VERSION ""

NS_ :

BS_:

BU_: SGW PBWM IDCM EVCU2 ECM DMPI BPCM AGSM

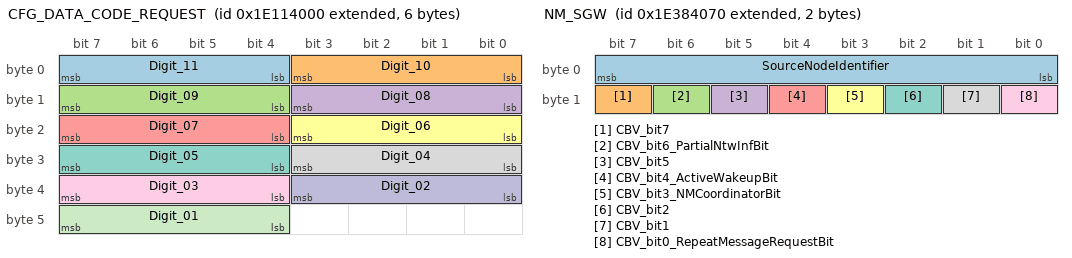
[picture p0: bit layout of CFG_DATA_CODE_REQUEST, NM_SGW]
BO_ 2651930624 CFG_DATA_CODE_REQUEST: 6 EVCU2
 SG_ Digit_11 : 7|4@0+ (1,0) [0|15] "" DMPI,PBWM
 SG_ Digit_10 : 3|4@0+ (1,0) [0|15] "" DMPI,PBWM
 SG_ Digit_09 : 15|4@0+ (1,0) [0|15] "" DMPI,PBWM
 SG_ Digit_08 : 11|4@0+ (1,0) [0|15] "" DMPI,PBWM
 SG_ Digit_07 : 23|4@0+ (1,0) [0|15] "" DMPI,PBWM
 SG_ Digit_06 : 19|4@0+ (1,0) [0|15] "" DMPI,PBWM
 SG_ Digit_05 : 31|4@0+ (1,0) [0|15] "" DMPI,PBWM
 SG_ Digit_04 : 27|4@0+ (1,0) [0|15] "" DMPI,PBWM
 SG_ Digit_03 : 39|4@0+ (1,0) [0|15] "" DMPI,PBWM
 SG_ Digit_02 : 35|4@0+ (1,0) [0|15] "" DMPI,PBWM
 SG_ Digit_01 : 47|4@0+ (1,0) [0|15] "" DMPI,PBWM

BO_ 2564554481 DIAGNOSTIC_REQUEST_FUNCTIONAL: 8 SGW
 SG_ N_PDU : 7|64@0+ (1,0) [0|0] "" DMPI,PBWM,IDCM,BPCM

BO_ 2564502513 DIAGNOSTIC_REQUEST_FUNC_OBD: 8 SGW
 SG_ N_PDU : 7|64@0+ (1,0) [0|0] "" DMPI,PBWM,EVCU2,IDCM,BPCM,ECM

BO_ 2564485444 DIAGNOSTIC_RESPONSE_BPCM: 8 BPCM
 SG_ N_PDU : 7|64@0+ (1,0) [0|0] "" SGW

BO_ 2564441329 DIAGNOSTIC_REQUEST_BPCM: 8 SGW
 SG_ N_PDU : 7|64@0+ (1,0) [0|0] "" BPCM

BO_ 2564485456 DIAGNOSTIC_RESPONSE_IDCM: 8 IDCM
 SG_ N_PDU : 7|64@0+ (1,0) [0|0] "" SGW

BO_ 2564444401 DIAGNOSTIC_REQUEST_IDCM: 8 SGW
 SG_ N_PDU : 7|64@0+ (1,0) [0|0] "" IDCM

BO_ 1053 VIN: 32 EVCU2
 SG_ VIN_MSG : 75|2@0+ (1,0) [0|3] "" IDCM
 SG_ VIN_DATA : 87|56@0+ (1,0) [0|72057594037927900] "" IDCM

BO_ 156 TELEMATIC_FD_1: 32 EVCU2
 SG_ GPS_UTC_Second : 151|16@0+ (0.01,0) [0|59.99] "s"  DMPI,IDCM,BPCM
 SG_ GPS_UTC_Minute : 47|8@0+ (1,0) [0|59] "min"  DMPI,IDCM,BPCM
 SG_ GPS_UTC_Hour : 55|8@0+ (1,0) [0|23] "h"  DMPI,IDCM,BPCM
 SG_ GPS_Date_Year : 167|16@0+ (1,0) [0|65534] "Years"  DMPI,IDCM,BPCM
 SG_ GPS_Date_Month : 71|8@0+ (1,0) [1|12] "Months"  DMPI,IDCM,BPCM
 SG_ GPS_Date_Day : 63|8@0+ (1,0) [1|31] "Days"  DMPI,IDCM,BPCM

BO_ 1058 OBD_CONTENT_FRAME: 32 ECM
 SG_ EngLoad_OBD_ePT : 31|8@0+ (0.3922,0) [0|100] "%" EVCU2
 SG_ LoadOBD : 87|8@0+ (0.3922,0) [0|100] "%"  DMPI
 SG_ CarbWarmUp : 93|1@0+ (1,0) [0|1] "-"  DMPI
 SG_ OAT_PT_EstV : 60|1@0+ (1,0) [0|0] "-"  EVCU2
 SG_ OAT_PT_Est : 55|8@0+ (1,-64) [-64|191] "°C"  EVCU2
 SG_ EngOffTmPTV : 5|1@0+ (1,0) [0|0] "-"  EVCU2
 SG_ EngOffTmPT : 3|12@0+ (0.5,0) [0.5|2047.5] "min"  EVCU2
 SG_ MessageCounter_OBDCONTENTFRAME : 179|4@0+ (1,0) [0|15] "-"  EVCU2,BPCM
 SG_ CRC_OBDCONTENTFRAME : 191|8@0+ (1,0) [0|255] "-"  EVCU2,BPCM

BO_ 1829 IPC_FD_1: 32 EVCU2
 SG_ TotalOdometer : 75|20@0+ (1,0) [0|1048575] "km"  IDCM

BO_ 1626 IMPACT_INFO: 32 EVCU2
 SG_ IMPACTConfirm : 81|1@0+ (1,0) [0|1] "-"  DMPI,IDCM,BPCM
 SG_ IMPACTCommand : 80|1@0+ (1,0) [0|1] "-"  DMPI,IDCM,BPCM
 SG_ MessageCounter_IMPACTINFO : 179|4@0+ (1,0) [0|15] "-"  DMPI,IDCM,BPCM
 SG_ CRC_IMPACTINFO : 191|8@0+ (1,0) [0|255] "-"  DMPI,IDCM,BPCM

BO_ 751 ENGINE_FD_6: 32 ECM
 SG_ EngineWaterTemp : 95|8@0+ (1,-40) [-40|215] "°C"  Vector__XXX

BO_ 518 ENGINE_FD_5: 32 ECM
 SG_ RPMOverRev_W : 115|1@0+ (1,0) [0|1] "-"  EVCU2
 SG_ MessageCounter_ENGINE5 : 179|4@0+ (1,0) [0|15] "-"  EVCU2
 SG_ ECM_READINESS_RESET_W : 140|1@0+ (1,0) [0|0] ""  DMPI,BPCM
 SG_ ECM_CODE_CLR_W : 141|1@0+ (1,0) [0|0] ""  DMPI,BPCM
 SG_ CRC_ENGINE5 : 191|8@0+ (1,0) [0|255] "-"  EVCU2

BO_ 2564485648 DIAGNOSTIC_RESPONSE_FD_ECM: 64 ECM
 SG_ N_PDU : 7|64@0+ (1,0) [0|0] "" SGW

BO_ 2564554482 DIAGNOSTIC_REQUEST_FD_FUNCTIONAL: 64 SGW
 SG_ N_PDU : 7|64@0+ (1,0) [0|0] "" DMPI,PBWM,EVCU2,IDCM,BPCM,ECM

BO_ 2564428018 DIAGNOSTIC_REQUEST_FD_ECM: 64 SGW
 SG_ N_PDU : 7|64@0+ (1,0) [0|0] "" ECM

BO_ 1066 BCM_FD_9: 32 EVCU2
 SG_ ExternalTemperature : 0|9@0+ (0.5,-85) [-85|170] "°C"  IDCM,BPCM

BO_ 1827 BCM_FD_7: 32 EVCU2
 SG_ IgnitionOnCounter : 95|16@0+ (1,0) [0|65535] "-"  IDCM,BPCM

BO_ 1153 BCM_FD_10: 32 EVCU2
 SG_ ExternalTemperatureC : 80|9@0+ (0.5,-85) [-85|170] "°C"  IDCM,BPCM
 SG_ CmdIgnSts : 138|3@0+ (1,0) [0|7] "" IDCM,BPCM

BO_ 753 LV_CHARGER1: 32 IDCM
 SG_ MessageCounter_LV_CHARGER1 : 179|4@0+ (1,0) [0|15] "-"  Vector__XXX
 SG_ CRC_LV_CHARGER1 : 191|8@0+ (1,0) [0|255] "-"  Vector__XXX
 SG_ IDCM_Wakeup_HCP : 23|1@0+ (1,0) [0|1] "-"  EVCU2

BO_ 1032 HYBRID_THERMAL_COMMAND: 32 EVCU2
 SG_ RadiatorFanSts : 78|7@0+ (1,0) [0|100] "%"  DMPI,ECM

BO_ 267 HYBRID_SYSTEM_EPT1: 32 EVCU2
 SG_ HCP_ShutdownCommand : 6|3@0+ (1,0) [0|0] "-"  BPCM
 SG_ WU_Timer_Value : 23|16@0+ (1,0) [0|65535] "min"  IDCM,BPCM
 SG_ PerWakeUp_Diag : 33|10@0+ (1,0) [0|1023] "-"  IDCM,BPCM

BO_ 1033 HYBRID_POWERTRAIN5: 32 EVCU2
 SG_ IdleCLoopTrq : 33|10@0+ (0.32,-163.52) [-163.52|163.52] "Nm"  ECM
 SG_ HEV_HybPwrtrnRdcdPerfCmnd : 22|1@0+ (1,0) [0|0] "-"  ECM
 SG_ HCPMaxEngRPM : 63|8@0+ (32,0) [0|8128] "rpm"  ECM
 SG_ MessageCounter_HYBRID_POWERTRAI : 179|4@0+ (1,0) [0|15] "-"  ECM
 SG_ CRC_HYBRID_POWERTRAIN5 : 191|8@0+ (1,0) [0|255] "-"  ECM
 SG_ Hybrid_EVT_ModeSts : 7|1@0+ (1,0) [0|1] "-"  Vector__XXX
 SG_ HCP_HoodAjar : 35|2@0+ (1,0) [0|2] "" ECM

BO_ 266 HVBATTERY1: 32 BPCM
 SG_ REPRGD_PFC_CLR_BPCM : 180|1@0+ (1,0) [0|0] "-"  ECM
 SG_ CODE_CLR_BPCM : 181|1@0+ (1,0) [0|0] "-"  ECM

BO_ 1839 HVBATTERY_RM_MODS1: 48 BPCM
 SG_ HVBatModuleTemp_16 : 127|8@0+ (1,-40) [-40|215] "°C"  SGW
 SG_ HVBatModuleTemp_15 : 119|8@0+ (1,-40) [-40|215] "°C"  SGW
 SG_ HVBatModuleTemp_14 : 111|8@0+ (1,-40) [-40|215] "°C"  SGW
 SG_ HVBatModuleTemp_13 : 103|8@0+ (1,-40) [-40|215] "°C"  SGW
 SG_ HVBatModuleTemp_12 : 95|8@0+ (1,-40) [-40|215] "°C"  SGW
 SG_ HVBatModuleTemp_11 : 87|8@0+ (1,-40) [-40|215] "°C"  SGW
 SG_ HVBatModuleTemp_10 : 79|8@0+ (1,-40) [-40|215] "°C"  SGW
 SG_ HVBatModuleTemp_09 : 71|8@0+ (1,-40) [-40|215] "°C"  SGW
 SG_ HVBatModuleTemp_08 : 63|8@0+ (1,-40) [-40|215] "°C"  SGW
 SG_ HVBatModuleTemp_07 : 55|8@0+ (1,-40) [-40|215] "°C"  SGW
 SG_ HVBatModuleTemp_06 : 47|8@0+ (1,-40) [-40|215] "°C"  SGW
 SG_ HVBatModuleTemp_05 : 39|8@0+ (1,-40) [-40|215] "°C"  SGW
 SG_ HVBatModuleTemp_04 : 31|8@0+ (1,-40) [-40|215] "°C"  SGW
 SG_ HVBatModuleTemp_03 : 23|8@0+ (1,-40) [-40|215] "°C"  SGW
 SG_ HVBatModuleTemp_02 : 15|8@0+ (1,-40) [-40|215] "°C"  SGW
 SG_ HVBatModuleTemp_01 : 7|8@0+ (1,-40) [-40|215] "°C"  SGW
 SG_ HVBatModuleTemp_38 : 303|8@0+ (1,-40) [-40|215] "°C"  Vector__XXX
 SG_ HVBatModuleTemp_37 : 295|8@0+ (1,-40) [-40|215] "°C"  Vector__XXX
 SG_ HVBatModuleTemp_36 : 287|8@0+ (1,-40) [-40|215] "°C"  Vector__XXX
 SG_ HVBatModuleTemp_35 : 279|8@0+ (1,-40) [-40|215] "°C"  Vector__XXX
 SG_ HVBatModuleTemp_34 : 271|8@0+ (1,-40) [-40|215] "°C"  Vector__XXX
 SG_ HVBatModuleTemp_33 : 263|8@0+ (1,-40) [-40|215] "°C"  Vector__XXX
 SG_ HVBatModuleTemp_32 : 255|8@0+ (1,-40) [-40|215] "°C"  Vector__XXX
 SG_ HVBatModuleTemp_31 : 247|8@0+ (1,-40) [-40|215] "°C"  Vector__XXX
 SG_ HVBatModuleTemp_30 : 239|8@0+ (1,-40) [-40|215] "°C"  Vector__XXX
 SG_ HVBatModuleTemp_29 : 231|8@0+ (1,-40) [-40|215] "°C"  Vector__XXX
 SG_ HVBatModuleTemp_28 : 223|8@0+ (1,-40) [-40|215] "°C"  Vector__XXX
 SG_ HVBatModuleTemp_27 : 215|8@0+ (1,-40) [-40|215] "°C"  Vector__XXX
 SG_ HVBatModuleTemp_26 : 207|8@0+ (1,-40) [-40|215] "°C"  Vector__XXX
 SG_ HVBatModuleTemp_25 : 199|8@0+ (1,-40) [-40|215] "°C"  Vector__XXX
 SG_ HVBatModuleTemp_24 : 191|8@0+ (1,-40) [-40|215] "°C"  Vector__XXX
 SG_ HVBatModuleTemp_23 : 183|8@0+ (1,-40) [-40|215] "°C"  Vector__XXX
 SG_ HVBatModuleTemp_22 : 175|8@0+ (1,-40) [-40|215] "°C"  Vector__XXX
 SG_ HVBatModuleTemp_21 : 167|8@0+ (1,-40) [-40|215] "°C"  Vector__XXX
 SG_ HVBatModuleTemp_20 : 159|8@0+ (1,-40) [-40|215] "°C"  Vector__XXX
 SG_ HVBatModuleTemp_19 : 151|8@0+ (1,-40) [-40|215] "°C"  Vector__XXX
 SG_ HVBatModuleTemp_18 : 143|8@0+ (1,-40) [-40|215] "°C"  Vector__XXX
 SG_ HVBatModuleTemp_17 : 135|8@0+ (1,-40) [-40|215] "°C"  Vector__XXX

BO_ 1840 HVBATTERY_RM_CHARGING1: 32 BPCM
 SG_ IsolationResistance : 7|16@0+ (1,0) [0|65534] "kOhm"  SGW
 SG_ Warning_SOCJump : 24|1@0+ (1,0) [0|1] "-"  SGW
 SG_ Warning_PackUnmatched : 27|1@0+ (1,0) [0|1] "-"  SGW
 SG_ Warning_PackUndervoltage : 19|1@0+ (1,0) [0|1] "-"  SGW
 SG_ Warning_PackTempHigh : 26|1@0+ (1,0) [0|1] "-"  EVCU2,SGW
 SG_ Warning_PackTempDiff : 25|1@0+ (1,0) [0|1] "-"  SGW
 SG_ Warning_PackOvervoltage : 20|1@0+ (1,0) [0|1] "-"  SGW
 SG_ Warning_Overcharging : 21|1@0+ (1,0) [0|1] "-"  SGW
 SG_ Warning_LowSOC : 22|1@0+ (1,0) [0|1] "-"  SGW
 SG_ Warning_Insulation : 28|1@0+ (1,0) [0|1] "-"  SGW
 SG_ Warning_HVIL : 29|1@0+ (1,0) [0|1] "-"  SGW
 SG_ Warning_HighSOC : 23|1@0+ (1,0) [0|1] "-"  SGW
 SG_ Warning_CellUndervoltage : 17|1@0+ (1,0) [0|1] "-"  SGW
 SG_ Warning_CellOvervoltage : 18|1@0+ (1,0) [0|1] "-"  SGW
 SG_ Warning_CellBalance : 16|1@0+ (1,0) [0|1] "-"  SGW
 SG_ HighestWarningLevel : 39|2@0+ (1,0) [0|3] "-"  SGW

BO_ 1838 HVBATTERY_RM_CELLS4: 64 BPCM
 SG_ HVBatCellVoltage_Cell096 : 228|13@0+ (0.001,0) [0|5] "V"  SGW
 SG_ HVBatCellVoltage_Cell095 : 212|13@0+ (0.001,0) [0|5] "V"  SGW
 SG_ HVBatCellVoltage_Cell094 : 196|13@0+ (0.001,0) [0|5] "V"  SGW
 SG_ HVBatCellVoltage_Cell093 : 180|13@0+ (0.001,0) [0|5] "V"  SGW
 SG_ HVBatCellVoltage_Cell092 : 164|13@0+ (0.001,0) [0|5] "V"  SGW
 SG_ HVBatCellVoltage_Cell091 : 148|13@0+ (0.001,0) [0|5] "V"  SGW
 SG_ HVBatCellVoltage_Cell090 : 132|13@0+ (0.001,0) [0|5] "V"  SGW
 SG_ HVBatCellVoltage_Cell089 : 116|13@0+ (0.001,0) [0|5] "V"  SGW
 SG_ HVBatCellVoltage_Cell088 : 100|13@0+ (0.001,0) [0|5] "V"  SGW
 SG_ HVBatCellVoltage_Cell087 : 84|13@0+ (0.001,0) [0|5] "V"  SGW
 SG_ HVBatCellVoltage_Cell086 : 68|13@0+ (0.001,0) [0|5] "V"  SGW
 SG_ HVBatCellVoltage_Cell085 : 52|13@0+ (0.001,0) [0|5] "V"  SGW
 SG_ HVBatCellVoltage_Cell084 : 36|13@0+ (0.001,0) [0|5] "V"  SGW
 SG_ HVBatCellVoltage_Cell083 : 20|13@0+ (0.001,0) [0|5] "V"  SGW
 SG_ HVBatCellVoltage_Cell082 : 4|13@0+ (0.001,0) [0|5] "V"  SGW
 SG_ HVBatCellVoltage_Cell108 : 420|13@0+ (0.001,0) [0|5] "V"  SGW
 SG_ HVBatCellVoltage_Cell107 : 404|13@0+ (0.001,0) [0|5] "V"  SGW
 SG_ HVBatCellVoltage_Cell106 : 388|13@0+ (0.001,0) [0|5] "V"  SGW
 SG_ HVBatCellVoltage_Cell105 : 372|13@0+ (0.001,0) [0|5] "V"  SGW
 SG_ HVBatCellVoltage_Cell104 : 356|13@0+ (0.001,0) [0|5] "V"  SGW
 SG_ HVBatCellVoltage_Cell103 : 340|13@0+ (0.001,0) [0|5] "V"  SGW
 SG_ HVBatCellVoltage_Cell102 : 324|13@0+ (0.001,0) [0|5] "V"  SGW
 SG_ HVBatCellVoltage_Cell101 : 308|13@0+ (0.001,0) [0|5] "V"  SGW
 SG_ HVBatCellVoltage_Cell100 : 292|13@0+ (0.001,0) [0|5] "V"  SGW
 SG_ HVBatCellVoltage_Cell099 : 276|13@0+ (0.001,0) [0|5] "V"  SGW
 SG_ HVBatCellVoltage_Cell098 : 260|13@0+ (0.001,0) [0|5] "V"  SGW
 SG_ HVBatCellVoltage_Cell097 : 244|13@0+ (0.001,0) [0|5] "V"  SGW

BO_ 1837 HVBATTERY_RM_CELLS3: 64 BPCM
 SG_ HVBatCellVoltage_Cell081 : 420|13@0+ (0.001,0) [0|5] "V"  SGW
 SG_ HVBatCellVoltage_Cell080 : 404|13@0+ (0.001,0) [0|5] "V"  SGW
 SG_ HVBatCellVoltage_Cell079 : 388|13@0+ (0.001,0) [0|5] "V"  SGW
 SG_ HVBatCellVoltage_Cell078 : 372|13@0+ (0.001,0) [0|5] "V"  SGW
 SG_ HVBatCellVoltage_Cell077 : 356|13@0+ (0.001,0) [0|5] "V"  SGW
 SG_ HVBatCellVoltage_Cell076 : 340|13@0+ (0.001,0) [0|5] "V"  SGW
 SG_ HVBatCellVoltage_Cell075 : 324|13@0+ (0.001,0) [0|5] "V"  SGW
 SG_ HVBatCellVoltage_Cell074 : 308|13@0+ (0.001,0) [0|5] "V"  SGW
 SG_ HVBatCellVoltage_Cell073 : 292|13@0+ (0.001,0) [0|5] "V"  SGW
 SG_ HVBatCellVoltage_Cell072 : 276|13@0+ (0.001,0) [0|5] "V"  SGW
 SG_ HVBatCellVoltage_Cell071 : 260|13@0+ (0.001,0) [0|5] "V"  SGW
 SG_ HVBatCellVoltage_Cell070 : 244|13@0+ (0.001,0) [0|5] "V"  SGW
 SG_ HVBatCellVoltage_Cell069 : 228|13@0+ (0.001,0) [0|5] "V"  SGW
 SG_ HVBatCellVoltage_Cell068 : 212|13@0+ (0.001,0) [0|5] "V"  SGW
 SG_ HVBatCellVoltage_Cell067 : 196|13@0+ (0.001,0) [0|5] "V"  SGW
 SG_ HVBatCellVoltage_Cell066 : 180|13@0+ (0.001,0) [0|5] "V"  SGW
 SG_ HVBatCellVoltage_Cell065 : 164|13@0+ (0.001,0) [0|5] "V"  SGW
 SG_ HVBatCellVoltage_Cell064 : 148|13@0+ (0.001,0) [0|5] "V"  SGW
 SG_ HVBatCellVoltage_Cell063 : 132|13@0+ (0.001,0) [0|5] "V"  SGW
 SG_ HVBatCellVoltage_Cell062 : 116|13@0+ (0.001,0) [0|5] "V"  SGW
 SG_ HVBatCellVoltage_Cell061 : 100|13@0+ (0.001,0) [0|5] "V"  SGW
 SG_ HVBatCellVoltage_Cell060 : 84|13@0+ (0.001,0) [0|5] "V"  SGW
 SG_ HVBatCellVoltage_Cell059 : 68|13@0+ (0.001,0) [0|5] "V"  SGW
 SG_ HVBatCellVoltage_Cell058 : 52|13@0+ (0.001,0) [0|5] "V"  SGW
 SG_ HVBatCellVoltage_Cell057 : 36|13@0+ (0.001,0) [0|5] "V"  SGW
 SG_ HVBatCellVoltage_Cell056 : 20|13@0+ (0.001,0) [0|5] "V"  SGW
 SG_ HVBatCellVoltage_Cell055 : 4|13@0+ (0.001,0) [0|5] "V"  SGW

BO_ 1836 HVBATTERY_RM_CELLS2: 64 BPCM
 SG_ HVBatCellVoltage_Cell054 : 420|13@0+ (0.001,0) [0|5] "V"  SGW
 SG_ HVBatCellVoltage_Cell053 : 404|13@0+ (0.001,0) [0|5] "V"  SGW
 SG_ HVBatCellVoltage_Cell052 : 388|13@0+ (0.001,0) [0|5] "V"  SGW
 SG_ HVBatCellVoltage_Cell051 : 372|13@0+ (0.001,0) [0|5] "V"  SGW
 SG_ HVBatCellVoltage_Cell050 : 356|13@0+ (0.001,0) [0|5] "V"  SGW
 SG_ HVBatCellVoltage_Cell049 : 340|13@0+ (0.001,0) [0|5] "V"  SGW
 SG_ HVBatCellVoltage_Cell048 : 324|13@0+ (0.001,0) [0|5] "V"  SGW
 SG_ HVBatCellVoltage_Cell047 : 308|13@0+ (0.001,0) [0|5] "V"  SGW
 SG_ HVBatCellVoltage_Cell046 : 292|13@0+ (0.001,0) [0|5] "V"  SGW
 SG_ HVBatCellVoltage_Cell045 : 276|13@0+ (0.001,0) [0|5] "V"  SGW
 SG_ HVBatCellVoltage_Cell044 : 260|13@0+ (0.001,0) [0|5] "V"  SGW
 SG_ HVBatCellVoltage_Cell043 : 244|13@0+ (0.001,0) [0|5] "V"  SGW
 SG_ HVBatCellVoltage_Cell042 : 228|13@0+ (0.001,0) [0|5] "V"  SGW
 SG_ HVBatCellVoltage_Cell041 : 212|13@0+ (0.001,0) [0|5] "V"  SGW
 SG_ HVBatCellVoltage_Cell040 : 196|13@0+ (0.001,0) [0|5] "V"  SGW
 SG_ HVBatCellVoltage_Cell039 : 180|13@0+ (0.001,0) [0|5] "V"  SGW
 SG_ HVBatCellVoltage_Cell038 : 164|13@0+ (0.001,0) [0|5] "V"  SGW
 SG_ HVBatCellVoltage_Cell037 : 148|13@0+ (0.001,0) [0|5] "V"  SGW
 SG_ HVBatCellVoltage_Cell036 : 132|13@0+ (0.001,0) [0|5] "V"  SGW
 SG_ HVBatCellVoltage_Cell035 : 116|13@0+ (0.001,0) [0|5] "V"  SGW
 SG_ HVBatCellVoltage_Cell034 : 100|13@0+ (0.001,0) [0|5] "V"  SGW
 SG_ HVBatCellVoltage_Cell033 : 84|13@0+ (0.001,0) [0|5] "V"  SGW
 SG_ HVBatCellVoltage_Cell032 : 68|13@0+ (0.001,0) [0|5] "V"  SGW
 SG_ HVBatCellVoltage_Cell031 : 52|13@0+ (0.001,0) [0|5] "V"  SGW
 SG_ HVBatCellVoltage_Cell030 : 36|13@0+ (0.001,0) [0|5] "V"  SGW
 SG_ HVBatCellVoltage_Cell029 : 20|13@0+ (0.001,0) [0|5] "V"  SGW
 SG_ HVBatCellVoltage_Cell028 : 4|13@0+ (0.001,0) [0|5] "V"  SGW

BO_ 1835 HVBATTERY_RM_CELLS1: 64 BPCM
 SG_ HVBatCellVoltage_Cell027 : 420|13@0+ (0.001,0) [0|5] "V"  SGW
 SG_ HVBatCellVoltage_Cell026 : 404|13@0+ (0.001,0) [0|5] "V"  SGW
 SG_ HVBatCellVoltage_Cell025 : 388|13@0+ (0.001,0) [0|5] "V"  SGW
 SG_ HVBatCellVoltage_Cell024 : 372|13@0+ (0.001,0) [0|5] "V"  SGW
 SG_ HVBatCellVoltage_Cell023 : 356|13@0+ (0.001,0) [0|5] "V"  SGW
 SG_ HVBatCellVoltage_Cell022 : 340|13@0+ (0.001,0) [0|5] "V"  SGW
 SG_ HVBatCellVoltage_Cell021 : 324|13@0+ (0.001,0) [0|5] "V"  SGW
 SG_ HVBatCellVoltage_Cell020 : 308|13@0+ (0.001,0) [0|5] "V"  SGW
 SG_ HVBatCellVoltage_Cell019 : 292|13@0+ (0.001,0) [0|5] "V"  SGW
 SG_ HVBatCellVoltage_Cell018 : 276|13@0+ (0.001,0) [0|5] "V"  SGW
 SG_ HVBatCellVoltage_Cell017 : 260|13@0+ (0.001,0) [0|5] "V"  SGW
 SG_ HVBatCellVoltage_Cell016 : 244|13@0+ (0.001,0) [0|5] "V"  SGW
 SG_ HVBatCellVoltage_Cell015 : 228|13@0+ (0.001,0) [0|5] "V"  SGW
 SG_ HVBatCellVoltage_Cell014 : 212|13@0+ (0.001,0) [0|5] "V"  SGW
 SG_ HVBatCellVoltage_Cell013 : 196|13@0+ (0.001,0) [0|5] "V"  SGW
 SG_ HVBatCellVoltage_Cell012 : 180|13@0+ (0.001,0) [0|5] "V"  SGW
 SG_ HVBatCellVoltage_Cell011 : 164|13@0+ (0.001,0) [0|5] "V"  SGW
 SG_ HVBatCellVoltage_Cell010 : 148|13@0+ (0.001,0) [0|5] "V"  SGW
 SG_ HVBatCellVoltage_Cell009 : 132|13@0+ (0.001,0) [0|5] "V"  SGW
 SG_ HVBatCellVoltage_Cell008 : 116|13@0+ (0.001,0) [0|5] "V"  SGW
 SG_ HVBatCellVoltage_Cell007 : 100|13@0+ (0.001,0) [0|5] "V"  SGW
 SG_ HVBatCellVoltage_Cell006 : 84|13@0+ (0.001,0) [0|5] "V"  SGW
 SG_ HVBatCellVoltage_Cell005 : 68|13@0+ (0.001,0) [0|5] "V"  SGW
 SG_ HVBatCellVoltage_Cell004 : 52|13@0+ (0.001,0) [0|5] "V"  SGW
 SG_ HVBatCellVoltage_Cell003 : 36|13@0+ (0.001,0) [0|5] "V"  SGW
 SG_ HVBatCellVoltage_Cell002 : 20|13@0+ (0.001,0) [0|5] "V"  SGW
 SG_ HVBatCellVoltage_Cell001 : 4|13@0+ (0.001,0) [0|5] "V"  SGW

BO_ 1328 ENGINE_HYBD_FD_4: 32 ECM
 SG_ EngTorqCapbltyMinTorq : 51|12@0+ (0.32,-300.16) [-300.16|1008] "Nm"  EVCU2
 SG_ EngTorqCapbltyMaxTorq : 19|12@0+ (0.32,-300.16) [-300.16|1008] "Nm"  EVCU2
 SG_ EngTorqCapbltyMaxOffTorq : 3|12@0+ (0.32,-300.16) [-300.16|1008] "Nm"  EVCU2
 SG_ EngTorqCapbltyRefEngSpd : 71|8@0+ (32,0) [0|8160] "rpm"  EVCU2
 SG_ EngTorqCapbltyMinRunTorq : 35|12@0+ (0.32,-300.16) [-300.16|1008] "Nm"  EVCU2
 SG_ EngTorqCapbltyFrmCntr : 7|4@0+ (1,0) [0|15] "-"  EVCU2
 SG_ EngTorqACCCapability : 79|8@0+ (0.32,0) [0|81.28] "Nm"  EVCU2
 SG_ CatHtgStateActive : 20|1@0+ (1,0) [0|0] "-"  EVCU2
 SG_ MessageCounter_ENGINE_HYBD_FD_4 : 179|4@0+ (1,0) [0|15] "-"  EVCU2
 SG_ CRC_ENGINE_HYBD_FD_4 : 191|8@0+ (1,0) [0|255] "-"  EVCU2
 SG_ CatTempMaint : 23|1@0+ (1,0) [0|1] "-"  EVCU2

BO_ 1035 ENGINE_HYBD_FD_3: 32 ECM
 SG_ MaxEngSpdCap : 52|13@0+ (1,0) [0|8160] "rpm"  EVCU2
 SG_ ServiceHybSys : 55|1@0+ (1,0) [0|0] "-"  EVCU2
 SG_ PECP_PumpFlowReq : 150|7@0+ (1,0) [0|100] "%"  EVCU2
 SG_ MinEngSpdCap : 68|13@0+ (1,0) [0|8160] "rpm"  EVCU2
 SG_ EngSpdStat : 38|2@0+ (1,0) [0|0] "-"  EVCU2
 SG_ EngSpd : 7|16@0+ (0.125,0) [0|8160] "rpm"  EVCU2
 SG_ EngOutofFuel : 151|1@0+ (1,0) [0|0] "-"  EVCU2
 SG_ EngCltTmpV : 69|1@0+ (1,0) [0|1] "" DMPI,EVCU2,BPCM
 SG_ EngCltTmp : 167|8@0+ (1,-40) [-40|214] "°C"  DMPI,EVCU2,BPCM
 SG_ MessageCounter_ENGINE_HYBD_FD_3 : 179|4@0+ (1,0) [0|15] "-"  EVCU2
 SG_ CRC_ENGINE_HYBD_FD_3 : 191|8@0+ (1,0) [0|255] "-"  EVCU2
 SG_ ECM_AirflowRequest : 87|7@0+ (1,0) [0|127] "%"  EVCU2

BO_ 1036 ENGINE_FD_3: 32 ECM
 SG_ EngineOilTemperature : 103|8@0+ (1,-40) [-40|214] "°C"  Vector__XXX

BO_ 750 BCM_FD_3: 32 EVCU2
 SG_ Battery_Volt_1 : 56|9@0+ (0.025,5) [5|17.75] "Volt"  IDCM,BPCM

BO_ 2654486640 NM_SGW: 2 SGW
 SG_ SourceNodeIdentifier : 7|8@0+ (1,0) [0|255] "-"  DMPI,PBWM,EVCU2,IDCM,BPCM,ECM
 SG_ CBV_bit7 : 15|1@0+ (1,0) [0|1] "" DMPI,PBWM,EVCU2,IDCM,BPCM,ECM
 SG_ CBV_bit6_PartialNtwInfBit : 14|1@0+ (1,0) [0|1] "" DMPI,PBWM,EVCU2,IDCM,BPCM,ECM
 SG_ CBV_bit5 : 13|1@0+ (1,0) [0|1] "" DMPI,PBWM,EVCU2,IDCM,BPCM,ECM
 SG_ CBV_bit4_ActiveWakeupBit : 12|1@0+ (1,0) [0|1] "" DMPI,PBWM,EVCU2,IDCM,BPCM,ECM
 SG_ CBV_bit3_NMCoordinatorBit : 11|1@0+ (1,0) [0|1] "" DMPI,PBWM,EVCU2,IDCM,BPCM,ECM
 SG_ CBV_bit2 : 10|1@0+ (1,0) [0|1] "" DMPI,PBWM,EVCU2,IDCM,BPCM,ECM
 SG_ CBV_bit1 : 9|1@0+ (1,0) [0|1] "" DMPI,PBWM,EVCU2,IDCM,BPCM,ECM
 SG_ CBV_bit0_RepeatMessageRequestBit : 8|1@0+ (1,0) [0|1] "" DMPI,PBWM,EVCU2,IDCM,BPCM,ECM

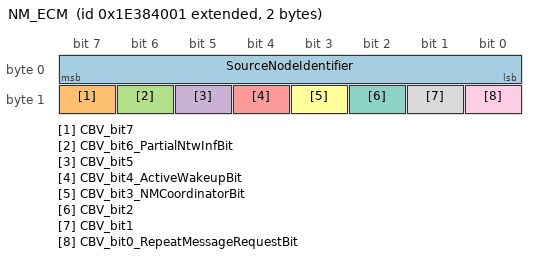
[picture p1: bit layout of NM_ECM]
BO_ 2654486529 NM_ECM: 2 ECM
 SG_ SourceNodeIdentifier : 7|8@0+ (1,0) [0|255] "-"  DMPI,PBWM,EVCU2,IDCM,SGW,BPCM
 SG_ CBV_bit7 : 15|1@0+ (1,0) [0|1] "" DMPI,PBWM,EVCU2,IDCM,SGW,BPCM
 SG_ CBV_bit6_PartialNtwInfBit : 14|1@0+ (1,0) [0|1] "" DMPI,PBWM,EVCU2,IDCM,SGW,BPCM
 SG_ CBV_bit5 : 13|1@0+ (1,0) [0|1] "" DMPI,PBWM,EVCU2,IDCM,SGW,BPCM
 SG_ CBV_bit4_ActiveWakeupBit : 12|1@0+ (1,0) [0|1] "" DMPI,PBWM,EVCU2,IDCM,SGW,BPCM
 SG_ CBV_bit3_NMCoordinatorBit : 11|1@0+ (1,0) [0|1] "" DMPI,PBWM,EVCU2,IDCM,SGW,BPCM
 SG_ CBV_bit2 : 10|1@0+ (1,0) [0|1] "" DMPI,PBWM,EVCU2,IDCM,SGW,BPCM
 SG_ CBV_bit1 : 9|1@0+ (1,0) [0|1] "" DMPI,PBWM,EVCU2,IDCM,SGW,BPCM
 SG_ CBV_bit0_RepeatMessageRequestBit : 8|1@0+ (1,0) [0|1] "" DMPI,PBWM,EVCU2,IDCM,SGW,BPCM

BO_ 269 HYBRID_POWERTRAIN2: 64 EVCU2
 SG_ MessageCounter_HYBRID_POWERTRAI : 435|4@0+ (1,0) [0|15] "-"  ECM
 SG_ IdleSpeedActiveSts : 302|1@0+ (1,0) [0|0] "-"  ECM
 SG_ CRC_HYBRID_POWERTRAIN2 : 447|8@0+ (1,0) [0|255] "-"  ECM
 SG_ PropulsionMode : 39|3@0+ (1,0) [0|6] "-"  ECM
 SG_ HybridEngineMaxTorqAllowed : 115|12@0+ (0.32,-300.16) [-300.16|1008] "Nm"  ECM
 SG_ REPRGD_PFC_CLR_HCP : 303|1@0+ (1,0) [0|1] "-"  ECM
 SG_ CODE_CLR_HCP : 288|1@0+ (1,0) [0|1] "-"  ECM

CM_ "Project_KM_ProjectStandard_FD-CAN11 [CS00155_FD]";
CM_ SG_ 2564554481 N_PDU "This signal is used for diagnostic purposes";
CM_ SG_ 2564502513 N_PDU "This signal is used for diagnostic purposes";
CM_ SG_ 2564485444 N_PDU "This signal is used for diagnostic purposes";
CM_ SG_ 2564441329 N_PDU "This signal is used for diagnostic purposes";
CM_ SG_ 2564485456 N_PDU "This signal is used for diagnostic purposes";
CM_ SG_ 2564444401 N_PDU "This signal is used for diagnostic purposes";
CM_ SG_ 1053 VIN_DATA "VIN Digits (8 bit ascii encoded)";
CM_ SG_ 1053 VIN_MSG "VIN Message Information";
CM_ SG_ 156 GPS_UTC_Second "GPS UTC second";
CM_ SG_ 156 GPS_UTC_Minute "GPS UTC minute";
CM_ SG_ 156 GPS_UTC_Hour "GPS UTC hour";
CM_ SG_ 156 GPS_Date_Year "GPS date year";
CM_ SG_ 156 GPS_Date_Month "GPS date month";
CM_ SG_ 156 GPS_Date_Day "GPS date day";
CM_ SG_ 1058 OAT_PT_EstV "Outside air temperature powertrain estimated validity; Invalid = [1]";
CM_ SG_ 1058 OAT_PT_Est "Outside air temperature powertrain estimated";
CM_ SG_ 1058 MessageCounter_OBDCONTENTFRAME "This signal is a counter used for safety checks strategies. This counter is incremented of 1 (one) unit at each frame transmission.";
CM_ SG_ 1058 LoadOBD "Engine calculated load value in percentage of load.";
CM_ SG_ 1058 EngLoad_OBD_ePT "Load value for OBD (ISO 15031-5.4 PID 4)";
CM_ SG_ 1058 EngOffTmPTV "Engine off time powertrain validity (1=invalid)";
CM_ SG_ 1058 EngOffTmPT "Engine off time powertrain";
CM_ SG_ 1058 CRC_OBDCONTENTFRAME "CRC according to SAE J1850 standard at each frame transmission.";
CM_ SG_ 1058 CarbWarmUp "CARB warmup criteria true.  The engine controller will set this bit when the engine coolant temp achieves the CARB warm-up criteria.";
CM_ SG_ 1829 TotalOdometer "Used to give information about the total odometer value in km.";
CM_ SG_ 1626 IMPACTConfirm "This signal is used to confirm that a crash happened";
CM_ SG_ 1626 IMPACTCommand "This signal is used to indicate that a crash happened";
CM_ SG_ 1626 CRC_IMPACTINFO "CRC according to SAE J1850 standard at each frame transmission.";
CM_ SG_ 1626 MessageCounter_IMPACTINFO "This signal is a counter used for safety checks strategies. This counter is incremented of 1 (one) unit at each frame transmission.";
CM_ SG_ 751 EngineWaterTemp "-";
CM_ SG_ 518 RPMOverRev_W "-";
CM_ SG_ 518 MessageCounter_ENGINE5 "This signal is a counter used for safety checks strategies. This counter is incremented of 1 (one) unit at each frame transmission.";
CM_ SG_ 518 ECM_READINESS_RESET_W "Handshake for not to send";
CM_ SG_ 518 ECM_CODE_CLR_W "Handshake for not to send";
CM_ SG_ 518 CRC_ENGINE5 "CRC according to SAE J1850 standard at each frame transmission.";
CM_ SG_ 2564485648 N_PDU "This signal is used for diagnostic purposes";
CM_ SG_ 2564554482 N_PDU "This signal is used for diagnostic purposes";
CM_ SG_ 2564428018 N_PDU "This signal is used for diagnostic purposes";
CM_ SG_ 1153 ExternalTemperatureC "Used to indicate the external temperature value in °C";
CM_ SG_ 1153 CmdIgnSts "Used to give information about the key selector position";
CM_ SG_ 753 MessageCounter_LV_CHARGER1 "This signal is a counter used for safety checks strategies. This counter is incremented of 1 (one) unit at each frame transmission.";
CM_ SG_ 753 IDCM_Wakeup_HCP "IDCM wakeup event for charging";
CM_ SG_ 753 CRC_LV_CHARGER1 "CRC according to SAE J1850 standard at each frame transmission.";
CM_ SG_ 1032 RadiatorFanSts "Radiator Fan state";
CM_ SG_ 267 WU_Timer_Value "HCP wake-up timer value";
CM_ SG_ 267 PerWakeUp_Diag "Periodic wakeup diagnostics";
CM_ SG_ 267 HCP_ShutdownCommand "HCP System Shutdown Command";
CM_ SG_ 1033 MessageCounter_HYBRID_POWERTRAI "This signal is a counter used for safety checks strategies. This counter is incremented of 1 (one) unit at each frame transmission.";
CM_ SG_ 1033 IdleCLoopTrq "Electric motor PID torque to maintain idle speed.";
CM_ SG_ 1033 Hybrid_EVT_ModeSts "The system is in EVT mode; Hybrid mode = [0], EV Mode = [1]";
CM_ SG_ 1033 HEV_HybPwrtrnRdcdPerfCmnd "Driver torque request modifier due to system remedial acion";
CM_ SG_ 1033 HCPMaxEngRPM "Engine rev limit due to HCP/MGU limits";
CM_ SG_ 1033 HCP_HoodAjar "Diagnosed hood status for HVIL";
CM_ SG_ 1033 CRC_HYBRID_POWERTRAIN5 "CRC according to SAE J1850 standard at each frame transmission.";
CM_ SG_ 266 REPRGD_PFC_CLR_BPCM "Set readiness to 'incomplete' ; [0] = Do nothing, [1] = Set incomplete";
CM_ SG_ 266 CODE_CLR_BPCM "Clear emission related faults; [0] = not clear; [1] = Clear";
CM_ SG_ 1839 HVBatModuleTemp_38 "High voltage battery module temperature";
CM_ SG_ 1839 HVBatModuleTemp_37 "High voltage battery module temperature";
CM_ SG_ 1839 HVBatModuleTemp_36 "High voltage battery module temperature";
CM_ SG_ 1839 HVBatModuleTemp_35 "High voltage battery module temperature";
CM_ SG_ 1839 HVBatModuleTemp_34 "High voltage battery module temperature";
CM_ SG_ 1839 HVBatModuleTemp_33 "High voltage battery module temperature";
CM_ SG_ 1839 HVBatModuleTemp_32 "High voltage battery module temperature";
CM_ SG_ 1839 HVBatModuleTemp_31 "High voltage battery module temperature";
CM_ SG_ 1839 HVBatModuleTemp_30 "High voltage battery module temperature";
CM_ SG_ 1839 HVBatModuleTemp_29 "High voltage battery module temperature";
CM_ SG_ 1839 HVBatModuleTemp_28 "High voltage battery module temperature";
CM_ SG_ 1839 HVBatModuleTemp_27 "High voltage battery module temperature";
CM_ SG_ 1839 HVBatModuleTemp_26 "High voltage battery module temperature";
CM_ SG_ 1839 HVBatModuleTemp_25 "High voltage battery module temperature";
CM_ SG_ 1839 HVBatModuleTemp_24 "High voltage battery module temperature";
CM_ SG_ 1839 HVBatModuleTemp_23 "High voltage battery module temperature";
CM_ SG_ 1839 HVBatModuleTemp_22 "High voltage battery module temperature";
CM_ SG_ 1839 HVBatModuleTemp_21 "High voltage battery module temperature";
CM_ SG_ 1839 HVBatModuleTemp_20 "High voltage battery module temperature";
CM_ SG_ 1839 HVBatModuleTemp_19 "High voltage battery module temperature";
CM_ SG_ 1839 HVBatModuleTemp_18 "High voltage battery module temperature";
CM_ SG_ 1839 HVBatModuleTemp_17 "High voltage battery module temperature";
CM_ SG_ 1839 HVBatModuleTemp_16 "High voltage battery module temperature";
CM_ SG_ 1839 HVBatModuleTemp_15 "High voltage battery module temperature";
CM_ SG_ 1839 HVBatModuleTemp_14 "High voltage battery module temperature";
CM_ SG_ 1839 HVBatModuleTemp_13 "High voltage battery module temperature";
CM_ SG_ 1839 HVBatModuleTemp_12 "High voltage battery module temperature";
CM_ SG_ 1839 HVBatModuleTemp_11 "High voltage battery module temperature";
CM_ SG_ 1839 HVBatModuleTemp_10 "High voltage battery module temperature";
CM_ SG_ 1839 HVBatModuleTemp_09 "High voltage battery module temperature";
CM_ SG_ 1839 HVBatModuleTemp_08 "High voltage battery module temperature";
CM_ SG_ 1839 HVBatModuleTemp_07 "High voltage battery module temperature";
CM_ SG_ 1839 HVBatModuleTemp_06 "High voltage battery module temperature";
CM_ SG_ 1839 HVBatModuleTemp_05 "High voltage battery module temperature";
CM_ SG_ 1839 HVBatModuleTemp_04 "High voltage battery module temperature";
CM_ SG_ 1839 HVBatModuleTemp_03 "High voltage battery module temperature";
CM_ SG_ 1839 HVBatModuleTemp_02 "High voltage battery module temperature";
CM_ SG_ 1839 HVBatModuleTemp_01 "High voltage battery module temperature";
CM_ SG_ 1840 Warning_SOCJump "Battery SOC jump warning";
CM_ SG_ 1840 Warning_PackUnmatched "Battery unmatched warning";
CM_ SG_ 1840 Warning_PackUndervoltage "Battery undervoltage warning";
CM_ SG_ 1840 Warning_PackTempHigh "Battery high temperature warning";
CM_ SG_ 1840 Warning_PackTempDiff "Temperature difference warning";
CM_ SG_ 1840 Warning_PackOvervoltage "Battery overvoltage warning";
CM_ SG_ 1840 Warning_Overcharging "Overcharge warning";
CM_ SG_ 1840 Warning_LowSOC "Battery low SOC warning";
CM_ SG_ 1840 Warning_Insulation "Insulation warning";
CM_ SG_ 1840 Warning_HVIL "HV interlock state warning";
CM_ SG_ 1840 Warning_HighSOC "Battery high SOC warning";
CM_ SG_ 1840 Warning_CellUndervoltage "Cell undervoltage warning";
CM_ SG_ 1840 Warning_CellOvervoltage "Cell overvoltage warning";
CM_ SG_ 1840 Warning_CellBalance "Poor cell consistency warning";
CM_ SG_ 1840 IsolationResistance "Insulation resistance";
CM_ SG_ 1840 HighestWarningLevel "Highest warning level detected";
CM_ SG_ 1838 HVBatCellVoltage_Cell108 "High voltage battery cell voltage for Cell 108";
CM_ SG_ 1838 HVBatCellVoltage_Cell107 "High voltage battery cell voltage for Cell 107";
CM_ SG_ 1838 HVBatCellVoltage_Cell106 "High voltage battery cell voltage for Cell 106";
CM_ SG_ 1838 HVBatCellVoltage_Cell105 "High voltage battery cell voltage for Cell 105";
CM_ SG_ 1838 HVBatCellVoltage_Cell104 "High voltage battery cell voltage for Cell 104";
CM_ SG_ 1838 HVBatCellVoltage_Cell103 "High voltage battery cell voltage for Cell 103";
CM_ SG_ 1838 HVBatCellVoltage_Cell102 "High voltage battery cell voltage for Cell 102";
CM_ SG_ 1838 HVBatCellVoltage_Cell101 "High voltage battery cell voltage for Cell 101";
CM_ SG_ 1838 HVBatCellVoltage_Cell100 "High voltage battery cell voltage for Cell 100";
CM_ SG_ 1838 HVBatCellVoltage_Cell099 "High voltage battery cell voltage for Cell 99";
CM_ SG_ 1838 HVBatCellVoltage_Cell098 "High voltage battery cell voltage for Cell 98";
CM_ SG_ 1838 HVBatCellVoltage_Cell097 "High voltage battery cell voltage for Cell 97";
CM_ SG_ 1838 HVBatCellVoltage_Cell096 "High voltage battery cell voltage for Cell 96";
CM_ SG_ 1838 HVBatCellVoltage_Cell095 "High voltage battery cell voltage for Cell 95";
CM_ SG_ 1838 HVBatCellVoltage_Cell094 "High voltage battery cell voltage for Cell 94";
CM_ SG_ 1838 HVBatCellVoltage_Cell093 "High voltage battery cell voltage for Cell 93";
CM_ SG_ 1838 HVBatCellVoltage_Cell092 "High voltage battery cell voltage for Cell 92";
CM_ SG_ 1838 HVBatCellVoltage_Cell091 "High voltage battery cell voltage for Cell 91";
CM_ SG_ 1838 HVBatCellVoltage_Cell090 "High voltage battery cell voltage for Cell 90";
CM_ SG_ 1838 HVBatCellVoltage_Cell089 "High voltage battery cell voltage for Cell 89";
CM_ SG_ 1838 HVBatCellVoltage_Cell088 "High voltage battery cell voltage for Cell 88";
CM_ SG_ 1838 HVBatCellVoltage_Cell087 "High voltage battery cell voltage for Cell 87";
CM_ SG_ 1838 HVBatCellVoltage_Cell086 "High voltage battery cell voltage for Cell 86";
CM_ SG_ 1838 HVBatCellVoltage_Cell085 "High voltage battery cell voltage for Cell 85";
CM_ SG_ 1838 HVBatCellVoltage_Cell084 "High voltage battery cell voltage for Cell 84";
CM_ SG_ 1838 HVBatCellVoltage_Cell083 "High voltage battery cell voltage for Cell 83";
CM_ SG_ 1838 HVBatCellVoltage_Cell082 "High voltage battery cell voltage for Cell 82";
CM_ SG_ 1837 HVBatCellVoltage_Cell081 "High voltage battery cell voltage for Cell 81";
CM_ SG_ 1837 HVBatCellVoltage_Cell080 "High voltage battery cell voltage for Cell 80";
CM_ SG_ 1837 HVBatCellVoltage_Cell079 "High voltage battery cell voltage for Cell 79";
CM_ SG_ 1837 HVBatCellVoltage_Cell078 "High voltage battery cell voltage for Cell 78";
CM_ SG_ 1837 HVBatCellVoltage_Cell077 "High voltage battery cell voltage for Cell 77";
CM_ SG_ 1837 HVBatCellVoltage_Cell076 "High voltage battery cell voltage for Cell 76";
CM_ SG_ 1837 HVBatCellVoltage_Cell075 "High voltage battery cell voltage for Cell 75";
CM_ SG_ 1837 HVBatCellVoltage_Cell074 "High voltage battery cell voltage for Cell 74";
CM_ SG_ 1837 HVBatCellVoltage_Cell073 "High voltage battery cell voltage for Cell 73";
CM_ SG_ 1837 HVBatCellVoltage_Cell072 "High voltage battery cell voltage for Cell 72";
CM_ SG_ 1837 HVBatCellVoltage_Cell071 "High voltage battery cell voltage for Cell 71";
CM_ SG_ 1837 HVBatCellVoltage_Cell070 "High voltage battery cell voltage for Cell 70";
CM_ SG_ 1837 HVBatCellVoltage_Cell069 "High voltage battery cell voltage for Cell 69";
CM_ SG_ 1837 HVBatCellVoltage_Cell068 "High voltage battery cell voltage for Cell 68";
CM_ SG_ 1837 HVBatCellVoltage_Cell067 "High voltage battery cell voltage for Cell 67";
CM_ SG_ 1837 HVBatCellVoltage_Cell066 "High voltage battery cell voltage for Cell 66";
CM_ SG_ 1837 HVBatCellVoltage_Cell065 "High voltage battery cell voltage for Cell 65";
CM_ SG_ 1837 HVBatCellVoltage_Cell064 "High voltage battery cell voltage for Cell 64";
CM_ SG_ 1837 HVBatCellVoltage_Cell063 "High voltage battery cell voltage for Cell 63";
CM_ SG_ 1837 HVBatCellVoltage_Cell062 "High voltage battery cell voltage for Cell 62";
CM_ SG_ 1837 HVBatCellVoltage_Cell061 "High voltage battery cell voltage for Cell 61";
CM_ SG_ 1837 HVBatCellVoltage_Cell060 "High voltage battery cell voltage for Cell 60";
CM_ SG_ 1837 HVBatCellVoltage_Cell059 "High voltage battery cell voltage for Cell 59";
CM_ SG_ 1837 HVBatCellVoltage_Cell058 "High voltage battery cell voltage for Cell 58";
CM_ SG_ 1837 HVBatCellVoltage_Cell057 "High voltage battery cell voltage for Cell 57";
CM_ SG_ 1837 HVBatCellVoltage_Cell056 "High voltage battery cell voltage for Cell 56";
CM_ SG_ 1837 HVBatCellVoltage_Cell055 "High voltage battery cell voltage for Cell 55";
CM_ SG_ 1836 HVBatCellVoltage_Cell054 "High voltage battery cell voltage for Cell 54";
CM_ SG_ 1836 HVBatCellVoltage_Cell053 "High voltage battery cell voltage for Cell 53";
CM_ SG_ 1836 HVBatCellVoltage_Cell052 "High voltage battery cell voltage for Cell 52";
CM_ SG_ 1836 HVBatCellVoltage_Cell051 "High voltage battery cell voltage for Cell 51";
CM_ SG_ 1836 HVBatCellVoltage_Cell050 "High voltage battery cell voltage for Cell 50";
CM_ SG_ 1836 HVBatCellVoltage_Cell049 "High voltage battery cell voltage for Cell 49";
CM_ SG_ 1836 HVBatCellVoltage_Cell048 "High voltage battery cell voltage for Cell 48";
CM_ SG_ 1836 HVBatCellVoltage_Cell047 "High voltage battery cell voltage for Cell 47";
CM_ SG_ 1836 HVBatCellVoltage_Cell046 "High voltage battery cell voltage for Cell 46";
CM_ SG_ 1836 HVBatCellVoltage_Cell045 "High voltage battery cell voltage for Cell 45";
CM_ SG_ 1836 HVBatCellVoltage_Cell044 "High voltage battery cell voltage for Cell 44";
CM_ SG_ 1836 HVBatCellVoltage_Cell043 "High voltage battery cell voltage for Cell 43";
CM_ SG_ 1836 HVBatCellVoltage_Cell042 "High voltage battery cell voltage for Cell 42";
CM_ SG_ 1836 HVBatCellVoltage_Cell041 "High voltage battery cell voltage for Cell 41";
CM_ SG_ 1836 HVBatCellVoltage_Cell040 "High voltage battery cell voltage for Cell 40";
CM_ SG_ 1836 HVBatCellVoltage_Cell039 "High voltage battery cell voltage for Cell 39";
CM_ SG_ 1836 HVBatCellVoltage_Cell038 "High voltage battery cell voltage for Cell 38";
CM_ SG_ 1836 HVBatCellVoltage_Cell037 "High voltage battery cell voltage for Cell 37";
CM_ SG_ 1836 HVBatCellVoltage_Cell036 "High voltage battery cell voltage for Cell 36";
CM_ SG_ 1836 HVBatCellVoltage_Cell035 "High voltage battery cell voltage for Cell 35";
CM_ SG_ 1836 HVBatCellVoltage_Cell034 "High voltage battery cell voltage for Cell 34";
CM_ SG_ 1836 HVBatCellVoltage_Cell033 "High voltage battery cell voltage for Cell 33";
CM_ SG_ 1836 HVBatCellVoltage_Cell032 "High voltage battery cell voltage for Cell 32";
CM_ SG_ 1836 HVBatCellVoltage_Cell031 "High voltage battery cell voltage for Cell 31";
CM_ SG_ 1836 HVBatCellVoltage_Cell030 "High voltage battery cell voltage for Cell 30";
CM_ SG_ 1836 HVBatCellVoltage_Cell029 "High voltage battery cell voltage for Cell 29";
CM_ SG_ 1836 HVBatCellVoltage_Cell028 "High voltage battery cell voltage for Cell 28";
CM_ SG_ 1835 HVBatCellVoltage_Cell027 "High voltage battery cell voltage for Cell 27";
CM_ SG_ 1835 HVBatCellVoltage_Cell026 "High voltage battery cell voltage for Cell 26";
CM_ SG_ 1835 HVBatCellVoltage_Cell025 "High voltage battery cell voltage for Cell 25";
CM_ SG_ 1835 HVBatCellVoltage_Cell024 "High voltage battery cell voltage for Cell 24";
CM_ SG_ 1835 HVBatCellVoltage_Cell023 "High voltage battery cell voltage for Cell 23";
CM_ SG_ 1835 HVBatCellVoltage_Cell022 "High voltage battery cell voltage for Cell 22";
CM_ SG_ 1835 HVBatCellVoltage_Cell021 "High voltage battery cell voltage for Cell 21";
CM_ SG_ 1835 HVBatCellVoltage_Cell020 "High voltage battery cell voltage for Cell 20";
CM_ SG_ 1835 HVBatCellVoltage_Cell019 "High voltage battery cell voltage for Cell 19";
CM_ SG_ 1835 HVBatCellVoltage_Cell018 "High voltage battery cell voltage for Cell 18";
CM_ SG_ 1835 HVBatCellVoltage_Cell017 "High voltage battery cell voltage for Cell 17";
CM_ SG_ 1835 HVBatCellVoltage_Cell016 "High voltage battery cell voltage for Cell 16";
CM_ SG_ 1835 HVBatCellVoltage_Cell015 "High voltage battery cell voltage for Cell 15";
CM_ SG_ 1835 HVBatCellVoltage_Cell014 "High voltage battery cell voltage for Cell 14";
CM_ SG_ 1835 HVBatCellVoltage_Cell013 "High voltage battery cell voltage for Cell 13";
CM_ SG_ 1835 HVBatCellVoltage_Cell012 "High voltage battery cell voltage for Cell 12";
CM_ SG_ 1835 HVBatCellVoltage_Cell011 "High voltage battery cell voltage for Cell 11";
CM_ SG_ 1835 HVBatCellVoltage_Cell010 "High voltage battery cell voltage for Cell 10";
CM_ SG_ 1835 HVBatCellVoltage_Cell009 "High voltage battery cell voltage for Cell 09";
CM_ SG_ 1835 HVBatCellVoltage_Cell008 "High voltage battery cell voltage for Cell 08";
CM_ SG_ 1835 HVBatCellVoltage_Cell007 "High voltage battery cell voltage for Cell 07";
CM_ SG_ 1835 HVBatCellVoltage_Cell006 "High voltage battery cell voltage for Cell 06";
CM_ SG_ 1835 HVBatCellVoltage_Cell005 "High voltage battery cell voltage for Cell 05";
CM_ SG_ 1835 HVBatCellVoltage_Cell004 "High voltage battery cell voltage for Cell 04";
CM_ SG_ 1835 HVBatCellVoltage_Cell003 "High voltage battery cell voltage for Cell 03";
CM_ SG_ 1835 HVBatCellVoltage_Cell002 "High voltage battery cell voltage for Cell 02";
CM_ SG_ 1835 HVBatCellVoltage_Cell001 "High voltage battery cell voltage for Cell 01";
CM_ SG_ 1328 MessageCounter_ENGINE_HYBD_FD_4 "This signal is a counter used for safety checks strategies. This counter is incremented of 1 (one) unit at each frame transmission.";
CM_ SG_ 1328 EngTorqCapbltyRefEngSpd "Engine torque capability: reference engine speed";
CM_ SG_ 1328 EngTorqCapbltyMinTorq "Engine torque capability: minimum torque (fuel off)";
CM_ SG_ 1328 EngTorqCapbltyMinRunTorq "Engine torque capability: minimum run torque (fuel on)";
CM_ SG_ 1328 EngTorqCapbltyMaxTorq "Engine torque capability: maximum torque";
CM_ SG_ 1328 EngTorqCapbltyMaxOffTorq "Capability Max-off";
CM_ SG_ 1328 EngTorqCapbltyFrmCntr "Engine Torque Capability: Frame Counter (4 bit)";
CM_ SG_ 1328 EngTorqACCCapability "Eng Trq to be subtracted from the entire capability curve on the HCP side";
CM_ SG_ 1328 CRC_ENGINE_HYBD_FD_4 "CRC according to SAE J1850 standard at each frame transmission.";
CM_ SG_ 1328 CatTempMaint "Catalyst Temperature Maintenance Flag";
CM_ SG_ 1328 CatHtgStateActive "Catalysator Heating Status Request, 0- no request, 1 - request";
CM_ SG_ 1035 ServiceHybSys "Service Hybrid system; True = [1]";
CM_ SG_ 1035 PECP_PumpFlowReq "Power Electronics Coolant pump flowrate request from ECM";
CM_ SG_ 1035 MinEngSpdCap "Minimum Engine Speed Capacity";
CM_ SG_ 1035 MessageCounter_ENGINE_HYBD_FD_3 "This signal is a counter used for safety checks strategies. This counter is incremented of 1 (one) unit at each frame transmission.";
CM_ SG_ 1035 MaxEngSpdCap "Maximum Engine Speed Capacity";
CM_ SG_ 1035 EngSpdStat "Engine speed status";
CM_ SG_ 1035 EngSpd "Engine speed";
CM_ SG_ 1035 EngOutofFuel "Engine System Failed (limp home = 1)";
CM_ SG_ 1035 EngCltTmpV "Engine Coolant Temperature Validity";
CM_ SG_ 1035 EngCltTmp "Engine Coolant Temp";
CM_ SG_ 1035 ECM_AirflowRequest "ECM Air Flow Request to the hybrid controller combining AGS and Fan requests";
CM_ SG_ 1035 CRC_ENGINE_HYBD_FD_3 "CRC according to SAE J1850 standard at each frame transmission.";
CM_ SG_ 1036 EngineOilTemperature "Engine Oil Temperature";
CM_ SG_ 750 Battery_Volt_1 "Battery Volt 1 signal";
CM_ SG_ 2654486640 SourceNodeIdentifier "Source Node Identifier";
CM_ SG_ 2654486640 CBV_bit6_PartialNtwInfBit "Partial Network Information Bit (PNI)";
CM_ SG_ 2654486640 CBV_bit4_ActiveWakeupBit "Active Wakeup Bit";
CM_ SG_ 2654486640 CBV_bit3_NMCoordinatorBit "NM Coordinator Sleep Bit";
CM_ SG_ 2654486640 CBV_bit0_RepeatMessageRequestBit "Repeat Message Request Bit";
CM_ SG_ 2654486529 SourceNodeIdentifier "Source Node Identifier";
CM_ SG_ 2654486529 CBV_bit6_PartialNtwInfBit "Partial Network Information Bit (PNI)";
CM_ SG_ 2654486529 CBV_bit4_ActiveWakeupBit "Active Wakeup Bit";
CM_ SG_ 2654486529 CBV_bit3_NMCoordinatorBit "NM Coordinator Sleep Bit";
CM_ SG_ 2654486529 CBV_bit0_RepeatMessageRequestBit "Repeat Message Request Bit";
CM_ SG_ 269 REPRGD_PFC_CLR_HCP "Set readiness to \"incomplete\"";
CM_ SG_ 269 PropulsionMode "Propulsion mode of the vehicle";
CM_ SG_ 269 MessageCounter_HYBRID_POWERTRAI "This signal is a counter used for safety checks strategies. This counter is incremented of 1 (one) unit at each frame transmission.";
CM_ SG_ 269 IdleSpeedActiveSts "Flag to indicate idle speed target [1] = TRUE";
CM_ SG_ 269 HybridEngineMaxTorqAllowed "HCP maximum torque limit";
CM_ SG_ 269 CRC_HYBRID_POWERTRAIN2 "CRC according to SAE J1850 standard at each frame transmission.";
CM_ SG_ 269 CODE_CLR_HCP "Clear emission related faults";
BA_DEF_ BU_ "NwmNodeType" ENUM "+15_NotWakeable","+30_Wakeable","+30_NotWakeable","kMaster","kSlave15","kSlave30","none";
BA_DEF_ BU_ "NmNodeType" ENUM "+15_NotWakeable","+30_Wakeable","+30_NotWakeable","kMaster","kSlave15","kSlave30","none";
BA_DEF_ BU_ "NmAsrCanMsgReducedTime" INT 1 65535;
BA_DEF_ BU_ "NmAsrNodeIdentifier" HEX 0 255;
BA_DEF_ BU_ "NmAsrNode" ENUM "No","Yes";
BA_DEF_ BU_ "NmNode" ENUM "No","Yes";
BA_DEF_ BU_ "NmStationAddress" HEX 0 255;
BA_DEF_ BU_ "Description" STRING ;
BA_DEF_ "VersionYear" INT 0 99;
BA_DEF_ "VersionWeek" INT 0 53;
BA_DEF_ "Version" HEX 0 255;
BA_DEF_ "NmAsrCanMsgCycleTime" INT 1 65535;
BA_DEF_ "NmAsrBaseAddress" HEX 235487232 2147483647;
BA_DEF_ "NmAsrMessageCount" INT 1 256;
BA_DEF_ "NmAsrRepeatMessageTime" INT 1 65535;
BA_DEF_ "NmAsrWaitBusSleepTime" INT 1 65535;
BA_DEF_ "NmAsrTimeoutTime" INT 1 65535;
BA_DEF_ "DBName" STRING ;
BA_DEF_ "Baudrate" INT 0 1000000;
BA_DEF_ "BusType" STRING ;
BA_DEF_ "NmType" STRING ;
BA_DEF_ "Manufacturer" STRING ;
BA_DEF_ BO_ "CANFD_BRS" ENUM "0","1";
BA_DEF_ BO_ "VFrameFormat" ENUM "StandardCAN","ExtendedCAN","reserved","reserved","reserved","reserved","reserved","reserved","reserved","reserved","reserved","reserved","reserved","reserved","StandardCAN_FD","ExtendedCAN_FD";
BA_DEF_ BO_ "CanTpFcFrameId" HEX 0 2147483647;
BA_DEF_ BO_ "DiagConnection" HEX 0 65535;
BA_DEF_ BO_ "DiagState" ENUM "No","Yes";
BA_DEF_ BO_ "NmAsrMessage" ENUM "No","Yes";
BA_DEF_ BO_ "GenMsgDelayTime" INT 0 65535;
BA_DEF_ BO_ "GenMsgCycleTime" INT 0 65535;
BA_DEF_ BO_ "GenMsgCycleTimeFast" INT 0 65535;
BA_DEF_ BO_ "GenMsgStartDelayTime" INT 0 65535;
BA_DEF_ BO_ "GenMsgILSupport" ENUM "No","Yes";
BA_DEF_ BO_ "GenMsgNrOfRepetition" INT 0 255;
BA_DEF_ BO_ "GenMsgSendType" ENUM "Cyclic","NotUsed","NotUsed","NotUsed","NotUsed","NotUsed","NotUsed","NotUsed","NoMsgSendType";
BA_DEF_ BO_ "NmMessage" ENUM "No","Yes";
BA_DEF_ BO_ "DiagResponse" ENUM "No","Yes";
BA_DEF_ BO_ "Type" ENUM "P","C","PE","COC","PE_Cntrl","E","E_Cntrl","OC","S","BAF","DC","EM","MM","ISO-TP","-";
BA_DEF_ BO_ "DiagRequest" ENUM "No","Yes";
BA_DEF_ SG_ "GenSigTimeoutTime_SGW" INT 0 65535;
BA_DEF_ SG_ "GenSigTimeoutTime_PBWM" INT 0 65535;
BA_DEF_ SG_ "GenSigTimeoutTime_IDCM" INT 0 65535;
BA_DEF_ SG_ "GenSigTimeoutTime_EVCU2" INT 0 65535;
BA_DEF_ SG_ "GenSigTimeoutTime_ECM" INT 0 65535;
BA_DEF_ SG_ "GenSigTimeoutTime_DMPI" INT 0 65535;
BA_DEF_ SG_ "GenSigTimeoutTime_BPCM" INT 0 65535;
BA_DEF_ SG_ "GenSigTimeoutTime_AGSM" INT 0 65535;
BA_DEF_ SG_ "SystemSignalLongSymbol" STRING ;
BA_DEF_ SG_ "GenSigSendType" ENUM "NotUsed","OnWrite","OnWriteWithRepetition","OnChange","OnChangeWithRepetition","IfActive","IfActiveWithRepetition","NoSigSendType";
BA_DEF_ SG_ "GenSigInactiveValue" INT 0 2147483647;
BA_DEF_ SG_ "GenSigStartValue" INT 0 2147483647;
BA_DEF_DEF_ "NwmNodeType" "none";
BA_DEF_DEF_ "NmNodeType" "none";
BA_DEF_DEF_ "NmAsrCanMsgReducedTime" 100;
BA_DEF_DEF_ "NmAsrNodeIdentifier" 0;
BA_DEF_DEF_ "NmAsrNode" "Yes";
BA_DEF_DEF_ "NmNode" "Yes";
BA_DEF_DEF_ "NmStationAddress" 0;
BA_DEF_DEF_ "Description" "";
BA_DEF_DEF_ "VersionYear" 23;
BA_DEF_DEF_ "VersionWeek" 46;
BA_DEF_DEF_ "Version" 160;
BA_DEF_DEF_ "NmAsrCanMsgCycleTime" 200;
BA_DEF_DEF_ "NmAsrBaseAddress" 506724352;
BA_DEF_DEF_ "NmAsrMessageCount" 256;
BA_DEF_DEF_ "NmAsrRepeatMessageTime" 800;
BA_DEF_DEF_ "NmAsrWaitBusSleepTime" 750;
BA_DEF_DEF_ "NmAsrTimeoutTime" 1000;
BA_DEF_DEF_ "DBName" "CAN";
BA_DEF_DEF_ "Baudrate" 500000;
BA_DEF_DEF_ "BusType" "CAN";
BA_DEF_DEF_ "NmType" "";
BA_DEF_DEF_ "Manufacturer" "Fiat";
BA_DEF_DEF_ "CANFD_BRS" "0";
BA_DEF_DEF_ "VFrameFormat" "StandardCAN_FD";
BA_DEF_DEF_ "CanTpFcFrameId" 2147483647;
BA_DEF_DEF_ "DiagConnection" 0;
BA_DEF_DEF_ "DiagState" "No";
BA_DEF_DEF_ "NmAsrMessage" "No";
BA_DEF_DEF_ "GenMsgDelayTime" 0;
BA_DEF_DEF_ "GenMsgCycleTime" 0;
BA_DEF_DEF_ "GenMsgCycleTimeFast" 0;
BA_DEF_DEF_ "GenMsgStartDelayTime" 0;
BA_DEF_DEF_ "GenMsgILSupport" "No";
BA_DEF_DEF_ "GenMsgNrOfRepetition" 0;
BA_DEF_DEF_ "GenMsgSendType" "NoMsgSendType";
BA_DEF_DEF_ "NmMessage" "No";
BA_DEF_DEF_ "DiagResponse" "No";
BA_DEF_DEF_ "Type" "-";
BA_DEF_DEF_ "DiagRequest" "No";
BA_DEF_DEF_ "GenSigTimeoutTime_SGW" 2500;
BA_DEF_DEF_ "GenSigTimeoutTime_PBWM" 2500;
BA_DEF_DEF_ "GenSigTimeoutTime_IDCM" 2500;
BA_DEF_DEF_ "GenSigTimeoutTime_EVCU2" 2500;
BA_DEF_DEF_ "GenSigTimeoutTime_ECM" 2500;
BA_DEF_DEF_ "GenSigTimeoutTime_DMPI" 2500;
BA_DEF_DEF_ "GenSigTimeoutTime_BPCM" 2500;
BA_DEF_DEF_ "GenSigTimeoutTime_AGSM" 2500;
BA_DEF_DEF_ "SystemSignalLongSymbol" "";
BA_DEF_DEF_ "GenSigSendType" "NoSigSendType";
BA_DEF_DEF_ "GenSigInactiveValue" 0;
BA_DEF_DEF_ "GenSigStartValue" 0;
BA_ "NmAsrCanMsgCycleTime" 1000;
BA_ "NmAsrBaseAddress" 507002880;
BA_ "NmAsrRepeatMessageTime" 5000;
BA_ "NmAsrWaitBusSleepTime" 1000;
BA_ "NmAsrTimeoutTime" 8000;
BA_ "DBName" "FDCAN11";
BA_ "BusType" "CAN FD";
BA_ "NmType" "NmAsr";
BA_ "NwmNodeType" BU_ SGW 1;
BA_ "NmNodeType" BU_ SGW 1;
BA_ "NmAsrCanMsgReducedTime" BU_ SGW 800;
BA_ "NmAsrNodeIdentifier" BU_ SGW 112;
BA_ "NmStationAddress" BU_ SGW 112;
BA_ "Description" BU_ SGW "Security Gateway Module";
BA_ "NwmNodeType" BU_ PBWM 1;
BA_ "NmNodeType" BU_ PBWM 1;
BA_ "NmAsrCanMsgReducedTime" BU_ PBWM 775;
BA_ "NmAsrNodeIdentifier" BU_ PBWM 60;
BA_ "NmStationAddress" BU_ PBWM 60;
BA_ "Description" BU_ PBWM "Park By Wire Module";
BA_ "NwmNodeType" BU_ IDCM 1;
BA_ "NmNodeType" BU_ IDCM 1;
BA_ "NmAsrCanMsgReducedTime" BU_ IDCM 600;
BA_ "NmAsrNodeIdentifier" BU_ IDCM 125;
BA_ "NmStationAddress" BU_ IDCM 125;
BA_ "Description" BU_ IDCM "Integrated Dual Charge Module";
BA_ "NwmNodeType" BU_ EVCU2 1;
BA_ "NmNodeType" BU_ EVCU2 1;
BA_ "NmAsrCanMsgReducedTime" BU_ EVCU2 950;
BA_ "NmAsrNodeIdentifier" BU_ EVCU2 64;
BA_ "NmStationAddress" BU_ EVCU2 64;
BA_ "Description" BU_ EVCU2 "Electric Vehicle Control Unit 2";
BA_ "NwmNodeType" BU_ ECM 1;
BA_ "NmNodeType" BU_ ECM 1;
BA_ "NmAsrCanMsgReducedTime" BU_ ECM 825;
BA_ "NmAsrNodeIdentifier" BU_ ECM 1;
BA_ "NmStationAddress" BU_ ECM 1;
BA_ "Description" BU_ ECM "Engine Control Module";
BA_ "NwmNodeType" BU_ DMPI 1;
BA_ "NmNodeType" BU_ DMPI 1;
BA_ "NmAsrCanMsgReducedTime" BU_ DMPI 650;
BA_ "NmAsrNodeIdentifier" BU_ DMPI 66;
BA_ "NmStationAddress" BU_ DMPI 66;
BA_ "Description" BU_ DMPI "Drive Motor Power Inverter";
BA_ "NwmNodeType" BU_ BPCM 1;
BA_ "NmNodeType" BU_ BPCM 1;
BA_ "NmAsrCanMsgReducedTime" BU_ BPCM 525;
BA_ "NmAsrNodeIdentifier" BU_ BPCM 70;
BA_ "NmStationAddress" BU_ BPCM 70;
BA_ "Description" BU_ BPCM "Battery Pack Control Module";
BA_ "NwmNodeType" BU_ AGSM 0;
BA_ "NmNodeType" BU_ AGSM 0;
BA_ "NmAsrNodeIdentifier" BU_ AGSM 22;
BA_ "NmAsrNode" BU_ AGSM 0;
BA_ "NmNode" BU_ AGSM 0;
BA_ "NmStationAddress" BU_ AGSM 22;
BA_ "Description" BU_ AGSM "Automatic Gearbox Shifter Module";
BA_ "VFrameFormat" BO_ 2651930624 15;
BA_ "GenMsgDelayTime" BO_ 2651930624 10;
BA_ "GenMsgILSupport" BO_ 2651930624 1;
BA_ "Type" BO_ 2651930624 8;
BA_ "CANFD_BRS" BO_ 2651930624 1;
BA_ "VFrameFormat" BO_ 2564554481 1;
BA_ "DiagConnection" BO_ 2564554481 61950;
BA_ "DiagState" BO_ 2564554481 1;
BA_ "Type" BO_ 2564554481 8;
BA_ "VFrameFormat" BO_ 2564502513 1;
BA_ "DiagConnection" BO_ 2564502513 61747;
BA_ "DiagState" BO_ 2564502513 1;
BA_ "Type" BO_ 2564502513 8;
BA_ "VFrameFormat" BO_ 2564485444 1;
BA_ "DiagConnection" BO_ 2564485444 61764;
BA_ "DiagResponse" BO_ 2564485444 1;
BA_ "Type" BO_ 2564485444 8;
BA_ "VFrameFormat" BO_ 2564441329 1;
BA_ "DiagConnection" BO_ 2564441329 61764;
BA_ "Type" BO_ 2564441329 8;
BA_ "DiagRequest" BO_ 2564441329 1;
BA_ "VFrameFormat" BO_ 2564485456 1;
BA_ "DiagConnection" BO_ 2564485456 61776;
BA_ "DiagResponse" BO_ 2564485456 1;
BA_ "Type" BO_ 2564485456 8;
BA_ "VFrameFormat" BO_ 2564444401 1;
BA_ "DiagConnection" BO_ 2564444401 61776;
BA_ "Type" BO_ 2564444401 8;
BA_ "DiagRequest" BO_ 2564444401 1;
BA_ "CANFD_BRS" BO_ 1053 1;
BA_ "GenMsgCycleTime" BO_ 1053 100;
BA_ "GenMsgILSupport" BO_ 1053 1;
BA_ "GenMsgSendType" BO_ 1053 0;
BA_ "Type" BO_ 1053 1;
BA_ "CANFD_BRS" BO_ 156 1;
BA_ "GenMsgILSupport" BO_ 156 1;
BA_ "Type" BO_ 156 8;
BA_ "CANFD_BRS" BO_ 1058 1;
BA_ "GenMsgCycleTime" BO_ 1058 100;
BA_ "GenMsgILSupport" BO_ 1058 1;
BA_ "GenMsgSendType" BO_ 1058 0;
BA_ "Type" BO_ 1058 1;
BA_ "CANFD_BRS" BO_ 1829 1;
BA_ "GenMsgCycleTime" BO_ 1829 1000;
BA_ "GenMsgILSupport" BO_ 1829 1;
BA_ "GenMsgSendType" BO_ 1829 0;
BA_ "Type" BO_ 1829 1;
BA_ "GenMsgSendType" BO_ 1626 0;
BA_ "Type" BO_ 1626 10;
BA_ "CANFD_BRS" BO_ 1626 1;
BA_ "GenMsgCycleTime" BO_ 1626 500;
BA_ "GenMsgCycleTimeFast" BO_ 1626 10;
BA_ "GenMsgILSupport" BO_ 1626 1;
BA_ "CANFD_BRS" BO_ 751 1;
BA_ "GenMsgCycleTime" BO_ 751 50;
BA_ "GenMsgILSupport" BO_ 751 1;
BA_ "GenMsgSendType" BO_ 751 0;
BA_ "Type" BO_ 751 1;
BA_ "CANFD_BRS" BO_ 518 1;
BA_ "GenMsgCycleTime" BO_ 518 20;
BA_ "GenMsgILSupport" BO_ 518 1;
BA_ "GenMsgSendType" BO_ 518 0;
BA_ "Type" BO_ 518 1;
BA_ "CANFD_BRS" BO_ 2564485648 1;
BA_ "VFrameFormat" BO_ 2564485648 15;
BA_ "DiagConnection" BO_ 2564485648 61968;
BA_ "DiagResponse" BO_ 2564485648 1;
BA_ "Type" BO_ 2564485648 8;
BA_ "CANFD_BRS" BO_ 2564554482 1;
BA_ "VFrameFormat" BO_ 2564554482 15;
BA_ "DiagConnection" BO_ 2564554482 62206;
BA_ "DiagState" BO_ 2564554482 1;
BA_ "Type" BO_ 2564554482 8;
BA_ "CANFD_BRS" BO_ 2564428018 1;
BA_ "VFrameFormat" BO_ 2564428018 15;
BA_ "DiagConnection" BO_ 2564428018 61968;
BA_ "Type" BO_ 2564428018 8;
BA_ "DiagRequest" BO_ 2564428018 1;
BA_ "GenMsgNrOfRepetition" BO_ 1066 2;
BA_ "GenMsgSendType" BO_ 1066 0;
BA_ "Type" BO_ 1066 3;
BA_ "GenMsgILSupport" BO_ 1066 1;
BA_ "CANFD_BRS" BO_ 1066 1;
BA_ "GenMsgDelayTime" BO_ 1066 20;
BA_ "GenMsgCycleTime" BO_ 1066 250;
BA_ "GenMsgCycleTimeFast" BO_ 1066 20;
BA_ "CANFD_BRS" BO_ 1827 1;
BA_ "GenMsgCycleTime" BO_ 1827 1000;
BA_ "GenMsgILSupport" BO_ 1827 1;
BA_ "GenMsgSendType" BO_ 1827 0;
BA_ "Type" BO_ 1827 1;
BA_ "CANFD_BRS" BO_ 1153 1;
BA_ "GenMsgDelayTime" BO_ 1153 20;
BA_ "GenMsgCycleTime" BO_ 1153 500;
BA_ "GenMsgCycleTimeFast" BO_ 1153 20;
BA_ "GenMsgILSupport" BO_ 1153 1;
BA_ "GenMsgNrOfRepetition" BO_ 1153 2;
BA_ "GenMsgSendType" BO_ 1153 0;
BA_ "Type" BO_ 1153 3;
BA_ "CANFD_BRS" BO_ 753 1;
BA_ "GenMsgCycleTime" BO_ 753 50;
BA_ "GenMsgILSupport" BO_ 753 1;
BA_ "GenMsgSendType" BO_ 753 0;
BA_ "Type" BO_ 753 1;
BA_ "CANFD_BRS" BO_ 1032 1;
BA_ "GenMsgCycleTime" BO_ 1032 100;
BA_ "GenMsgILSupport" BO_ 1032 1;
BA_ "GenMsgSendType" BO_ 1032 0;
BA_ "Type" BO_ 1032 1;
BA_ "CANFD_BRS" BO_ 267 1;
BA_ "GenMsgCycleTime" BO_ 267 10;
BA_ "GenMsgILSupport" BO_ 267 1;
BA_ "GenMsgSendType" BO_ 267 0;
BA_ "Type" BO_ 267 1;
BA_ "CANFD_BRS" BO_ 1033 1;
BA_ "GenMsgCycleTime" BO_ 1033 100;
BA_ "GenMsgILSupport" BO_ 1033 1;
BA_ "GenMsgSendType" BO_ 1033 0;
BA_ "Type" BO_ 1033 1;
BA_ "CANFD_BRS" BO_ 266 1;
BA_ "GenMsgCycleTime" BO_ 266 10;
BA_ "GenMsgStartDelayTime" BO_ 266 5;
BA_ "GenMsgILSupport" BO_ 266 1;
BA_ "GenMsgSendType" BO_ 266 0;
BA_ "Type" BO_ 266 1;
BA_ "CANFD_BRS" BO_ 1839 1;
BA_ "GenMsgCycleTime" BO_ 1839 1000;
BA_ "GenMsgILSupport" BO_ 1839 1;
BA_ "GenMsgSendType" BO_ 1839 0;
BA_ "Type" BO_ 1839 1;
BA_ "CANFD_BRS" BO_ 1840 1;
BA_ "GenMsgCycleTime" BO_ 1840 1000;
BA_ "GenMsgILSupport" BO_ 1840 1;
BA_ "GenMsgSendType" BO_ 1840 0;
BA_ "Type" BO_ 1840 1;
BA_ "GenMsgCycleTime" BO_ 1838 1000;
BA_ "GenMsgILSupport" BO_ 1838 1;
BA_ "GenMsgSendType" BO_ 1838 0;
BA_ "Type" BO_ 1838 1;
BA_ "CANFD_BRS" BO_ 1838 1;
BA_ "CANFD_BRS" BO_ 1837 1;
BA_ "GenMsgCycleTime" BO_ 1837 1000;
BA_ "GenMsgILSupport" BO_ 1837 1;
BA_ "GenMsgSendType" BO_ 1837 0;
BA_ "Type" BO_ 1837 1;
BA_ "Type" BO_ 1836 1;
BA_ "CANFD_BRS" BO_ 1836 1;
BA_ "GenMsgCycleTime" BO_ 1836 1000;
BA_ "GenMsgILSupport" BO_ 1836 1;
BA_ "GenMsgSendType" BO_ 1836 0;
BA_ "CANFD_BRS" BO_ 1835 1;
BA_ "GenMsgCycleTime" BO_ 1835 1000;
BA_ "GenMsgILSupport" BO_ 1835 1;
BA_ "GenMsgSendType" BO_ 1835 0;
BA_ "Type" BO_ 1835 1;
BA_ "CANFD_BRS" BO_ 1328 1;
BA_ "GenMsgCycleTime" BO_ 1328 200;
BA_ "GenMsgILSupport" BO_ 1328 1;
BA_ "GenMsgSendType" BO_ 1328 0;
BA_ "Type" BO_ 1328 1;
BA_ "CANFD_BRS" BO_ 1035 1;
BA_ "GenMsgCycleTime" BO_ 1035 100;
BA_ "GenMsgILSupport" BO_ 1035 1;
BA_ "GenMsgSendType" BO_ 1035 0;
BA_ "Type" BO_ 1035 1;
BA_ "CANFD_BRS" BO_ 1036 1;
BA_ "GenMsgDelayTime" BO_ 1036 20;
BA_ "GenMsgCycleTime" BO_ 1036 100;
BA_ "GenMsgCycleTimeFast" BO_ 1036 20;
BA_ "GenMsgILSupport" BO_ 1036 1;
BA_ "GenMsgNrOfRepetition" BO_ 1036 2;
BA_ "GenMsgSendType" BO_ 1036 0;
BA_ "Type" BO_ 1036 3;
BA_ "CANFD_BRS" BO_ 750 1;
BA_ "GenMsgCycleTime" BO_ 750 50;
BA_ "GenMsgILSupport" BO_ 750 1;
BA_ "GenMsgSendType" BO_ 750 0;
BA_ "Type" BO_ 750 1;
BA_ "CANFD_BRS" BO_ 2654486640 1;
BA_ "VFrameFormat" BO_ 2654486640 15;
BA_ "NmAsrMessage" BO_ 2654486640 1;
BA_ "NmMessage" BO_ 2654486640 1;
BA_ "Type" BO_ 2654486640 8;
BA_ "CANFD_BRS" BO_ 2654486529 1;
BA_ "VFrameFormat" BO_ 2654486529 15;
BA_ "NmAsrMessage" BO_ 2654486529 1;
BA_ "NmMessage" BO_ 2654486529 1;
BA_ "Type" BO_ 2654486529 8;
BA_ "CANFD_BRS" BO_ 269 1;
BA_ "GenMsgCycleTime" BO_ 269 10;
BA_ "GenMsgILSupport" BO_ 269 1;
BA_ "GenMsgSendType" BO_ 269 0;
BA_ "Type" BO_ 269 1;
BA_ "GenSigTimeoutTime_SGW" SG_ 1053 VIN_MSG 0;
BA_ "GenSigTimeoutTime_PBWM" SG_ 1053 VIN_MSG 0;
BA_ "GenSigTimeoutTime_EVCU2" SG_ 1053 VIN_MSG 0;
BA_ "GenSigTimeoutTime_ECM" SG_ 1053 VIN_MSG 0;
BA_ "GenSigTimeoutTime_DMPI" SG_ 1053 VIN_MSG 0;
BA_ "GenSigTimeoutTime_BPCM" SG_ 1053 VIN_MSG 0;
BA_ "GenSigTimeoutTime_AGSM" SG_ 1053 VIN_MSG 0;
BA_ "GenSigStartValue" SG_ 1053 VIN_MSG 3;
BA_ "GenSigTimeoutTime_SGW" SG_ 1053 VIN_DATA 0;
BA_ "GenSigTimeoutTime_PBWM" SG_ 1053 VIN_DATA 0;
BA_ "GenSigTimeoutTime_EVCU2" SG_ 1053 VIN_DATA 0;
BA_ "GenSigTimeoutTime_ECM" SG_ 1053 VIN_DATA 0;
BA_ "GenSigTimeoutTime_DMPI" SG_ 1053 VIN_DATA 0;
BA_ "GenSigTimeoutTime_BPCM" SG_ 1053 VIN_DATA 0;
BA_ "GenSigTimeoutTime_AGSM" SG_ 1053 VIN_DATA 0;
BA_ "GenSigTimeoutTime_EVCU2" SG_ 1626 IMPACTConfirm 0;
BA_ "GenSigTimeoutTime_AGSM" SG_ 1626 IMPACTConfirm 0;
BA_ "GenSigSendType" SG_ 1626 IMPACTConfirm 5;
BA_ "GenSigInactiveValue" SG_ 1626 IMPACTConfirm 1;
BA_ "GenSigStartValue" SG_ 1626 IMPACTConfirm 1;
BA_ "GenSigTimeoutTime_EVCU2" SG_ 1626 IMPACTCommand 0;
BA_ "GenSigTimeoutTime_AGSM" SG_ 1626 IMPACTCommand 0;
BA_ "GenSigSendType" SG_ 1626 IMPACTCommand 5;
BA_ "GenSigTimeoutTime_SGW" SG_ 1626 IMPACTCommand 0;
BA_ "GenSigTimeoutTime_PBWM" SG_ 1626 IMPACTCommand 0;
BA_ "GenSigTimeoutTime_EVCU2" SG_ 1626 IMPACTCommand 0;
BA_ "GenSigTimeoutTime_ECM" SG_ 1626 IMPACTCommand 0;
BA_ "GenSigTimeoutTime_AGSM" SG_ 1626 IMPACTCommand 0;
BA_ "GenSigSendType" SG_ 1626 IMPACTCommand 5;
BA_ "GenSigTimeoutTime_SGW" SG_ 1626 IMPACTConfirm 0;
BA_ "GenSigTimeoutTime_PBWM" SG_ 1626 IMPACTConfirm 0;
BA_ "GenSigTimeoutTime_EVCU2" SG_ 1626 IMPACTConfirm 0;
BA_ "GenSigTimeoutTime_ECM" SG_ 1626 IMPACTConfirm 0;
BA_ "GenSigTimeoutTime_AGSM" SG_ 1626 IMPACTConfirm 0;
BA_ "GenSigSendType" SG_ 1626 IMPACTConfirm 5;
BA_ "GenSigInactiveValue" SG_ 1626 IMPACTConfirm 1;
BA_ "GenSigStartValue" SG_ 1626 IMPACTConfirm 1;
BA_ "GenSigTimeoutTime_PBWM" SG_ 1839 HVBatModuleTemp_01 0;
BA_ "GenSigTimeoutTime_IDCM" SG_ 1839 HVBatModuleTemp_01 0;
BA_ "GenSigTimeoutTime_EVCU2" SG_ 1839 HVBatModuleTemp_01 0;
BA_ "GenSigTimeoutTime_ECM" SG_ 1839 HVBatModuleTemp_01 0;
BA_ "GenSigTimeoutTime_DMPI" SG_ 1839 HVBatModuleTemp_01 0;
BA_ "GenSigTimeoutTime_BPCM" SG_ 1839 HVBatModuleTemp_01 0;
BA_ "GenSigTimeoutTime_AGSM" SG_ 1839 HVBatModuleTemp_01 0;
BA_ "GenSigTimeoutTime_BPCM" SG_ 1839 HVBatModuleTemp_02 0;
BA_ "GenSigTimeoutTime_AGSM" SG_ 1839 HVBatModuleTemp_02 0;
BA_ "GenSigTimeoutTime_PBWM" SG_ 1839 HVBatModuleTemp_02 0;
BA_ "GenSigTimeoutTime_IDCM" SG_ 1839 HVBatModuleTemp_02 0;
BA_ "GenSigTimeoutTime_EVCU2" SG_ 1839 HVBatModuleTemp_02 0;
BA_ "GenSigTimeoutTime_ECM" SG_ 1839 HVBatModuleTemp_02 0;
BA_ "GenSigTimeoutTime_DMPI" SG_ 1839 HVBatModuleTemp_02 0;
BA_ "GenSigTimeoutTime_PBWM" SG_ 1839 HVBatModuleTemp_03 0;
BA_ "GenSigTimeoutTime_IDCM" SG_ 1839 HVBatModuleTemp_03 0;
BA_ "GenSigTimeoutTime_EVCU2" SG_ 1839 HVBatModuleTemp_03 0;
BA_ "GenSigTimeoutTime_ECM" SG_ 1839 HVBatModuleTemp_03 0;
BA_ "GenSigTimeoutTime_DMPI" SG_ 1839 HVBatModuleTemp_03 0;
BA_ "GenSigTimeoutTime_BPCM" SG_ 1839 HVBatModuleTemp_03 0;
BA_ "GenSigTimeoutTime_AGSM" SG_ 1839 HVBatModuleTemp_03 0;
BA_ "GenSigTimeoutTime_PBWM" SG_ 1839 HVBatModuleTemp_04 0;
BA_ "GenSigTimeoutTime_IDCM" SG_ 1839 HVBatModuleTemp_04 0;
BA_ "GenSigTimeoutTime_EVCU2" SG_ 1839 HVBatModuleTemp_04 0;
BA_ "GenSigTimeoutTime_ECM" SG_ 1839 HVBatModuleTemp_04 0;
BA_ "GenSigTimeoutTime_PBWM" SG_ 1840 Warning_PackTempDiff 0;
BA_ "GenSigTimeoutTime_IDCM" SG_ 1840 Warning_PackTempDiff 0;
BA_ "GenSigTimeoutTime_EVCU2" SG_ 1840 Warning_PackTempDiff 0;
BA_ "GenSigTimeoutTime_ECM" SG_ 1840 Warning_PackTempDiff 0;
BA_ "GenSigTimeoutTime_DMPI" SG_ 1840 Warning_PackTempDiff 0;
BA_ "GenSigTimeoutTime_BPCM" SG_ 1840 Warning_PackTempDiff 0;
BA_ "GenSigTimeoutTime_AGSM" SG_ 1840 Warning_PackTempDiff 0;
BA_ "GenSigTimeoutTime_PBWM" SG_ 1840 Warning_PackTempHigh 0;
BA_ "GenSigTimeoutTime_IDCM" SG_ 1840 Warning_PackTempHigh 0;
BA_ "GenSigTimeoutTime_ECM" SG_ 1840 Warning_PackTempHigh 0;
BA_ "GenSigTimeoutTime_DMPI" SG_ 1840 Warning_PackTempHigh 0;
BA_ "GenSigTimeoutTime_BPCM" SG_ 1840 Warning_PackTempHigh 0;
BA_ "GenSigTimeoutTime_AGSM" SG_ 1840 Warning_PackTempHigh 0;
BA_ "GenSigTimeoutTime_PBWM" SG_ 1840 Warning_CellOvervoltage 0;
BA_ "GenSigTimeoutTime_IDCM" SG_ 1840 Warning_CellOvervoltage 0;
BA_ "GenSigTimeoutTime_EVCU2" SG_ 1840 Warning_CellOvervoltage 0;
BA_ "GenSigTimeoutTime_ECM" SG_ 1840 Warning_CellOvervoltage 0;
BA_ "GenSigTimeoutTime_DMPI" SG_ 1840 Warning_CellOvervoltage 0;
BA_ "GenSigTimeoutTime_BPCM" SG_ 1840 Warning_CellOvervoltage 0;
BA_ "GenSigTimeoutTime_AGSM" SG_ 1840 Warning_CellOvervoltage 0;
BA_ "GenSigTimeoutTime_PBWM" SG_ 1840 Warning_CellUndervoltage 0;
BA_ "GenSigTimeoutTime_IDCM" SG_ 1840 Warning_CellUndervoltage 0;
BA_ "GenSigTimeoutTime_EVCU2" SG_ 1840 Warning_CellUndervoltage 0;
BA_ "GenSigTimeoutTime_ECM" SG_ 1840 Warning_CellUndervoltage 0;
BA_ "GenSigTimeoutTime_DMPI" SG_ 1840 Warning_CellUndervoltage 0;
BA_ "GenSigTimeoutTime_BPCM" SG_ 1840 Warning_CellUndervoltage 0;
BA_ "GenSigTimeoutTime_AGSM" SG_ 1840 Warning_CellUndervoltage 0;
BA_ "GenSigTimeoutTime_PBWM" SG_ 1840 Warning_HighSOC 0;
BA_ "GenSigTimeoutTime_IDCM" SG_ 1840 Warning_HighSOC 0;
BA_ "GenSigTimeoutTime_EVCU2" SG_ 1840 Warning_HighSOC 0;
BA_ "GenSigTimeoutTime_ECM" SG_ 1840 Warning_HighSOC 0;
BA_ "GenSigTimeoutTime_DMPI" SG_ 1840 Warning_HighSOC 0;
BA_ "GenSigTimeoutTime_BPCM" SG_ 1840 Warning_HighSOC 0;
BA_ "GenSigTimeoutTime_AGSM" SG_ 1840 Warning_HighSOC 0;
BA_ "GenSigTimeoutTime_PBWM" SG_ 1840 Warning_HVIL 0;
BA_ "GenSigTimeoutTime_IDCM" SG_ 1840 Warning_HVIL 0;
BA_ "GenSigTimeoutTime_EVCU2" SG_ 1840 Warning_HVIL 0;
BA_ "GenSigTimeoutTime_ECM" SG_ 1840 Warning_HVIL 0;
BA_ "GenSigTimeoutTime_DMPI" SG_ 1840 Warning_HVIL 0;
BA_ "GenSigTimeoutTime_BPCM" SG_ 1840 Warning_HVIL 0;
BA_ "GenSigTimeoutTime_AGSM" SG_ 1840 Warning_HVIL 0;
BA_ "GenSigTimeoutTime_PBWM" SG_ 1840 Warning_Insulation 0;
BA_ "GenSigTimeoutTime_IDCM" SG_ 1840 Warning_Insulation 0;
BA_ "GenSigTimeoutTime_EVCU2" SG_ 1840 Warning_Insulation 0;
BA_ "GenSigTimeoutTime_ECM" SG_ 1840 Warning_Insulation 0;
BA_ "GenSigTimeoutTime_DMPI" SG_ 1840 Warning_Insulation 0;
BA_ "GenSigTimeoutTime_BPCM" SG_ 1840 Warning_Insulation 0;
BA_ "GenSigTimeoutTime_AGSM" SG_ 1840 Warning_Insulation 0;
BA_ "GenSigTimeoutTime_PBWM" SG_ 1840 Warning_LowSOC 0;
BA_ "GenSigTimeoutTime_IDCM" SG_ 1840 Warning_LowSOC 0;
BA_ "GenSigTimeoutTime_EVCU2" SG_ 1840 Warning_LowSOC 0;
BA_ "GenSigTimeoutTime_ECM" SG_ 1840 Warning_LowSOC 0;
BA_ "GenSigTimeoutTime_DMPI" SG_ 1840 Warning_LowSOC 0;
BA_ "GenSigTimeoutTime_BPCM" SG_ 1840 Warning_LowSOC 0;
BA_ "GenSigTimeoutTime_AGSM" SG_ 1840 Warning_LowSOC 0;
BA_ "GenSigTimeoutTime_PBWM" SG_ 1840 Warning_Overcharging 0;
BA_ "GenSigTimeoutTime_IDCM" SG_ 1840 Warning_Overcharging 0;
BA_ "GenSigTimeoutTime_EVCU2" SG_ 1840 Warning_Overcharging 0;
BA_ "GenSigTimeoutTime_ECM" SG_ 1840 Warning_Overcharging 0;
BA_ "GenSigTimeoutTime_DMPI" SG_ 1840 Warning_Overcharging 0;
BA_ "GenSigTimeoutTime_BPCM" SG_ 1840 Warning_Overcharging 0;
BA_ "GenSigTimeoutTime_AGSM" SG_ 1840 Warning_Overcharging 0;
BA_ "GenSigTimeoutTime_PBWM" SG_ 1840 Warning_PackOvervoltage 0;
BA_ "GenSigTimeoutTime_IDCM" SG_ 1840 Warning_PackOvervoltage 0;
BA_ "GenSigTimeoutTime_EVCU2" SG_ 1840 Warning_PackOvervoltage 0;
BA_ "GenSigTimeoutTime_ECM" SG_ 1840 Warning_PackOvervoltage 0;
BA_ "GenSigTimeoutTime_DMPI" SG_ 1840 Warning_PackOvervoltage 0;
BA_ "GenSigTimeoutTime_BPCM" SG_ 1840 Warning_PackOvervoltage 0;
BA_ "GenSigTimeoutTime_AGSM" SG_ 1840 Warning_PackOvervoltage 0;
BA_ "GenSigTimeoutTime_PBWM" SG_ 1840 HighestWarningLevel 0;
BA_ "GenSigTimeoutTime_IDCM" SG_ 1840 HighestWarningLevel 0;
BA_ "GenSigTimeoutTime_EVCU2" SG_ 1840 HighestWarningLevel 0;
BA_ "GenSigTimeoutTime_ECM" SG_ 1840 HighestWarningLevel 0;
BA_ "GenSigTimeoutTime_DMPI" SG_ 1840 HighestWarningLevel 0;
BA_ "GenSigTimeoutTime_BPCM" SG_ 1840 HighestWarningLevel 0;
BA_ "GenSigTimeoutTime_AGSM" SG_ 1840 HighestWarningLevel 0;
BA_ "GenSigTimeoutTime_PBWM" SG_ 1840 Warning_CellBalance 0;
BA_ "GenSigTimeoutTime_IDCM" SG_ 1840 Warning_CellBalance 0;
BA_ "GenSigTimeoutTime_EVCU2" SG_ 1840 Warning_CellBalance 0;
BA_ "GenSigTimeoutTime_ECM" SG_ 1840 Warning_CellBalance 0;
BA_ "GenSigTimeoutTime_DMPI" SG_ 1840 Warning_CellBalance 0;
BA_ "GenSigTimeoutTime_BPCM" SG_ 1840 Warning_CellBalance 0;
BA_ "GenSigTimeoutTime_AGSM" SG_ 1840 Warning_CellBalance 0;
BA_ "GenSigTimeoutTime_PBWM" SG_ 1840 IsolationResistance 0;
BA_ "GenSigTimeoutTime_IDCM" SG_ 1840 IsolationResistance 0;
BA_ "GenSigTimeoutTime_EVCU2" SG_ 1840 IsolationResistance 0;
BA_ "GenSigTimeoutTime_ECM" SG_ 1840 IsolationResistance 0;
BA_ "GenSigTimeoutTime_DMPI" SG_ 1840 IsolationResistance 0;
BA_ "GenSigTimeoutTime_BPCM" SG_ 1840 IsolationResistance 0;
BA_ "GenSigTimeoutTime_AGSM" SG_ 1840 IsolationResistance 0;
BA_ "GenSigTimeoutTime_SGW" SG_ 156 GPS_Date_Day 0;
BA_ "GenSigTimeoutTime_PBWM" SG_ 156 GPS_Date_Day 0;
BA_ "GenSigTimeoutTime_EVCU2" SG_ 156 GPS_Date_Day 0;
BA_ "GenSigTimeoutTime_ECM" SG_ 156 GPS_Date_Day 0;
BA_ "GenSigTimeoutTime_AGSM" SG_ 156 GPS_Date_Day 0;
BA_ "GenSigStartValue" SG_ 156 GPS_Date_Day 255;
BA_ "GenSigTimeoutTime_SGW" SG_ 156 GPS_Date_Month 0;
BA_ "GenSigTimeoutTime_PBWM" SG_ 156 GPS_Date_Month 0;
BA_ "GenSigTimeoutTime_EVCU2" SG_ 156 GPS_Date_Month 0;
BA_ "GenSigTimeoutTime_ECM" SG_ 156 GPS_Date_Month 0;
BA_ "GenSigTimeoutTime_AGSM" SG_ 156 GPS_Date_Month 0;
BA_ "GenSigStartValue" SG_ 156 GPS_Date_Month 255;
BA_ "GenSigTimeoutTime_SGW" SG_ 156 GPS_Date_Year 0;
BA_ "GenSigTimeoutTime_PBWM" SG_ 156 GPS_Date_Year 0;
BA_ "GenSigTimeoutTime_EVCU2" SG_ 156 GPS_Date_Year 0;
BA_ "GenSigTimeoutTime_ECM" SG_ 156 GPS_Date_Year 0;
BA_ "GenSigTimeoutTime_AGSM" SG_ 156 GPS_Date_Year 0;
BA_ "GenSigStartValue" SG_ 156 GPS_Date_Year 65535;
BA_ "GenSigTimeoutTime_SGW" SG_ 156 GPS_UTC_Hour 0;
BA_ "GenSigTimeoutTime_PBWM" SG_ 156 GPS_UTC_Hour 0;
BA_ "GenSigTimeoutTime_EVCU2" SG_ 156 GPS_UTC_Hour 0;
BA_ "GenSigTimeoutTime_ECM" SG_ 156 GPS_UTC_Hour 0;
BA_ "GenSigTimeoutTime_AGSM" SG_ 156 GPS_UTC_Hour 0;
BA_ "GenSigStartValue" SG_ 156 GPS_UTC_Hour 255;
BA_ "GenSigTimeoutTime_SGW" SG_ 156 GPS_UTC_Minute 0;
BA_ "GenSigTimeoutTime_PBWM" SG_ 156 GPS_UTC_Minute 0;
BA_ "GenSigTimeoutTime_EVCU2" SG_ 156 GPS_UTC_Minute 0;
BA_ "GenSigTimeoutTime_ECM" SG_ 156 GPS_UTC_Minute 0;
BA_ "GenSigTimeoutTime_AGSM" SG_ 156 GPS_UTC_Minute 0;
BA_ "GenSigStartValue" SG_ 156 GPS_UTC_Minute 255;
BA_ "GenSigTimeoutTime_SGW" SG_ 156 GPS_UTC_Second 0;
BA_ "GenSigTimeoutTime_PBWM" SG_ 156 GPS_UTC_Second 0;
BA_ "GenSigTimeoutTime_EVCU2" SG_ 156 GPS_UTC_Second 0;
BA_ "GenSigTimeoutTime_ECM" SG_ 156 GPS_UTC_Second 0;
BA_ "GenSigTimeoutTime_AGSM" SG_ 156 GPS_UTC_Second 0;
BA_ "GenSigStartValue" SG_ 156 GPS_UTC_Second 65535;
BA_ "GenSigTimeoutTime_SGW" SG_ 753 IDCM_Wakeup_HCP 0;
BA_ "GenSigTimeoutTime_PBWM" SG_ 753 IDCM_Wakeup_HCP 0;
BA_ "GenSigTimeoutTime_IDCM" SG_ 753 IDCM_Wakeup_HCP 0;
BA_ "GenSigTimeoutTime_ECM" SG_ 753 IDCM_Wakeup_HCP 0;
BA_ "GenSigTimeoutTime_DMPI" SG_ 753 IDCM_Wakeup_HCP 0;
BA_ "GenSigTimeoutTime_BPCM" SG_ 753 IDCM_Wakeup_HCP 0;
BA_ "GenSigTimeoutTime_AGSM" SG_ 753 IDCM_Wakeup_HCP 0;
BA_ "GenSigTimeoutTime_SGW" SG_ 753 MessageCounter_LV_CHARGER1 0;
BA_ "GenSigTimeoutTime_PBWM" SG_ 753 MessageCounter_LV_CHARGER1 0;
BA_ "GenSigTimeoutTime_IDCM" SG_ 753 MessageCounter_LV_CHARGER1 0;
BA_ "GenSigTimeoutTime_EVCU2" SG_ 753 MessageCounter_LV_CHARGER1 0;
BA_ "GenSigTimeoutTime_ECM" SG_ 753 MessageCounter_LV_CHARGER1 0;
BA_ "GenSigTimeoutTime_DMPI" SG_ 753 MessageCounter_LV_CHARGER1 0;
BA_ "GenSigTimeoutTime_BPCM" SG_ 753 MessageCounter_LV_CHARGER1 0;
BA_ "GenSigTimeoutTime_AGSM" SG_ 753 MessageCounter_LV_CHARGER1 0;
BA_ "GenSigTimeoutTime_SGW" SG_ 753 CRC_LV_CHARGER1 0;
BA_ "GenSigTimeoutTime_PBWM" SG_ 753 CRC_LV_CHARGER1 0;
BA_ "GenSigTimeoutTime_IDCM" SG_ 753 CRC_LV_CHARGER1 0;
BA_ "GenSigTimeoutTime_EVCU2" SG_ 753 CRC_LV_CHARGER1 0;
BA_ "GenSigTimeoutTime_ECM" SG_ 753 CRC_LV_CHARGER1 0;
BA_ "GenSigTimeoutTime_DMPI" SG_ 753 CRC_LV_CHARGER1 0;
BA_ "GenSigTimeoutTime_BPCM" SG_ 753 CRC_LV_CHARGER1 0;
BA_ "GenSigTimeoutTime_AGSM" SG_ 753 CRC_LV_CHARGER1 0;
BA_ "GenSigTimeoutTime_SGW" SG_ 1829 TotalOdometer 0;
BA_ "GenSigTimeoutTime_PBWM" SG_ 1829 TotalOdometer 0;
BA_ "GenSigTimeoutTime_EVCU2" SG_ 1829 TotalOdometer 0;
BA_ "GenSigTimeoutTime_ECM" SG_ 1829 TotalOdometer 0;
BA_ "GenSigTimeoutTime_DMPI" SG_ 1829 TotalOdometer 0;
BA_ "GenSigTimeoutTime_BPCM" SG_ 1829 TotalOdometer 0;
BA_ "GenSigTimeoutTime_AGSM" SG_ 1829 TotalOdometer 0;
BA_ "GenSigTimeoutTime_SGW" SG_ 1033 HCP_HoodAjar 0;
BA_ "GenSigTimeoutTime_PBWM" SG_ 1033 HCP_HoodAjar 0;
BA_ "GenSigTimeoutTime_IDCM" SG_ 1033 HCP_HoodAjar 0;
BA_ "GenSigTimeoutTime_EVCU2" SG_ 1033 HCP_HoodAjar 0;
BA_ "GenSigTimeoutTime_DMPI" SG_ 1033 HCP_HoodAjar 0;
BA_ "GenSigTimeoutTime_BPCM" SG_ 1033 HCP_HoodAjar 0;
BA_ "GenSigTimeoutTime_AGSM" SG_ 1033 HCP_HoodAjar 0;
BA_ "GenSigTimeoutTime_SGW" SG_ 1033 IdleCLoopTrq 0;
BA_ "GenSigTimeoutTime_PBWM" SG_ 1033 IdleCLoopTrq 0;
BA_ "GenSigTimeoutTime_IDCM" SG_ 1033 IdleCLoopTrq 0;
BA_ "GenSigTimeoutTime_EVCU2" SG_ 1033 IdleCLoopTrq 0;
BA_ "GenSigTimeoutTime_DMPI" SG_ 1033 IdleCLoopTrq 0;
BA_ "GenSigTimeoutTime_BPCM" SG_ 1033 IdleCLoopTrq 0;
BA_ "GenSigTimeoutTime_AGSM" SG_ 1033 IdleCLoopTrq 0;
BA_ "GenSigStartValue" SG_ 1033 IdleCLoopTrq 511;
BA_ "GenSigTimeoutTime_SGW" SG_ 1032 RadiatorFanSts 0;
BA_ "GenSigTimeoutTime_PBWM" SG_ 1032 RadiatorFanSts 0;
BA_ "GenSigTimeoutTime_IDCM" SG_ 1032 RadiatorFanSts 0;
BA_ "GenSigTimeoutTime_EVCU2" SG_ 1032 RadiatorFanSts 0;
BA_ "GenSigTimeoutTime_BPCM" SG_ 1032 RadiatorFanSts 0;
BA_ "GenSigTimeoutTime_AGSM" SG_ 1032 RadiatorFanSts 0;
BA_ "GenSigTimeoutTime_SGW" SG_ 1033 HCPMaxEngRPM 0;
BA_ "GenSigTimeoutTime_PBWM" SG_ 1033 HCPMaxEngRPM 0;
BA_ "GenSigTimeoutTime_IDCM" SG_ 1033 HCPMaxEngRPM 0;
BA_ "GenSigTimeoutTime_EVCU2" SG_ 1033 HCPMaxEngRPM 0;
BA_ "GenSigTimeoutTime_DMPI" SG_ 1033 HCPMaxEngRPM 0;
BA_ "GenSigTimeoutTime_BPCM" SG_ 1033 HCPMaxEngRPM 0;
BA_ "GenSigTimeoutTime_AGSM" SG_ 1033 HCPMaxEngRPM 0;
BA_ "GenSigStartValue" SG_ 1033 HCPMaxEngRPM 255;
BA_ "GenSigTimeoutTime_SGW" SG_ 1033 HEV_HybPwrtrnRdcdPerfCmnd 0;
BA_ "GenSigTimeoutTime_PBWM" SG_ 1033 HEV_HybPwrtrnRdcdPerfCmnd 0;
BA_ "GenSigTimeoutTime_IDCM" SG_ 1033 HEV_HybPwrtrnRdcdPerfCmnd 0;
BA_ "GenSigTimeoutTime_EVCU2" SG_ 1033 HEV_HybPwrtrnRdcdPerfCmnd 0;
BA_ "GenSigTimeoutTime_DMPI" SG_ 1033 HEV_HybPwrtrnRdcdPerfCmnd 0;
BA_ "GenSigTimeoutTime_BPCM" SG_ 1033 HEV_HybPwrtrnRdcdPerfCmnd 0;
BA_ "GenSigTimeoutTime_AGSM" SG_ 1033 HEV_HybPwrtrnRdcdPerfCmnd 0;
BA_ "GenSigTimeoutTime_SGW" SG_ 1033 MessageCounter_HYBRID_POWERTRAI 0;
BA_ "GenSigTimeoutTime_PBWM" SG_ 1033 MessageCounter_HYBRID_POWERTRAI 0;
BA_ "GenSigTimeoutTime_IDCM" SG_ 1033 MessageCounter_HYBRID_POWERTRAI 0;
BA_ "GenSigTimeoutTime_EVCU2" SG_ 1033 MessageCounter_HYBRID_POWERTRAI 0;
BA_ "GenSigTimeoutTime_DMPI" SG_ 1033 MessageCounter_HYBRID_POWERTRAI 0;
BA_ "GenSigTimeoutTime_BPCM" SG_ 1033 MessageCounter_HYBRID_POWERTRAI 0;
BA_ "GenSigTimeoutTime_AGSM" SG_ 1033 MessageCounter_HYBRID_POWERTRAI 0;
BA_ "SystemSignalLongSymbol" SG_ 1033 MessageCounter_HYBRID_POWERTRAI "MessageCounter_HYBRID_POWERTRAIN5";
BA_ "GenSigTimeoutTime_SGW" SG_ 269 IdleSpeedActiveSts 0;
BA_ "GenSigTimeoutTime_PBWM" SG_ 269 IdleSpeedActiveSts 0;
BA_ "GenSigTimeoutTime_IDCM" SG_ 269 IdleSpeedActiveSts 0;
BA_ "GenSigTimeoutTime_EVCU2" SG_ 269 IdleSpeedActiveSts 0;
BA_ "GenSigTimeoutTime_DMPI" SG_ 269 IdleSpeedActiveSts 0;
BA_ "GenSigTimeoutTime_BPCM" SG_ 269 IdleSpeedActiveSts 0;
BA_ "GenSigTimeoutTime_AGSM" SG_ 269 IdleSpeedActiveSts 0;
BA_ "GenSigTimeoutTime_SGW" SG_ 269 MessageCounter_HYBRID_POWERTRAI 0;
BA_ "GenSigTimeoutTime_PBWM" SG_ 269 MessageCounter_HYBRID_POWERTRAI 0;
BA_ "GenSigTimeoutTime_IDCM" SG_ 269 MessageCounter_HYBRID_POWERTRAI 0;
BA_ "GenSigTimeoutTime_EVCU2" SG_ 269 MessageCounter_HYBRID_POWERTRAI 0;
BA_ "GenSigTimeoutTime_DMPI" SG_ 269 MessageCounter_HYBRID_POWERTRAI 0;
BA_ "GenSigTimeoutTime_BPCM" SG_ 269 MessageCounter_HYBRID_POWERTRAI 0;
BA_ "GenSigTimeoutTime_AGSM" SG_ 269 MessageCounter_HYBRID_POWERTRAI 0;
BA_ "SystemSignalLongSymbol" SG_ 269 MessageCounter_HYBRID_POWERTRAI "MessageCounter_HYBRID_POWERTRAIN2";
BA_ "GenSigTimeoutTime_SGW" SG_ 1033 CRC_HYBRID_POWERTRAIN5 0;
BA_ "GenSigTimeoutTime_PBWM" SG_ 1033 CRC_HYBRID_POWERTRAIN5 0;
BA_ "GenSigTimeoutTime_IDCM" SG_ 1033 CRC_HYBRID_POWERTRAIN5 0;
BA_ "GenSigTimeoutTime_EVCU2" SG_ 1033 CRC_HYBRID_POWERTRAIN5 0;
BA_ "GenSigTimeoutTime_DMPI" SG_ 1033 CRC_HYBRID_POWERTRAIN5 0;
BA_ "GenSigTimeoutTime_BPCM" SG_ 1033 CRC_HYBRID_POWERTRAIN5 0;
BA_ "GenSigTimeoutTime_AGSM" SG_ 1033 CRC_HYBRID_POWERTRAIN5 0;
BA_ "GenSigTimeoutTime_SGW" SG_ 269 CRC_HYBRID_POWERTRAIN2 0;
BA_ "GenSigTimeoutTime_PBWM" SG_ 269 CRC_HYBRID_POWERTRAIN2 0;
BA_ "GenSigTimeoutTime_IDCM" SG_ 269 CRC_HYBRID_POWERTRAIN2 0;
BA_ "GenSigTimeoutTime_EVCU2" SG_ 269 CRC_HYBRID_POWERTRAIN2 0;
BA_ "GenSigTimeoutTime_DMPI" SG_ 269 CRC_HYBRID_POWERTRAIN2 0;
BA_ "GenSigTimeoutTime_BPCM" SG_ 269 CRC_HYBRID_POWERTRAIN2 0;
BA_ "GenSigTimeoutTime_AGSM" SG_ 269 CRC_HYBRID_POWERTRAIN2 0;
BA_ "GenSigTimeoutTime_SGW" SG_ 269 REPRGD_PFC_CLR_HCP 0;
BA_ "GenSigTimeoutTime_PBWM" SG_ 269 REPRGD_PFC_CLR_HCP 0;
BA_ "GenSigTimeoutTime_IDCM" SG_ 269 REPRGD_PFC_CLR_HCP 0;
BA_ "GenSigTimeoutTime_EVCU2" SG_ 269 REPRGD_PFC_CLR_HCP 0;
BA_ "GenSigTimeoutTime_DMPI" SG_ 269 REPRGD_PFC_CLR_HCP 0;
BA_ "GenSigTimeoutTime_BPCM" SG_ 269 REPRGD_PFC_CLR_HCP 0;
BA_ "GenSigTimeoutTime_AGSM" SG_ 269 REPRGD_PFC_CLR_HCP 0;
BA_ "GenSigTimeoutTime_SGW" SG_ 1033 Hybrid_EVT_ModeSts 0;
BA_ "GenSigTimeoutTime_PBWM" SG_ 1033 Hybrid_EVT_ModeSts 0;
BA_ "GenSigTimeoutTime_IDCM" SG_ 1033 Hybrid_EVT_ModeSts 0;
BA_ "GenSigTimeoutTime_EVCU2" SG_ 1033 Hybrid_EVT_ModeSts 0;
BA_ "GenSigTimeoutTime_ECM" SG_ 1033 Hybrid_EVT_ModeSts 0;
BA_ "GenSigTimeoutTime_DMPI" SG_ 1033 Hybrid_EVT_ModeSts 0;
BA_ "GenSigTimeoutTime_BPCM" SG_ 1033 Hybrid_EVT_ModeSts 0;
BA_ "GenSigTimeoutTime_AGSM" SG_ 1033 Hybrid_EVT_ModeSts 0;
BA_ "GenSigTimeoutTime_SGW" SG_ 269 HybridEngineMaxTorqAllowed 0;
BA_ "GenSigTimeoutTime_PBWM" SG_ 269 HybridEngineMaxTorqAllowed 0;
BA_ "GenSigTimeoutTime_IDCM" SG_ 269 HybridEngineMaxTorqAllowed 0;
BA_ "GenSigTimeoutTime_EVCU2" SG_ 269 HybridEngineMaxTorqAllowed 0;
BA_ "GenSigTimeoutTime_DMPI" SG_ 269 HybridEngineMaxTorqAllowed 0;
BA_ "GenSigTimeoutTime_BPCM" SG_ 269 HybridEngineMaxTorqAllowed 0;
BA_ "GenSigTimeoutTime_AGSM" SG_ 269 HybridEngineMaxTorqAllowed 0;
BA_ "GenSigStartValue" SG_ 269 HybridEngineMaxTorqAllowed 938;
BA_ "GenSigTimeoutTime_SGW" SG_ 267 WU_Timer_Value 0;
BA_ "GenSigTimeoutTime_PBWM" SG_ 267 WU_Timer_Value 0;
BA_ "GenSigTimeoutTime_EVCU2" SG_ 267 WU_Timer_Value 0;
BA_ "GenSigTimeoutTime_ECM" SG_ 267 WU_Timer_Value 0;
BA_ "GenSigTimeoutTime_DMPI" SG_ 267 WU_Timer_Value 0;
BA_ "GenSigTimeoutTime_AGSM" SG_ 267 WU_Timer_Value 0;
BA_ "GenSigTimeoutTime_SGW" SG_ 269 PropulsionMode 0;
BA_ "GenSigTimeoutTime_PBWM" SG_ 269 PropulsionMode 0;
BA_ "GenSigTimeoutTime_IDCM" SG_ 269 PropulsionMode 0;
BA_ "GenSigTimeoutTime_EVCU2" SG_ 269 PropulsionMode 0;
BA_ "GenSigTimeoutTime_DMPI" SG_ 269 PropulsionMode 0;
BA_ "GenSigTimeoutTime_BPCM" SG_ 269 PropulsionMode 0;
BA_ "GenSigTimeoutTime_AGSM" SG_ 269 PropulsionMode 0;
BA_ "GenSigTimeoutTime_SGW" SG_ 267 HCP_ShutdownCommand 0;
BA_ "GenSigTimeoutTime_PBWM" SG_ 267 HCP_ShutdownCommand 0;
BA_ "GenSigTimeoutTime_IDCM" SG_ 267 HCP_ShutdownCommand 0;
BA_ "GenSigTimeoutTime_EVCU2" SG_ 267 HCP_ShutdownCommand 0;
BA_ "GenSigTimeoutTime_ECM" SG_ 267 HCP_ShutdownCommand 0;
BA_ "GenSigTimeoutTime_DMPI" SG_ 267 HCP_ShutdownCommand 0;
BA_ "GenSigTimeoutTime_AGSM" SG_ 267 HCP_ShutdownCommand 0;
BA_ "GenSigTimeoutTime_SGW" SG_ 267 PerWakeUp_Diag 0;
BA_ "GenSigTimeoutTime_PBWM" SG_ 267 PerWakeUp_Diag 0;
BA_ "GenSigTimeoutTime_EVCU2" SG_ 267 PerWakeUp_Diag 0;
BA_ "GenSigTimeoutTime_ECM" SG_ 267 PerWakeUp_Diag 0;
BA_ "GenSigTimeoutTime_DMPI" SG_ 267 PerWakeUp_Diag 0;
BA_ "GenSigTimeoutTime_AGSM" SG_ 267 PerWakeUp_Diag 0;
BA_ "GenSigTimeoutTime_SGW" SG_ 269 CODE_CLR_HCP 0;
BA_ "GenSigTimeoutTime_PBWM" SG_ 269 CODE_CLR_HCP 0;
BA_ "GenSigTimeoutTime_IDCM" SG_ 269 CODE_CLR_HCP 0;
BA_ "GenSigTimeoutTime_EVCU2" SG_ 269 CODE_CLR_HCP 0;
BA_ "GenSigTimeoutTime_DMPI" SG_ 269 CODE_CLR_HCP 0;
BA_ "GenSigTimeoutTime_BPCM" SG_ 269 CODE_CLR_HCP 0;
BA_ "GenSigTimeoutTime_AGSM" SG_ 269 CODE_CLR_HCP 0;
BA_ "GenSigTimeoutTime_SGW" SG_ 266 CODE_CLR_BPCM 0;
BA_ "GenSigTimeoutTime_PBWM" SG_ 266 CODE_CLR_BPCM 0;
BA_ "GenSigTimeoutTime_IDCM" SG_ 266 CODE_CLR_BPCM 0;
BA_ "GenSigTimeoutTime_EVCU2" SG_ 266 CODE_CLR_BPCM 0;
BA_ "GenSigTimeoutTime_DMPI" SG_ 266 CODE_CLR_BPCM 0;
BA_ "GenSigTimeoutTime_BPCM" SG_ 266 CODE_CLR_BPCM 0;
BA_ "GenSigTimeoutTime_AGSM" SG_ 266 CODE_CLR_BPCM 0;
BA_ "GenSigTimeoutTime_SGW" SG_ 266 REPRGD_PFC_CLR_BPCM 0;
BA_ "GenSigTimeoutTime_PBWM" SG_ 266 REPRGD_PFC_CLR_BPCM 0;
BA_ "GenSigTimeoutTime_IDCM" SG_ 266 REPRGD_PFC_CLR_BPCM 0;
BA_ "GenSigTimeoutTime_EVCU2" SG_ 266 REPRGD_PFC_CLR_BPCM 0;
BA_ "GenSigTimeoutTime_DMPI" SG_ 266 REPRGD_PFC_CLR_BPCM 0;
BA_ "GenSigTimeoutTime_BPCM" SG_ 266 REPRGD_PFC_CLR_BPCM 0;
BA_ "GenSigTimeoutTime_AGSM" SG_ 266 REPRGD_PFC_CLR_BPCM 0;
BA_ "GenSigTimeoutTime_SGW" SG_ 1839 HVBatModuleTemp_33 0;
BA_ "GenSigTimeoutTime_PBWM" SG_ 1839 HVBatModuleTemp_33 0;
BA_ "GenSigTimeoutTime_IDCM" SG_ 1839 HVBatModuleTemp_33 0;
BA_ "GenSigTimeoutTime_EVCU2" SG_ 1839 HVBatModuleTemp_33 0;
BA_ "GenSigTimeoutTime_ECM" SG_ 1839 HVBatModuleTemp_33 0;
BA_ "GenSigTimeoutTime_DMPI" SG_ 1839 HVBatModuleTemp_33 0;
BA_ "GenSigTimeoutTime_BPCM" SG_ 1839 HVBatModuleTemp_33 0;
BA_ "GenSigTimeoutTime_AGSM" SG_ 1839 HVBatModuleTemp_33 0;
BA_ "GenSigTimeoutTime_SGW" SG_ 1839 HVBatModuleTemp_34 0;
BA_ "GenSigTimeoutTime_PBWM" SG_ 1839 HVBatModuleTemp_34 0;
BA_ "GenSigTimeoutTime_IDCM" SG_ 1839 HVBatModuleTemp_34 0;
BA_ "GenSigTimeoutTime_EVCU2" SG_ 1839 HVBatModuleTemp_34 0;
BA_ "GenSigTimeoutTime_ECM" SG_ 1839 HVBatModuleTemp_34 0;
BA_ "GenSigTimeoutTime_DMPI" SG_ 1839 HVBatModuleTemp_34 0;
BA_ "GenSigTimeoutTime_BPCM" SG_ 1839 HVBatModuleTemp_34 0;
BA_ "GenSigTimeoutTime_AGSM" SG_ 1839 HVBatModuleTemp_34 0;
BA_ "GenSigTimeoutTime_SGW" SG_ 1839 HVBatModuleTemp_35 0;
BA_ "GenSigTimeoutTime_PBWM" SG_ 1839 HVBatModuleTemp_35 0;
BA_ "GenSigTimeoutTime_IDCM" SG_ 1839 HVBatModuleTemp_35 0;
BA_ "GenSigTimeoutTime_EVCU2" SG_ 1839 HVBatModuleTemp_35 0;
BA_ "GenSigTimeoutTime_ECM" SG_ 1839 HVBatModuleTemp_35 0;
BA_ "GenSigTimeoutTime_DMPI" SG_ 1839 HVBatModuleTemp_35 0;
BA_ "GenSigTimeoutTime_BPCM" SG_ 1839 HVBatModuleTemp_35 0;
BA_ "GenSigTimeoutTime_AGSM" SG_ 1839 HVBatModuleTemp_35 0;
BA_ "GenSigTimeoutTime_SGW" SG_ 1839 HVBatModuleTemp_36 0;
BA_ "GenSigTimeoutTime_PBWM" SG_ 1839 HVBatModuleTemp_36 0;
BA_ "GenSigTimeoutTime_IDCM" SG_ 1839 HVBatModuleTemp_36 0;
BA_ "GenSigTimeoutTime_EVCU2" SG_ 1839 HVBatModuleTemp_36 0;
BA_ "GenSigTimeoutTime_ECM" SG_ 1839 HVBatModuleTemp_36 0;
BA_ "GenSigTimeoutTime_DMPI" SG_ 1839 HVBatModuleTemp_36 0;
BA_ "GenSigTimeoutTime_BPCM" SG_ 1839 HVBatModuleTemp_36 0;
BA_ "GenSigTimeoutTime_AGSM" SG_ 1839 HVBatModuleTemp_36 0;
BA_ "GenSigTimeoutTime_SGW" SG_ 1839 HVBatModuleTemp_37 0;
BA_ "GenSigTimeoutTime_PBWM" SG_ 1839 HVBatModuleTemp_37 0;
BA_ "GenSigTimeoutTime_IDCM" SG_ 1839 HVBatModuleTemp_37 0;
BA_ "GenSigTimeoutTime_EVCU2" SG_ 1839 HVBatModuleTemp_37 0;
BA_ "GenSigTimeoutTime_ECM" SG_ 1839 HVBatModuleTemp_37 0;
BA_ "GenSigTimeoutTime_DMPI" SG_ 1839 HVBatModuleTemp_37 0;
BA_ "GenSigTimeoutTime_BPCM" SG_ 1839 HVBatModuleTemp_37 0;
BA_ "GenSigTimeoutTime_AGSM" SG_ 1839 HVBatModuleTemp_37 0;
BA_ "GenSigTimeoutTime_SGW" SG_ 1839 HVBatModuleTemp_38 0;
BA_ "GenSigTimeoutTime_PBWM" SG_ 1839 HVBatModuleTemp_38 0;
BA_ "GenSigTimeoutTime_IDCM" SG_ 1839 HVBatModuleTemp_38 0;
BA_ "GenSigTimeoutTime_EVCU2" SG_ 1839 HVBatModuleTemp_38 0;
BA_ "GenSigTimeoutTime_ECM" SG_ 1839 HVBatModuleTemp_38 0;
BA_ "GenSigTimeoutTime_DMPI" SG_ 1839 HVBatModuleTemp_38 0;
BA_ "GenSigTimeoutTime_BPCM" SG_ 1839 HVBatModuleTemp_38 0;
BA_ "GenSigTimeoutTime_AGSM" SG_ 1839 HVBatModuleTemp_38 0;
BA_ "GenSigTimeoutTime_SGW" SG_ 1839 HVBatModuleTemp_27 0;
BA_ "GenSigTimeoutTime_PBWM" SG_ 1839 HVBatModuleTemp_27 0;
BA_ "GenSigTimeoutTime_IDCM" SG_ 1839 HVBatModuleTemp_27 0;
BA_ "GenSigTimeoutTime_EVCU2" SG_ 1839 HVBatModuleTemp_27 0;
BA_ "GenSigTimeoutTime_ECM" SG_ 1839 HVBatModuleTemp_27 0;
BA_ "GenSigTimeoutTime_DMPI" SG_ 1839 HVBatModuleTemp_27 0;
BA_ "GenSigTimeoutTime_BPCM" SG_ 1839 HVBatModuleTemp_27 0;
BA_ "GenSigTimeoutTime_AGSM" SG_ 1839 HVBatModuleTemp_27 0;
BA_ "GenSigTimeoutTime_SGW" SG_ 1839 HVBatModuleTemp_28 0;
BA_ "GenSigTimeoutTime_PBWM" SG_ 1839 HVBatModuleTemp_28 0;
BA_ "GenSigTimeoutTime_IDCM" SG_ 1839 HVBatModuleTemp_28 0;
BA_ "GenSigTimeoutTime_EVCU2" SG_ 1839 HVBatModuleTemp_28 0;
BA_ "GenSigTimeoutTime_ECM" SG_ 1839 HVBatModuleTemp_28 0;
BA_ "GenSigTimeoutTime_DMPI" SG_ 1839 HVBatModuleTemp_28 0;
BA_ "GenSigTimeoutTime_BPCM" SG_ 1839 HVBatModuleTemp_28 0;
BA_ "GenSigTimeoutTime_AGSM" SG_ 1839 HVBatModuleTemp_28 0;
BA_ "GenSigTimeoutTime_SGW" SG_ 1839 HVBatModuleTemp_29 0;
BA_ "GenSigTimeoutTime_PBWM" SG_ 1839 HVBatModuleTemp_29 0;
BA_ "GenSigTimeoutTime_IDCM" SG_ 1839 HVBatModuleTemp_29 0;
BA_ "GenSigTimeoutTime_EVCU2" SG_ 1839 HVBatModuleTemp_29 0;
BA_ "GenSigTimeoutTime_ECM" SG_ 1839 HVBatModuleTemp_29 0;
BA_ "GenSigTimeoutTime_DMPI" SG_ 1839 HVBatModuleTemp_29 0;
BA_ "GenSigTimeoutTime_BPCM" SG_ 1839 HVBatModuleTemp_29 0;
BA_ "GenSigTimeoutTime_AGSM" SG_ 1839 HVBatModuleTemp_29 0;
BA_ "GenSigTimeoutTime_EVCU2" SG_ 1839 HVBatModuleTemp_30 0;
BA_ "GenSigTimeoutTime_ECM" SG_ 1839 HVBatModuleTemp_30 0;
BA_ "GenSigTimeoutTime_DMPI" SG_ 1839 HVBatModuleTemp_30 0;
BA_ "GenSigTimeoutTime_BPCM" SG_ 1839 HVBatModuleTemp_30 0;
BA_ "GenSigTimeoutTime_AGSM" SG_ 1839 HVBatModuleTemp_30 0;
BA_ "GenSigTimeoutTime_SGW" SG_ 1839 HVBatModuleTemp_30 0;
BA_ "GenSigTimeoutTime_PBWM" SG_ 1839 HVBatModuleTemp_30 0;
BA_ "GenSigTimeoutTime_IDCM" SG_ 1839 HVBatModuleTemp_30 0;
BA_ "GenSigTimeoutTime_SGW" SG_ 1839 HVBatModuleTemp_31 0;
BA_ "GenSigTimeoutTime_PBWM" SG_ 1839 HVBatModuleTemp_31 0;
BA_ "GenSigTimeoutTime_IDCM" SG_ 1839 HVBatModuleTemp_31 0;
BA_ "GenSigTimeoutTime_EVCU2" SG_ 1839 HVBatModuleTemp_31 0;
BA_ "GenSigTimeoutTime_ECM" SG_ 1839 HVBatModuleTemp_31 0;
BA_ "GenSigTimeoutTime_DMPI" SG_ 1839 HVBatModuleTemp_31 0;
BA_ "GenSigTimeoutTime_BPCM" SG_ 1839 HVBatModuleTemp_31 0;
BA_ "GenSigTimeoutTime_AGSM" SG_ 1839 HVBatModuleTemp_31 0;
BA_ "GenSigTimeoutTime_SGW" SG_ 1839 HVBatModuleTemp_32 0;
BA_ "GenSigTimeoutTime_PBWM" SG_ 1839 HVBatModuleTemp_32 0;
BA_ "GenSigTimeoutTime_IDCM" SG_ 1839 HVBatModuleTemp_32 0;
BA_ "GenSigTimeoutTime_EVCU2" SG_ 1839 HVBatModuleTemp_32 0;
BA_ "GenSigTimeoutTime_ECM" SG_ 1839 HVBatModuleTemp_32 0;
BA_ "GenSigTimeoutTime_DMPI" SG_ 1839 HVBatModuleTemp_32 0;
BA_ "GenSigTimeoutTime_BPCM" SG_ 1839 HVBatModuleTemp_32 0;
BA_ "GenSigTimeoutTime_AGSM" SG_ 1839 HVBatModuleTemp_32 0;
BA_ "GenSigTimeoutTime_BPCM" SG_ 1840 Warning_PackUndervoltage 0;
BA_ "GenSigTimeoutTime_AGSM" SG_ 1840 Warning_PackUndervoltage 0;
BA_ "GenSigTimeoutTime_PBWM" SG_ 1838 HVBatCellVoltage_Cell105 0;
BA_ "GenSigTimeoutTime_IDCM" SG_ 1838 HVBatCellVoltage_Cell105 0;
BA_ "GenSigTimeoutTime_EVCU2" SG_ 1838 HVBatCellVoltage_Cell105 0;
BA_ "GenSigTimeoutTime_ECM" SG_ 1838 HVBatCellVoltage_Cell105 0;
BA_ "GenSigTimeoutTime_DMPI" SG_ 1838 HVBatCellVoltage_Cell105 0;
BA_ "GenSigTimeoutTime_BPCM" SG_ 1838 HVBatCellVoltage_Cell105 0;
BA_ "GenSigTimeoutTime_AGSM" SG_ 1838 HVBatCellVoltage_Cell105 0;
BA_ "GenSigTimeoutTime_PBWM" SG_ 1838 HVBatCellVoltage_Cell106 0;
BA_ "GenSigTimeoutTime_IDCM" SG_ 1838 HVBatCellVoltage_Cell106 0;
BA_ "GenSigTimeoutTime_EVCU2" SG_ 1838 HVBatCellVoltage_Cell106 0;
BA_ "GenSigTimeoutTime_ECM" SG_ 1838 HVBatCellVoltage_Cell106 0;
BA_ "GenSigTimeoutTime_DMPI" SG_ 1838 HVBatCellVoltage_Cell106 0;
BA_ "GenSigTimeoutTime_BPCM" SG_ 1838 HVBatCellVoltage_Cell106 0;
BA_ "GenSigTimeoutTime_AGSM" SG_ 1838 HVBatCellVoltage_Cell106 0;
BA_ "GenSigTimeoutTime_PBWM" SG_ 1838 HVBatCellVoltage_Cell107 0;
BA_ "GenSigTimeoutTime_IDCM" SG_ 1838 HVBatCellVoltage_Cell107 0;
BA_ "GenSigTimeoutTime_EVCU2" SG_ 1838 HVBatCellVoltage_Cell107 0;
BA_ "GenSigTimeoutTime_ECM" SG_ 1838 HVBatCellVoltage_Cell107 0;
BA_ "GenSigTimeoutTime_DMPI" SG_ 1838 HVBatCellVoltage_Cell107 0;
BA_ "GenSigTimeoutTime_BPCM" SG_ 1838 HVBatCellVoltage_Cell107 0;
BA_ "GenSigTimeoutTime_AGSM" SG_ 1838 HVBatCellVoltage_Cell107 0;
BA_ "GenSigTimeoutTime_PBWM" SG_ 1838 HVBatCellVoltage_Cell108 0;
BA_ "GenSigTimeoutTime_IDCM" SG_ 1838 HVBatCellVoltage_Cell108 0;
BA_ "GenSigTimeoutTime_EVCU2" SG_ 1838 HVBatCellVoltage_Cell108 0;
BA_ "GenSigTimeoutTime_ECM" SG_ 1838 HVBatCellVoltage_Cell108 0;
BA_ "GenSigTimeoutTime_DMPI" SG_ 1838 HVBatCellVoltage_Cell108 0;
BA_ "GenSigTimeoutTime_BPCM" SG_ 1838 HVBatCellVoltage_Cell108 0;
BA_ "GenSigTimeoutTime_AGSM" SG_ 1838 HVBatCellVoltage_Cell108 0;
BA_ "GenSigTimeoutTime_PBWM" SG_ 1838 HVBatCellVoltage_Cell100 0;
BA_ "GenSigTimeoutTime_IDCM" SG_ 1838 HVBatCellVoltage_Cell100 0;
BA_ "GenSigTimeoutTime_EVCU2" SG_ 1838 HVBatCellVoltage_Cell100 0;
BA_ "GenSigTimeoutTime_ECM" SG_ 1838 HVBatCellVoltage_Cell100 0;
BA_ "GenSigTimeoutTime_DMPI" SG_ 1838 HVBatCellVoltage_Cell100 0;
BA_ "GenSigTimeoutTime_PBWM" SG_ 1838 HVBatCellVoltage_Cell101 0;
BA_ "GenSigTimeoutTime_IDCM" SG_ 1838 HVBatCellVoltage_Cell101 0;
BA_ "GenSigTimeoutTime_EVCU2" SG_ 1838 HVBatCellVoltage_Cell101 0;
BA_ "GenSigTimeoutTime_ECM" SG_ 1838 HVBatCellVoltage_Cell101 0;
BA_ "GenSigTimeoutTime_DMPI" SG_ 1838 HVBatCellVoltage_Cell101 0;
BA_ "GenSigTimeoutTime_BPCM" SG_ 1838 HVBatCellVoltage_Cell101 0;
BA_ "GenSigTimeoutTime_AGSM" SG_ 1838 HVBatCellVoltage_Cell101 0;
BA_ "GenSigTimeoutTime_PBWM" SG_ 1838 HVBatCellVoltage_Cell102 0;
BA_ "GenSigTimeoutTime_IDCM" SG_ 1838 HVBatCellVoltage_Cell102 0;
BA_ "GenSigTimeoutTime_EVCU2" SG_ 1838 HVBatCellVoltage_Cell102 0;
BA_ "GenSigTimeoutTime_ECM" SG_ 1838 HVBatCellVoltage_Cell102 0;
BA_ "GenSigTimeoutTime_DMPI" SG_ 1838 HVBatCellVoltage_Cell102 0;
BA_ "GenSigTimeoutTime_BPCM" SG_ 1838 HVBatCellVoltage_Cell102 0;
BA_ "GenSigTimeoutTime_AGSM" SG_ 1838 HVBatCellVoltage_Cell102 0;
BA_ "GenSigTimeoutTime_PBWM" SG_ 1838 HVBatCellVoltage_Cell103 0;
BA_ "GenSigTimeoutTime_IDCM" SG_ 1838 HVBatCellVoltage_Cell103 0;
BA_ "GenSigTimeoutTime_EVCU2" SG_ 1838 HVBatCellVoltage_Cell103 0;
BA_ "GenSigTimeoutTime_ECM" SG_ 1838 HVBatCellVoltage_Cell103 0;
BA_ "GenSigTimeoutTime_DMPI" SG_ 1838 HVBatCellVoltage_Cell103 0;
BA_ "GenSigTimeoutTime_BPCM" SG_ 1838 HVBatCellVoltage_Cell103 0;
BA_ "GenSigTimeoutTime_AGSM" SG_ 1838 HVBatCellVoltage_Cell103 0;
BA_ "GenSigTimeoutTime_BPCM" SG_ 1838 HVBatCellVoltage_Cell104 0;
BA_ "GenSigTimeoutTime_AGSM" SG_ 1838 HVBatCellVoltage_Cell104 0;
BA_ "GenSigTimeoutTime_PBWM" SG_ 1838 HVBatCellVoltage_Cell104 0;
BA_ "GenSigTimeoutTime_IDCM" SG_ 1838 HVBatCellVoltage_Cell104 0;
BA_ "GenSigTimeoutTime_EVCU2" SG_ 1838 HVBatCellVoltage_Cell104 0;
BA_ "GenSigTimeoutTime_ECM" SG_ 1838 HVBatCellVoltage_Cell104 0;
BA_ "GenSigTimeoutTime_DMPI" SG_ 1838 HVBatCellVoltage_Cell104 0;
BA_ "GenSigTimeoutTime_BPCM" SG_ 1838 HVBatCellVoltage_Cell100 0;
BA_ "GenSigTimeoutTime_AGSM" SG_ 1838 HVBatCellVoltage_Cell100 0;
BA_ "GenSigTimeoutTime_PBWM" SG_ 1838 HVBatCellVoltage_Cell099 0;
BA_ "GenSigTimeoutTime_IDCM" SG_ 1838 HVBatCellVoltage_Cell099 0;
BA_ "GenSigTimeoutTime_EVCU2" SG_ 1838 HVBatCellVoltage_Cell099 0;
BA_ "GenSigTimeoutTime_ECM" SG_ 1838 HVBatCellVoltage_Cell099 0;
BA_ "GenSigTimeoutTime_DMPI" SG_ 1838 HVBatCellVoltage_Cell099 0;
BA_ "GenSigTimeoutTime_BPCM" SG_ 1838 HVBatCellVoltage_Cell099 0;
BA_ "GenSigTimeoutTime_AGSM" SG_ 1838 HVBatCellVoltage_Cell099 0;
BA_ "GenSigTimeoutTime_PBWM" SG_ 1838 HVBatCellVoltage_Cell097 0;
BA_ "GenSigTimeoutTime_IDCM" SG_ 1838 HVBatCellVoltage_Cell097 0;
BA_ "GenSigTimeoutTime_EVCU2" SG_ 1838 HVBatCellVoltage_Cell097 0;
BA_ "GenSigTimeoutTime_ECM" SG_ 1838 HVBatCellVoltage_Cell097 0;
BA_ "GenSigTimeoutTime_DMPI" SG_ 1838 HVBatCellVoltage_Cell097 0;
BA_ "GenSigTimeoutTime_BPCM" SG_ 1838 HVBatCellVoltage_Cell097 0;
BA_ "GenSigTimeoutTime_AGSM" SG_ 1838 HVBatCellVoltage_Cell097 0;
BA_ "GenSigTimeoutTime_PBWM" SG_ 1838 HVBatCellVoltage_Cell098 0;
BA_ "GenSigTimeoutTime_IDCM" SG_ 1838 HVBatCellVoltage_Cell098 0;
BA_ "GenSigTimeoutTime_EVCU2" SG_ 1838 HVBatCellVoltage_Cell098 0;
BA_ "GenSigTimeoutTime_ECM" SG_ 1838 HVBatCellVoltage_Cell098 0;
BA_ "GenSigTimeoutTime_DMPI" SG_ 1838 HVBatCellVoltage_Cell098 0;
BA_ "GenSigTimeoutTime_BPCM" SG_ 1838 HVBatCellVoltage_Cell098 0;
BA_ "GenSigTimeoutTime_AGSM" SG_ 1838 HVBatCellVoltage_Cell098 0;
BA_ "GenSigTimeoutTime_PBWM" SG_ 1838 HVBatCellVoltage_Cell096 0;
BA_ "GenSigTimeoutTime_IDCM" SG_ 1838 HVBatCellVoltage_Cell096 0;
BA_ "GenSigTimeoutTime_EVCU2" SG_ 1838 HVBatCellVoltage_Cell096 0;
BA_ "GenSigTimeoutTime_ECM" SG_ 1838 HVBatCellVoltage_Cell096 0;
BA_ "GenSigTimeoutTime_DMPI" SG_ 1838 HVBatCellVoltage_Cell096 0;
BA_ "GenSigTimeoutTime_BPCM" SG_ 1838 HVBatCellVoltage_Cell096 0;
BA_ "GenSigTimeoutTime_AGSM" SG_ 1838 HVBatCellVoltage_Cell096 0;
BA_ "GenSigTimeoutTime_PBWM" SG_ 1838 HVBatCellVoltage_Cell094 0;
BA_ "GenSigTimeoutTime_IDCM" SG_ 1838 HVBatCellVoltage_Cell094 0;
BA_ "GenSigTimeoutTime_EVCU2" SG_ 1838 HVBatCellVoltage_Cell094 0;
BA_ "GenSigTimeoutTime_ECM" SG_ 1838 HVBatCellVoltage_Cell094 0;
BA_ "GenSigTimeoutTime_DMPI" SG_ 1838 HVBatCellVoltage_Cell094 0;
BA_ "GenSigTimeoutTime_BPCM" SG_ 1838 HVBatCellVoltage_Cell094 0;
BA_ "GenSigTimeoutTime_AGSM" SG_ 1838 HVBatCellVoltage_Cell094 0;
BA_ "GenSigTimeoutTime_PBWM" SG_ 1838 HVBatCellVoltage_Cell095 0;
BA_ "GenSigTimeoutTime_IDCM" SG_ 1838 HVBatCellVoltage_Cell095 0;
BA_ "GenSigTimeoutTime_EVCU2" SG_ 1838 HVBatCellVoltage_Cell095 0;
BA_ "GenSigTimeoutTime_ECM" SG_ 1838 HVBatCellVoltage_Cell095 0;
BA_ "GenSigTimeoutTime_DMPI" SG_ 1838 HVBatCellVoltage_Cell095 0;
BA_ "GenSigTimeoutTime_BPCM" SG_ 1838 HVBatCellVoltage_Cell095 0;
BA_ "GenSigTimeoutTime_AGSM" SG_ 1838 HVBatCellVoltage_Cell095 0;
BA_ "GenSigTimeoutTime_PBWM" SG_ 1838 HVBatCellVoltage_Cell090 0;
BA_ "GenSigTimeoutTime_IDCM" SG_ 1838 HVBatCellVoltage_Cell090 0;
BA_ "GenSigTimeoutTime_EVCU2" SG_ 1838 HVBatCellVoltage_Cell090 0;
BA_ "GenSigTimeoutTime_ECM" SG_ 1838 HVBatCellVoltage_Cell090 0;
BA_ "GenSigTimeoutTime_DMPI" SG_ 1838 HVBatCellVoltage_Cell090 0;
BA_ "GenSigTimeoutTime_BPCM" SG_ 1838 HVBatCellVoltage_Cell090 0;
BA_ "GenSigTimeoutTime_AGSM" SG_ 1838 HVBatCellVoltage_Cell090 0;
BA_ "GenSigTimeoutTime_PBWM" SG_ 1838 HVBatCellVoltage_Cell091 0;
BA_ "GenSigTimeoutTime_IDCM" SG_ 1838 HVBatCellVoltage_Cell091 0;
BA_ "GenSigTimeoutTime_EVCU2" SG_ 1838 HVBatCellVoltage_Cell091 0;
BA_ "GenSigTimeoutTime_ECM" SG_ 1838 HVBatCellVoltage_Cell091 0;
BA_ "GenSigTimeoutTime_DMPI" SG_ 1838 HVBatCellVoltage_Cell091 0;
BA_ "GenSigTimeoutTime_BPCM" SG_ 1838 HVBatCellVoltage_Cell091 0;
BA_ "GenSigTimeoutTime_AGSM" SG_ 1838 HVBatCellVoltage_Cell091 0;
BA_ "GenSigTimeoutTime_PBWM" SG_ 1838 HVBatCellVoltage_Cell092 0;
BA_ "GenSigTimeoutTime_IDCM" SG_ 1838 HVBatCellVoltage_Cell092 0;
BA_ "GenSigTimeoutTime_EVCU2" SG_ 1838 HVBatCellVoltage_Cell092 0;
BA_ "GenSigTimeoutTime_ECM" SG_ 1838 HVBatCellVoltage_Cell092 0;
BA_ "GenSigTimeoutTime_DMPI" SG_ 1838 HVBatCellVoltage_Cell092 0;
BA_ "GenSigTimeoutTime_BPCM" SG_ 1838 HVBatCellVoltage_Cell092 0;
BA_ "GenSigTimeoutTime_AGSM" SG_ 1838 HVBatCellVoltage_Cell092 0;
BA_ "GenSigTimeoutTime_PBWM" SG_ 1838 HVBatCellVoltage_Cell093 0;
BA_ "GenSigTimeoutTime_IDCM" SG_ 1838 HVBatCellVoltage_Cell093 0;
BA_ "GenSigTimeoutTime_EVCU2" SG_ 1838 HVBatCellVoltage_Cell093 0;
BA_ "GenSigTimeoutTime_ECM" SG_ 1838 HVBatCellVoltage_Cell093 0;
BA_ "GenSigTimeoutTime_DMPI" SG_ 1838 HVBatCellVoltage_Cell093 0;
BA_ "GenSigTimeoutTime_BPCM" SG_ 1838 HVBatCellVoltage_Cell093 0;
BA_ "GenSigTimeoutTime_AGSM" SG_ 1838 HVBatCellVoltage_Cell093 0;
BA_ "GenSigTimeoutTime_PBWM" SG_ 1837 HVBatCellVoltage_Cell070 0;
BA_ "GenSigTimeoutTime_PBWM" SG_ 1837 HVBatCellVoltage_Cell071 0;
BA_ "GenSigTimeoutTime_IDCM" SG_ 1837 HVBatCellVoltage_Cell071 0;
BA_ "GenSigTimeoutTime_EVCU2" SG_ 1837 HVBatCellVoltage_Cell071 0;
BA_ "GenSigTimeoutTime_ECM" SG_ 1837 HVBatCellVoltage_Cell071 0;
BA_ "GenSigTimeoutTime_DMPI" SG_ 1837 HVBatCellVoltage_Cell071 0;
BA_ "GenSigTimeoutTime_BPCM" SG_ 1837 HVBatCellVoltage_Cell071 0;
BA_ "GenSigTimeoutTime_AGSM" SG_ 1837 HVBatCellVoltage_Cell071 0;
BA_ "GenSigTimeoutTime_PBWM" SG_ 1837 HVBatCellVoltage_Cell072 0;
BA_ "GenSigTimeoutTime_IDCM" SG_ 1837 HVBatCellVoltage_Cell072 0;
BA_ "GenSigTimeoutTime_EVCU2" SG_ 1837 HVBatCellVoltage_Cell072 0;
BA_ "GenSigTimeoutTime_ECM" SG_ 1837 HVBatCellVoltage_Cell072 0;
BA_ "GenSigTimeoutTime_DMPI" SG_ 1837 HVBatCellVoltage_Cell072 0;
BA_ "GenSigTimeoutTime_BPCM" SG_ 1837 HVBatCellVoltage_Cell072 0;
BA_ "GenSigTimeoutTime_AGSM" SG_ 1837 HVBatCellVoltage_Cell072 0;
BA_ "GenSigTimeoutTime_PBWM" SG_ 1837 HVBatCellVoltage_Cell073 0;
BA_ "GenSigTimeoutTime_IDCM" SG_ 1837 HVBatCellVoltage_Cell073 0;
BA_ "GenSigTimeoutTime_EVCU2" SG_ 1837 HVBatCellVoltage_Cell073 0;
BA_ "GenSigTimeoutTime_ECM" SG_ 1837 HVBatCellVoltage_Cell073 0;
BA_ "GenSigTimeoutTime_DMPI" SG_ 1837 HVBatCellVoltage_Cell073 0;
BA_ "GenSigTimeoutTime_BPCM" SG_ 1837 HVBatCellVoltage_Cell073 0;
BA_ "GenSigTimeoutTime_AGSM" SG_ 1837 HVBatCellVoltage_Cell073 0;
BA_ "GenSigTimeoutTime_IDCM" SG_ 1837 HVBatCellVoltage_Cell074 0;
BA_ "GenSigTimeoutTime_EVCU2" SG_ 1837 HVBatCellVoltage_Cell074 0;
BA_ "GenSigTimeoutTime_ECM" SG_ 1837 HVBatCellVoltage_Cell074 0;
BA_ "GenSigTimeoutTime_DMPI" SG_ 1837 HVBatCellVoltage_Cell074 0;
BA_ "GenSigTimeoutTime_BPCM" SG_ 1837 HVBatCellVoltage_Cell074 0;
BA_ "GenSigTimeoutTime_AGSM" SG_ 1837 HVBatCellVoltage_Cell074 0;
BA_ "GenSigTimeoutTime_PBWM" SG_ 1837 HVBatCellVoltage_Cell074 0;
BA_ "GenSigTimeoutTime_PBWM" SG_ 1837 HVBatCellVoltage_Cell075 0;
BA_ "GenSigTimeoutTime_IDCM" SG_ 1837 HVBatCellVoltage_Cell075 0;
BA_ "GenSigTimeoutTime_EVCU2" SG_ 1837 HVBatCellVoltage_Cell075 0;
BA_ "GenSigTimeoutTime_ECM" SG_ 1837 HVBatCellVoltage_Cell075 0;
BA_ "GenSigTimeoutTime_DMPI" SG_ 1837 HVBatCellVoltage_Cell075 0;
BA_ "GenSigTimeoutTime_BPCM" SG_ 1837 HVBatCellVoltage_Cell075 0;
BA_ "GenSigTimeoutTime_AGSM" SG_ 1837 HVBatCellVoltage_Cell075 0;
BA_ "GenSigTimeoutTime_PBWM" SG_ 1837 HVBatCellVoltage_Cell076 0;
BA_ "GenSigTimeoutTime_IDCM" SG_ 1837 HVBatCellVoltage_Cell076 0;
BA_ "GenSigTimeoutTime_EVCU2" SG_ 1837 HVBatCellVoltage_Cell076 0;
BA_ "GenSigTimeoutTime_ECM" SG_ 1837 HVBatCellVoltage_Cell076 0;
BA_ "GenSigTimeoutTime_DMPI" SG_ 1837 HVBatCellVoltage_Cell076 0;
BA_ "GenSigTimeoutTime_BPCM" SG_ 1837 HVBatCellVoltage_Cell076 0;
BA_ "GenSigTimeoutTime_AGSM" SG_ 1837 HVBatCellVoltage_Cell076 0;
BA_ "GenSigTimeoutTime_PBWM" SG_ 1837 HVBatCellVoltage_Cell077 0;
BA_ "GenSigTimeoutTime_IDCM" SG_ 1837 HVBatCellVoltage_Cell077 0;
BA_ "GenSigTimeoutTime_EVCU2" SG_ 1837 HVBatCellVoltage_Cell077 0;
BA_ "GenSigTimeoutTime_ECM" SG_ 1837 HVBatCellVoltage_Cell077 0;
BA_ "GenSigTimeoutTime_DMPI" SG_ 1837 HVBatCellVoltage_Cell077 0;
BA_ "GenSigTimeoutTime_BPCM" SG_ 1837 HVBatCellVoltage_Cell077 0;
BA_ "GenSigTimeoutTime_AGSM" SG_ 1837 HVBatCellVoltage_Cell077 0;
BA_ "GenSigTimeoutTime_PBWM" SG_ 1837 HVBatCellVoltage_Cell078 0;
BA_ "GenSigTimeoutTime_IDCM" SG_ 1837 HVBatCellVoltage_Cell078 0;
BA_ "GenSigTimeoutTime_EVCU2" SG_ 1837 HVBatCellVoltage_Cell078 0;
BA_ "GenSigTimeoutTime_ECM" SG_ 1837 HVBatCellVoltage_Cell078 0;
BA_ "GenSigTimeoutTime_DMPI" SG_ 1837 HVBatCellVoltage_Cell078 0;
BA_ "GenSigTimeoutTime_BPCM" SG_ 1837 HVBatCellVoltage_Cell078 0;
BA_ "GenSigTimeoutTime_AGSM" SG_ 1837 HVBatCellVoltage_Cell078 0;
BA_ "GenSigTimeoutTime_PBWM" SG_ 1837 HVBatCellVoltage_Cell079 0;
BA_ "GenSigTimeoutTime_IDCM" SG_ 1837 HVBatCellVoltage_Cell079 0;
BA_ "GenSigTimeoutTime_EVCU2" SG_ 1837 HVBatCellVoltage_Cell079 0;
BA_ "GenSigTimeoutTime_ECM" SG_ 1837 HVBatCellVoltage_Cell079 0;
BA_ "GenSigTimeoutTime_DMPI" SG_ 1837 HVBatCellVoltage_Cell079 0;
BA_ "GenSigTimeoutTime_BPCM" SG_ 1837 HVBatCellVoltage_Cell079 0;
BA_ "GenSigTimeoutTime_AGSM" SG_ 1837 HVBatCellVoltage_Cell079 0;
BA_ "GenSigTimeoutTime_PBWM" SG_ 1837 HVBatCellVoltage_Cell080 0;
BA_ "GenSigTimeoutTime_IDCM" SG_ 1837 HVBatCellVoltage_Cell080 0;
BA_ "GenSigTimeoutTime_EVCU2" SG_ 1837 HVBatCellVoltage_Cell080 0;
BA_ "GenSigTimeoutTime_ECM" SG_ 1837 HVBatCellVoltage_Cell080 0;
BA_ "GenSigTimeoutTime_DMPI" SG_ 1837 HVBatCellVoltage_Cell080 0;
BA_ "GenSigTimeoutTime_BPCM" SG_ 1837 HVBatCellVoltage_Cell080 0;
BA_ "GenSigTimeoutTime_AGSM" SG_ 1837 HVBatCellVoltage_Cell080 0;
BA_ "GenSigTimeoutTime_PBWM" SG_ 1837 HVBatCellVoltage_Cell081 0;
BA_ "GenSigTimeoutTime_IDCM" SG_ 1837 HVBatCellVoltage_Cell081 0;
BA_ "GenSigTimeoutTime_EVCU2" SG_ 1837 HVBatCellVoltage_Cell081 0;
BA_ "GenSigTimeoutTime_ECM" SG_ 1837 HVBatCellVoltage_Cell081 0;
BA_ "GenSigTimeoutTime_DMPI" SG_ 1837 HVBatCellVoltage_Cell081 0;
BA_ "GenSigTimeoutTime_BPCM" SG_ 1837 HVBatCellVoltage_Cell081 0;
BA_ "GenSigTimeoutTime_AGSM" SG_ 1837 HVBatCellVoltage_Cell081 0;
BA_ "GenSigTimeoutTime_PBWM" SG_ 1838 HVBatCellVoltage_Cell082 0;
BA_ "GenSigTimeoutTime_IDCM" SG_ 1838 HVBatCellVoltage_Cell082 0;
BA_ "GenSigTimeoutTime_EVCU2" SG_ 1838 HVBatCellVoltage_Cell082 0;
BA_ "GenSigTimeoutTime_ECM" SG_ 1838 HVBatCellVoltage_Cell082 0;
BA_ "GenSigTimeoutTime_DMPI" SG_ 1838 HVBatCellVoltage_Cell082 0;
BA_ "GenSigTimeoutTime_BPCM" SG_ 1838 HVBatCellVoltage_Cell082 0;
BA_ "GenSigTimeoutTime_AGSM" SG_ 1838 HVBatCellVoltage_Cell082 0;
BA_ "GenSigTimeoutTime_PBWM" SG_ 1838 HVBatCellVoltage_Cell083 0;
BA_ "GenSigTimeoutTime_IDCM" SG_ 1838 HVBatCellVoltage_Cell083 0;
BA_ "GenSigTimeoutTime_EVCU2" SG_ 1838 HVBatCellVoltage_Cell083 0;
BA_ "GenSigTimeoutTime_ECM" SG_ 1838 HVBatCellVoltage_Cell083 0;
BA_ "GenSigTimeoutTime_DMPI" SG_ 1838 HVBatCellVoltage_Cell083 0;
BA_ "GenSigTimeoutTime_BPCM" SG_ 1838 HVBatCellVoltage_Cell083 0;
BA_ "GenSigTimeoutTime_AGSM" SG_ 1838 HVBatCellVoltage_Cell083 0;
BA_ "GenSigTimeoutTime_PBWM" SG_ 1838 HVBatCellVoltage_Cell084 0;
BA_ "GenSigTimeoutTime_IDCM" SG_ 1838 HVBatCellVoltage_Cell084 0;
BA_ "GenSigTimeoutTime_EVCU2" SG_ 1838 HVBatCellVoltage_Cell084 0;
BA_ "GenSigTimeoutTime_ECM" SG_ 1838 HVBatCellVoltage_Cell084 0;
BA_ "GenSigTimeoutTime_DMPI" SG_ 1838 HVBatCellVoltage_Cell084 0;
BA_ "GenSigTimeoutTime_BPCM" SG_ 1838 HVBatCellVoltage_Cell084 0;
BA_ "GenSigTimeoutTime_AGSM" SG_ 1838 HVBatCellVoltage_Cell084 0;
BA_ "GenSigTimeoutTime_PBWM" SG_ 1838 HVBatCellVoltage_Cell085 0;
BA_ "GenSigTimeoutTime_IDCM" SG_ 1838 HVBatCellVoltage_Cell085 0;
BA_ "GenSigTimeoutTime_EVCU2" SG_ 1838 HVBatCellVoltage_Cell085 0;
BA_ "GenSigTimeoutTime_ECM" SG_ 1838 HVBatCellVoltage_Cell085 0;
BA_ "GenSigTimeoutTime_DMPI" SG_ 1838 HVBatCellVoltage_Cell085 0;
BA_ "GenSigTimeoutTime_BPCM" SG_ 1838 HVBatCellVoltage_Cell085 0;
BA_ "GenSigTimeoutTime_AGSM" SG_ 1838 HVBatCellVoltage_Cell085 0;
BA_ "GenSigTimeoutTime_PBWM" SG_ 1838 HVBatCellVoltage_Cell086 0;
BA_ "GenSigTimeoutTime_IDCM" SG_ 1838 HVBatCellVoltage_Cell086 0;
BA_ "GenSigTimeoutTime_EVCU2" SG_ 1838 HVBatCellVoltage_Cell086 0;
BA_ "GenSigTimeoutTime_ECM" SG_ 1838 HVBatCellVoltage_Cell086 0;
BA_ "GenSigTimeoutTime_DMPI" SG_ 1838 HVBatCellVoltage_Cell086 0;
BA_ "GenSigTimeoutTime_BPCM" SG_ 1838 HVBatCellVoltage_Cell086 0;
BA_ "GenSigTimeoutTime_AGSM" SG_ 1838 HVBatCellVoltage_Cell086 0;
BA_ "GenSigTimeoutTime_PBWM" SG_ 1838 HVBatCellVoltage_Cell087 0;
BA_ "GenSigTimeoutTime_IDCM" SG_ 1838 HVBatCellVoltage_Cell087 0;
BA_ "GenSigTimeoutTime_EVCU2" SG_ 1838 HVBatCellVoltage_Cell087 0;
BA_ "GenSigTimeoutTime_ECM" SG_ 1838 HVBatCellVoltage_Cell087 0;
BA_ "GenSigTimeoutTime_DMPI" SG_ 1838 HVBatCellVoltage_Cell087 0;
BA_ "GenSigTimeoutTime_BPCM" SG_ 1838 HVBatCellVoltage_Cell087 0;
BA_ "GenSigTimeoutTime_AGSM" SG_ 1838 HVBatCellVoltage_Cell087 0;
BA_ "GenSigTimeoutTime_PBWM" SG_ 1838 HVBatCellVoltage_Cell088 0;
BA_ "GenSigTimeoutTime_IDCM" SG_ 1838 HVBatCellVoltage_Cell088 0;
BA_ "GenSigTimeoutTime_EVCU2" SG_ 1838 HVBatCellVoltage_Cell088 0;
BA_ "GenSigTimeoutTime_ECM" SG_ 1838 HVBatCellVoltage_Cell088 0;
BA_ "GenSigTimeoutTime_DMPI" SG_ 1838 HVBatCellVoltage_Cell088 0;
BA_ "GenSigTimeoutTime_BPCM" SG_ 1838 HVBatCellVoltage_Cell088 0;
BA_ "GenSigTimeoutTime_AGSM" SG_ 1838 HVBatCellVoltage_Cell088 0;
BA_ "GenSigTimeoutTime_PBWM" SG_ 1838 HVBatCellVoltage_Cell089 0;
BA_ "GenSigTimeoutTime_IDCM" SG_ 1838 HVBatCellVoltage_Cell089 0;
BA_ "GenSigTimeoutTime_EVCU2" SG_ 1838 HVBatCellVoltage_Cell089 0;
BA_ "GenSigTimeoutTime_ECM" SG_ 1838 HVBatCellVoltage_Cell089 0;
BA_ "GenSigTimeoutTime_DMPI" SG_ 1838 HVBatCellVoltage_Cell089 0;
BA_ "GenSigTimeoutTime_BPCM" SG_ 1838 HVBatCellVoltage_Cell089 0;
BA_ "GenSigTimeoutTime_AGSM" SG_ 1838 HVBatCellVoltage_Cell089 0;
BA_ "GenSigTimeoutTime_PBWM" SG_ 1835 HVBatCellVoltage_Cell001 0;
BA_ "GenSigTimeoutTime_IDCM" SG_ 1835 HVBatCellVoltage_Cell001 0;
BA_ "GenSigTimeoutTime_EVCU2" SG_ 1835 HVBatCellVoltage_Cell001 0;
BA_ "GenSigTimeoutTime_ECM" SG_ 1835 HVBatCellVoltage_Cell001 0;
BA_ "GenSigTimeoutTime_DMPI" SG_ 1835 HVBatCellVoltage_Cell001 0;
BA_ "GenSigTimeoutTime_BPCM" SG_ 1835 HVBatCellVoltage_Cell001 0;
BA_ "GenSigTimeoutTime_AGSM" SG_ 1835 HVBatCellVoltage_Cell001 0;
BA_ "GenSigTimeoutTime_SGW" SG_ 1328 CatTempMaint 0;
BA_ "GenSigTimeoutTime_PBWM" SG_ 1328 CatTempMaint 0;
BA_ "GenSigTimeoutTime_IDCM" SG_ 1328 CatTempMaint 0;
BA_ "GenSigTimeoutTime_ECM" SG_ 1328 CatTempMaint 0;
BA_ "GenSigTimeoutTime_DMPI" SG_ 1328 CatTempMaint 0;
BA_ "GenSigTimeoutTime_BPCM" SG_ 1328 CatTempMaint 0;
BA_ "GenSigTimeoutTime_AGSM" SG_ 1328 CatTempMaint 0;
BA_ "GenSigTimeoutTime_SGW" SG_ 1328 EngTorqCapbltyRefEngSpd 0;
BA_ "GenSigTimeoutTime_PBWM" SG_ 1328 EngTorqCapbltyRefEngSpd 0;
BA_ "GenSigTimeoutTime_IDCM" SG_ 1328 EngTorqCapbltyRefEngSpd 0;
BA_ "GenSigTimeoutTime_ECM" SG_ 1328 EngTorqCapbltyRefEngSpd 0;
BA_ "GenSigTimeoutTime_DMPI" SG_ 1328 EngTorqCapbltyRefEngSpd 0;
BA_ "GenSigTimeoutTime_BPCM" SG_ 1328 EngTorqCapbltyRefEngSpd 0;
BA_ "GenSigTimeoutTime_AGSM" SG_ 1328 EngTorqCapbltyRefEngSpd 0;
BA_ "GenSigTimeoutTime_SGW" SG_ 1328 EngTorqCapbltyFrmCntr 0;
BA_ "GenSigTimeoutTime_PBWM" SG_ 1328 EngTorqCapbltyFrmCntr 0;
BA_ "GenSigTimeoutTime_IDCM" SG_ 1328 EngTorqCapbltyFrmCntr 0;
BA_ "GenSigTimeoutTime_ECM" SG_ 1328 EngTorqCapbltyFrmCntr 0;
BA_ "GenSigTimeoutTime_DMPI" SG_ 1328 EngTorqCapbltyFrmCntr 0;
BA_ "GenSigTimeoutTime_BPCM" SG_ 1328 EngTorqCapbltyFrmCntr 0;
BA_ "GenSigTimeoutTime_AGSM" SG_ 1328 EngTorqCapbltyFrmCntr 0;
BA_ "GenSigTimeoutTime_SGW" SG_ 1328 EngTorqCapbltyMinRunTorq 0;
BA_ "GenSigTimeoutTime_PBWM" SG_ 1328 EngTorqCapbltyMinRunTorq 0;
BA_ "GenSigTimeoutTime_IDCM" SG_ 1328 EngTorqCapbltyMinRunTorq 0;
BA_ "GenSigTimeoutTime_ECM" SG_ 1328 EngTorqCapbltyMinRunTorq 0;
BA_ "GenSigTimeoutTime_DMPI" SG_ 1328 EngTorqCapbltyMinRunTorq 0;
BA_ "GenSigTimeoutTime_BPCM" SG_ 1328 EngTorqCapbltyMinRunTorq 0;
BA_ "GenSigTimeoutTime_AGSM" SG_ 1328 EngTorqCapbltyMinRunTorq 0;
BA_ "GenSigStartValue" SG_ 1328 EngTorqCapbltyMinRunTorq 938;
BA_ "GenSigTimeoutTime_SGW" SG_ 1328 CatHtgStateActive 0;
BA_ "GenSigTimeoutTime_PBWM" SG_ 1328 CatHtgStateActive 0;
BA_ "GenSigTimeoutTime_IDCM" SG_ 1328 CatHtgStateActive 0;
BA_ "GenSigTimeoutTime_ECM" SG_ 1328 CatHtgStateActive 0;
BA_ "GenSigTimeoutTime_DMPI" SG_ 1328 CatHtgStateActive 0;
BA_ "GenSigTimeoutTime_BPCM" SG_ 1328 CatHtgStateActive 0;
BA_ "GenSigTimeoutTime_AGSM" SG_ 1328 CatHtgStateActive 0;
BA_ "GenSigTimeoutTime_SGW" SG_ 1328 EngTorqACCCapability 0;
BA_ "GenSigTimeoutTime_PBWM" SG_ 1328 EngTorqACCCapability 0;
BA_ "GenSigTimeoutTime_IDCM" SG_ 1328 EngTorqACCCapability 0;
BA_ "GenSigTimeoutTime_ECM" SG_ 1328 EngTorqACCCapability 0;
BA_ "GenSigTimeoutTime_DMPI" SG_ 1328 EngTorqACCCapability 0;
BA_ "GenSigTimeoutTime_BPCM" SG_ 1328 EngTorqACCCapability 0;
BA_ "GenSigTimeoutTime_AGSM" SG_ 1328 EngTorqACCCapability 0;
BA_ "GenSigTimeoutTime_SGW" SG_ 1328 CRC_ENGINE_HYBD_FD_4 0;
BA_ "GenSigTimeoutTime_PBWM" SG_ 1328 CRC_ENGINE_HYBD_FD_4 0;
BA_ "GenSigTimeoutTime_IDCM" SG_ 1328 CRC_ENGINE_HYBD_FD_4 0;
BA_ "GenSigTimeoutTime_ECM" SG_ 1328 CRC_ENGINE_HYBD_FD_4 0;
BA_ "GenSigTimeoutTime_DMPI" SG_ 1328 CRC_ENGINE_HYBD_FD_4 0;
BA_ "GenSigTimeoutTime_BPCM" SG_ 1328 CRC_ENGINE_HYBD_FD_4 0;
BA_ "GenSigTimeoutTime_AGSM" SG_ 1328 CRC_ENGINE_HYBD_FD_4 0;
BA_ "GenSigTimeoutTime_SGW" SG_ 1328 MessageCounter_ENGINE_HYBD_FD_4 0;
BA_ "GenSigTimeoutTime_PBWM" SG_ 1328 MessageCounter_ENGINE_HYBD_FD_4 0;
BA_ "GenSigTimeoutTime_IDCM" SG_ 1328 MessageCounter_ENGINE_HYBD_FD_4 0;
BA_ "GenSigTimeoutTime_ECM" SG_ 1328 MessageCounter_ENGINE_HYBD_FD_4 0;
BA_ "GenSigTimeoutTime_DMPI" SG_ 1328 MessageCounter_ENGINE_HYBD_FD_4 0;
BA_ "GenSigTimeoutTime_BPCM" SG_ 1328 MessageCounter_ENGINE_HYBD_FD_4 0;
BA_ "GenSigTimeoutTime_AGSM" SG_ 1328 MessageCounter_ENGINE_HYBD_FD_4 0;
BA_ "GenSigTimeoutTime_SGW" SG_ 1328 EngTorqCapbltyMaxOffTorq 0;
BA_ "GenSigTimeoutTime_PBWM" SG_ 1328 EngTorqCapbltyMaxOffTorq 0;
BA_ "GenSigTimeoutTime_IDCM" SG_ 1328 EngTorqCapbltyMaxOffTorq 0;
BA_ "GenSigTimeoutTime_ECM" SG_ 1328 EngTorqCapbltyMaxOffTorq 0;
BA_ "GenSigTimeoutTime_DMPI" SG_ 1328 EngTorqCapbltyMaxOffTorq 0;
BA_ "GenSigTimeoutTime_BPCM" SG_ 1328 EngTorqCapbltyMaxOffTorq 0;
BA_ "GenSigTimeoutTime_AGSM" SG_ 1328 EngTorqCapbltyMaxOffTorq 0;
BA_ "GenSigTimeoutTime_SGW" SG_ 1328 EngTorqCapbltyMaxTorq 0;
BA_ "GenSigTimeoutTime_PBWM" SG_ 1328 EngTorqCapbltyMaxTorq 0;
BA_ "GenSigTimeoutTime_IDCM" SG_ 1328 EngTorqCapbltyMaxTorq 0;
BA_ "GenSigTimeoutTime_ECM" SG_ 1328 EngTorqCapbltyMaxTorq 0;
BA_ "GenSigTimeoutTime_DMPI" SG_ 1328 EngTorqCapbltyMaxTorq 0;
BA_ "GenSigTimeoutTime_BPCM" SG_ 1328 EngTorqCapbltyMaxTorq 0;
BA_ "GenSigTimeoutTime_AGSM" SG_ 1328 EngTorqCapbltyMaxTorq 0;
BA_ "GenSigStartValue" SG_ 1328 EngTorqCapbltyMaxTorq 938;
BA_ "GenSigTimeoutTime_SGW" SG_ 1328 EngTorqCapbltyMinTorq 0;
BA_ "GenSigTimeoutTime_PBWM" SG_ 1328 EngTorqCapbltyMinTorq 0;
BA_ "GenSigTimeoutTime_IDCM" SG_ 1328 EngTorqCapbltyMinTorq 0;
BA_ "GenSigTimeoutTime_ECM" SG_ 1328 EngTorqCapbltyMinTorq 0;
BA_ "GenSigTimeoutTime_DMPI" SG_ 1328 EngTorqCapbltyMinTorq 0;
BA_ "GenSigTimeoutTime_BPCM" SG_ 1328 EngTorqCapbltyMinTorq 0;
BA_ "GenSigTimeoutTime_AGSM" SG_ 1328 EngTorqCapbltyMinTorq 0;
BA_ "GenSigStartValue" SG_ 1328 EngTorqCapbltyMinTorq 938;
BA_ "GenSigTimeoutTime_IDCM" SG_ 1837 HVBatCellVoltage_Cell070 0;
BA_ "GenSigTimeoutTime_EVCU2" SG_ 1837 HVBatCellVoltage_Cell070 0;
BA_ "GenSigTimeoutTime_ECM" SG_ 1837 HVBatCellVoltage_Cell070 0;
BA_ "GenSigTimeoutTime_DMPI" SG_ 1837 HVBatCellVoltage_Cell070 0;
BA_ "GenSigTimeoutTime_BPCM" SG_ 1837 HVBatCellVoltage_Cell070 0;
BA_ "GenSigTimeoutTime_AGSM" SG_ 1837 HVBatCellVoltage_Cell070 0;
BA_ "GenSigTimeoutTime_PBWM" SG_ 1837 HVBatCellVoltage_Cell066 0;
BA_ "GenSigTimeoutTime_IDCM" SG_ 1837 HVBatCellVoltage_Cell066 0;
BA_ "GenSigTimeoutTime_EVCU2" SG_ 1837 HVBatCellVoltage_Cell066 0;
BA_ "GenSigTimeoutTime_ECM" SG_ 1837 HVBatCellVoltage_Cell066 0;
BA_ "GenSigTimeoutTime_DMPI" SG_ 1837 HVBatCellVoltage_Cell066 0;
BA_ "GenSigTimeoutTime_BPCM" SG_ 1837 HVBatCellVoltage_Cell066 0;
BA_ "GenSigTimeoutTime_AGSM" SG_ 1837 HVBatCellVoltage_Cell066 0;
BA_ "GenSigTimeoutTime_PBWM" SG_ 1837 HVBatCellVoltage_Cell067 0;
BA_ "GenSigTimeoutTime_IDCM" SG_ 1837 HVBatCellVoltage_Cell067 0;
BA_ "GenSigTimeoutTime_EVCU2" SG_ 1837 HVBatCellVoltage_Cell067 0;
BA_ "GenSigTimeoutTime_ECM" SG_ 1837 HVBatCellVoltage_Cell067 0;
BA_ "GenSigTimeoutTime_DMPI" SG_ 1837 HVBatCellVoltage_Cell067 0;
BA_ "GenSigTimeoutTime_BPCM" SG_ 1837 HVBatCellVoltage_Cell067 0;
BA_ "GenSigTimeoutTime_AGSM" SG_ 1837 HVBatCellVoltage_Cell067 0;
BA_ "GenSigTimeoutTime_PBWM" SG_ 1837 HVBatCellVoltage_Cell068 0;
BA_ "GenSigTimeoutTime_IDCM" SG_ 1837 HVBatCellVoltage_Cell068 0;
BA_ "GenSigTimeoutTime_EVCU2" SG_ 1837 HVBatCellVoltage_Cell068 0;
BA_ "GenSigTimeoutTime_ECM" SG_ 1837 HVBatCellVoltage_Cell068 0;
BA_ "GenSigTimeoutTime_DMPI" SG_ 1837 HVBatCellVoltage_Cell068 0;
BA_ "GenSigTimeoutTime_BPCM" SG_ 1837 HVBatCellVoltage_Cell068 0;
BA_ "GenSigTimeoutTime_AGSM" SG_ 1837 HVBatCellVoltage_Cell068 0;
BA_ "GenSigTimeoutTime_PBWM" SG_ 1837 HVBatCellVoltage_Cell069 0;
BA_ "GenSigTimeoutTime_IDCM" SG_ 1837 HVBatCellVoltage_Cell069 0;
BA_ "GenSigTimeoutTime_EVCU2" SG_ 1837 HVBatCellVoltage_Cell069 0;
BA_ "GenSigTimeoutTime_ECM" SG_ 1837 HVBatCellVoltage_Cell069 0;
BA_ "GenSigTimeoutTime_DMPI" SG_ 1837 HVBatCellVoltage_Cell069 0;
BA_ "GenSigTimeoutTime_BPCM" SG_ 1837 HVBatCellVoltage_Cell069 0;
BA_ "GenSigTimeoutTime_AGSM" SG_ 1837 HVBatCellVoltage_Cell069 0;
BA_ "GenSigTimeoutTime_PBWM" SG_ 1837 HVBatCellVoltage_Cell058 0;
BA_ "GenSigTimeoutTime_IDCM" SG_ 1837 HVBatCellVoltage_Cell058 0;
BA_ "GenSigTimeoutTime_EVCU2" SG_ 1837 HVBatCellVoltage_Cell058 0;
BA_ "GenSigTimeoutTime_ECM" SG_ 1837 HVBatCellVoltage_Cell058 0;
BA_ "GenSigTimeoutTime_DMPI" SG_ 1837 HVBatCellVoltage_Cell058 0;
BA_ "GenSigTimeoutTime_BPCM" SG_ 1837 HVBatCellVoltage_Cell058 0;
BA_ "GenSigTimeoutTime_AGSM" SG_ 1837 HVBatCellVoltage_Cell058 0;
BA_ "GenSigTimeoutTime_PBWM" SG_ 1837 HVBatCellVoltage_Cell059 0;
BA_ "GenSigTimeoutTime_IDCM" SG_ 1837 HVBatCellVoltage_Cell059 0;
BA_ "GenSigTimeoutTime_EVCU2" SG_ 1837 HVBatCellVoltage_Cell059 0;
BA_ "GenSigTimeoutTime_ECM" SG_ 1837 HVBatCellVoltage_Cell059 0;
BA_ "GenSigTimeoutTime_DMPI" SG_ 1837 HVBatCellVoltage_Cell059 0;
BA_ "GenSigTimeoutTime_BPCM" SG_ 1837 HVBatCellVoltage_Cell059 0;
BA_ "GenSigTimeoutTime_AGSM" SG_ 1837 HVBatCellVoltage_Cell059 0;
BA_ "GenSigTimeoutTime_PBWM" SG_ 1837 HVBatCellVoltage_Cell060 0;
BA_ "GenSigTimeoutTime_IDCM" SG_ 1837 HVBatCellVoltage_Cell060 0;
BA_ "GenSigTimeoutTime_EVCU2" SG_ 1837 HVBatCellVoltage_Cell060 0;
BA_ "GenSigTimeoutTime_ECM" SG_ 1837 HVBatCellVoltage_Cell060 0;
BA_ "GenSigTimeoutTime_DMPI" SG_ 1837 HVBatCellVoltage_Cell060 0;
BA_ "GenSigTimeoutTime_BPCM" SG_ 1837 HVBatCellVoltage_Cell060 0;
BA_ "GenSigTimeoutTime_AGSM" SG_ 1837 HVBatCellVoltage_Cell060 0;
BA_ "GenSigTimeoutTime_PBWM" SG_ 1837 HVBatCellVoltage_Cell061 0;
BA_ "GenSigTimeoutTime_IDCM" SG_ 1837 HVBatCellVoltage_Cell061 0;
BA_ "GenSigTimeoutTime_EVCU2" SG_ 1837 HVBatCellVoltage_Cell061 0;
BA_ "GenSigTimeoutTime_ECM" SG_ 1837 HVBatCellVoltage_Cell061 0;
BA_ "GenSigTimeoutTime_DMPI" SG_ 1837 HVBatCellVoltage_Cell061 0;
BA_ "GenSigTimeoutTime_BPCM" SG_ 1837 HVBatCellVoltage_Cell061 0;
BA_ "GenSigTimeoutTime_AGSM" SG_ 1837 HVBatCellVoltage_Cell061 0;
BA_ "GenSigTimeoutTime_PBWM" SG_ 1837 HVBatCellVoltage_Cell062 0;
BA_ "GenSigTimeoutTime_IDCM" SG_ 1837 HVBatCellVoltage_Cell062 0;
BA_ "GenSigTimeoutTime_EVCU2" SG_ 1837 HVBatCellVoltage_Cell062 0;
BA_ "GenSigTimeoutTime_ECM" SG_ 1837 HVBatCellVoltage_Cell062 0;
BA_ "GenSigTimeoutTime_DMPI" SG_ 1837 HVBatCellVoltage_Cell062 0;
BA_ "GenSigTimeoutTime_BPCM" SG_ 1837 HVBatCellVoltage_Cell062 0;
BA_ "GenSigTimeoutTime_AGSM" SG_ 1837 HVBatCellVoltage_Cell062 0;
BA_ "GenSigTimeoutTime_PBWM" SG_ 1837 HVBatCellVoltage_Cell063 0;
BA_ "GenSigTimeoutTime_IDCM" SG_ 1837 HVBatCellVoltage_Cell063 0;
BA_ "GenSigTimeoutTime_EVCU2" SG_ 1837 HVBatCellVoltage_Cell063 0;
BA_ "GenSigTimeoutTime_ECM" SG_ 1837 HVBatCellVoltage_Cell063 0;
BA_ "GenSigTimeoutTime_DMPI" SG_ 1837 HVBatCellVoltage_Cell063 0;
BA_ "GenSigTimeoutTime_BPCM" SG_ 1837 HVBatCellVoltage_Cell063 0;
BA_ "GenSigTimeoutTime_AGSM" SG_ 1837 HVBatCellVoltage_Cell063 0;
BA_ "GenSigTimeoutTime_PBWM" SG_ 1837 HVBatCellVoltage_Cell064 0;
BA_ "GenSigTimeoutTime_IDCM" SG_ 1837 HVBatCellVoltage_Cell064 0;
BA_ "GenSigTimeoutTime_EVCU2" SG_ 1837 HVBatCellVoltage_Cell064 0;
BA_ "GenSigTimeoutTime_ECM" SG_ 1837 HVBatCellVoltage_Cell064 0;
BA_ "GenSigTimeoutTime_DMPI" SG_ 1837 HVBatCellVoltage_Cell064 0;
BA_ "GenSigTimeoutTime_BPCM" SG_ 1837 HVBatCellVoltage_Cell064 0;
BA_ "GenSigTimeoutTime_AGSM" SG_ 1837 HVBatCellVoltage_Cell064 0;
BA_ "GenSigTimeoutTime_PBWM" SG_ 1837 HVBatCellVoltage_Cell065 0;
BA_ "GenSigTimeoutTime_IDCM" SG_ 1837 HVBatCellVoltage_Cell065 0;
BA_ "GenSigTimeoutTime_EVCU2" SG_ 1837 HVBatCellVoltage_Cell065 0;
BA_ "GenSigTimeoutTime_ECM" SG_ 1837 HVBatCellVoltage_Cell065 0;
BA_ "GenSigTimeoutTime_DMPI" SG_ 1837 HVBatCellVoltage_Cell065 0;
BA_ "GenSigTimeoutTime_BPCM" SG_ 1837 HVBatCellVoltage_Cell065 0;
BA_ "GenSigTimeoutTime_AGSM" SG_ 1837 HVBatCellVoltage_Cell065 0;
BA_ "GenSigTimeoutTime_PBWM" SG_ 1836 HVBatCellVoltage_Cell041 0;
BA_ "GenSigTimeoutTime_IDCM" SG_ 1836 HVBatCellVoltage_Cell041 0;
BA_ "GenSigTimeoutTime_EVCU2" SG_ 1836 HVBatCellVoltage_Cell041 0;
BA_ "GenSigTimeoutTime_ECM" SG_ 1836 HVBatCellVoltage_Cell041 0;
BA_ "GenSigTimeoutTime_DMPI" SG_ 1836 HVBatCellVoltage_Cell041 0;
BA_ "GenSigTimeoutTime_BPCM" SG_ 1836 HVBatCellVoltage_Cell041 0;
BA_ "GenSigTimeoutTime_AGSM" SG_ 1836 HVBatCellVoltage_Cell041 0;
BA_ "GenSigTimeoutTime_PBWM" SG_ 1836 HVBatCellVoltage_Cell042 0;
BA_ "GenSigTimeoutTime_IDCM" SG_ 1836 HVBatCellVoltage_Cell042 0;
BA_ "GenSigTimeoutTime_EVCU2" SG_ 1836 HVBatCellVoltage_Cell042 0;
BA_ "GenSigTimeoutTime_ECM" SG_ 1836 HVBatCellVoltage_Cell042 0;
BA_ "GenSigTimeoutTime_DMPI" SG_ 1836 HVBatCellVoltage_Cell042 0;
BA_ "GenSigTimeoutTime_BPCM" SG_ 1836 HVBatCellVoltage_Cell042 0;
BA_ "GenSigTimeoutTime_AGSM" SG_ 1836 HVBatCellVoltage_Cell042 0;
BA_ "GenSigTimeoutTime_PBWM" SG_ 1836 HVBatCellVoltage_Cell043 0;
BA_ "GenSigTimeoutTime_IDCM" SG_ 1836 HVBatCellVoltage_Cell043 0;
BA_ "GenSigTimeoutTime_EVCU2" SG_ 1836 HVBatCellVoltage_Cell043 0;
BA_ "GenSigTimeoutTime_ECM" SG_ 1836 HVBatCellVoltage_Cell043 0;
BA_ "GenSigTimeoutTime_DMPI" SG_ 1836 HVBatCellVoltage_Cell043 0;
BA_ "GenSigTimeoutTime_BPCM" SG_ 1836 HVBatCellVoltage_Cell043 0;
BA_ "GenSigTimeoutTime_AGSM" SG_ 1836 HVBatCellVoltage_Cell043 0;
BA_ "GenSigTimeoutTime_PBWM" SG_ 1836 HVBatCellVoltage_Cell044 0;
BA_ "GenSigTimeoutTime_IDCM" SG_ 1836 HVBatCellVoltage_Cell044 0;
BA_ "GenSigTimeoutTime_EVCU2" SG_ 1836 HVBatCellVoltage_Cell044 0;
BA_ "GenSigTimeoutTime_ECM" SG_ 1836 HVBatCellVoltage_Cell044 0;
BA_ "GenSigTimeoutTime_DMPI" SG_ 1836 HVBatCellVoltage_Cell044 0;
BA_ "GenSigTimeoutTime_BPCM" SG_ 1836 HVBatCellVoltage_Cell044 0;
BA_ "GenSigTimeoutTime_AGSM" SG_ 1836 HVBatCellVoltage_Cell044 0;
BA_ "GenSigTimeoutTime_PBWM" SG_ 1836 HVBatCellVoltage_Cell045 0;
BA_ "GenSigTimeoutTime_IDCM" SG_ 1836 HVBatCellVoltage_Cell045 0;
BA_ "GenSigTimeoutTime_EVCU2" SG_ 1836 HVBatCellVoltage_Cell045 0;
BA_ "GenSigTimeoutTime_ECM" SG_ 1836 HVBatCellVoltage_Cell045 0;
BA_ "GenSigTimeoutTime_DMPI" SG_ 1836 HVBatCellVoltage_Cell045 0;
BA_ "GenSigTimeoutTime_BPCM" SG_ 1836 HVBatCellVoltage_Cell045 0;
BA_ "GenSigTimeoutTime_AGSM" SG_ 1836 HVBatCellVoltage_Cell045 0;
BA_ "GenSigTimeoutTime_PBWM" SG_ 1836 HVBatCellVoltage_Cell046 0;
BA_ "GenSigTimeoutTime_IDCM" SG_ 1836 HVBatCellVoltage_Cell046 0;
BA_ "GenSigTimeoutTime_EVCU2" SG_ 1836 HVBatCellVoltage_Cell046 0;
BA_ "GenSigTimeoutTime_ECM" SG_ 1836 HVBatCellVoltage_Cell046 0;
BA_ "GenSigTimeoutTime_DMPI" SG_ 1836 HVBatCellVoltage_Cell046 0;
BA_ "GenSigTimeoutTime_BPCM" SG_ 1836 HVBatCellVoltage_Cell046 0;
BA_ "GenSigTimeoutTime_AGSM" SG_ 1836 HVBatCellVoltage_Cell046 0;
BA_ "GenSigTimeoutTime_PBWM" SG_ 1836 HVBatCellVoltage_Cell047 0;
BA_ "GenSigTimeoutTime_IDCM" SG_ 1836 HVBatCellVoltage_Cell047 0;
BA_ "GenSigTimeoutTime_EVCU2" SG_ 1836 HVBatCellVoltage_Cell047 0;
BA_ "GenSigTimeoutTime_ECM" SG_ 1836 HVBatCellVoltage_Cell047 0;
BA_ "GenSigTimeoutTime_DMPI" SG_ 1836 HVBatCellVoltage_Cell047 0;
BA_ "GenSigTimeoutTime_BPCM" SG_ 1836 HVBatCellVoltage_Cell047 0;
BA_ "GenSigTimeoutTime_AGSM" SG_ 1836 HVBatCellVoltage_Cell047 0;
BA_ "GenSigTimeoutTime_PBWM" SG_ 1836 HVBatCellVoltage_Cell048 0;
BA_ "GenSigTimeoutTime_IDCM" SG_ 1836 HVBatCellVoltage_Cell048 0;
BA_ "GenSigTimeoutTime_EVCU2" SG_ 1836 HVBatCellVoltage_Cell048 0;
BA_ "GenSigTimeoutTime_ECM" SG_ 1836 HVBatCellVoltage_Cell048 0;
BA_ "GenSigTimeoutTime_DMPI" SG_ 1836 HVBatCellVoltage_Cell048 0;
BA_ "GenSigTimeoutTime_BPCM" SG_ 1836 HVBatCellVoltage_Cell048 0;
BA_ "GenSigTimeoutTime_AGSM" SG_ 1836 HVBatCellVoltage_Cell048 0;
BA_ "GenSigTimeoutTime_PBWM" SG_ 1836 HVBatCellVoltage_Cell049 0;
BA_ "GenSigTimeoutTime_IDCM" SG_ 1836 HVBatCellVoltage_Cell049 0;
BA_ "GenSigTimeoutTime_EVCU2" SG_ 1836 HVBatCellVoltage_Cell049 0;
BA_ "GenSigTimeoutTime_ECM" SG_ 1836 HVBatCellVoltage_Cell049 0;
BA_ "GenSigTimeoutTime_DMPI" SG_ 1836 HVBatCellVoltage_Cell049 0;
BA_ "GenSigTimeoutTime_BPCM" SG_ 1836 HVBatCellVoltage_Cell049 0;
BA_ "GenSigTimeoutTime_AGSM" SG_ 1836 HVBatCellVoltage_Cell049 0;
BA_ "GenSigTimeoutTime_PBWM" SG_ 1836 HVBatCellVoltage_Cell050 0;
BA_ "GenSigTimeoutTime_IDCM" SG_ 1836 HVBatCellVoltage_Cell050 0;
BA_ "GenSigTimeoutTime_EVCU2" SG_ 1836 HVBatCellVoltage_Cell050 0;
BA_ "GenSigTimeoutTime_ECM" SG_ 1836 HVBatCellVoltage_Cell050 0;
BA_ "GenSigTimeoutTime_DMPI" SG_ 1836 HVBatCellVoltage_Cell050 0;
BA_ "GenSigTimeoutTime_BPCM" SG_ 1836 HVBatCellVoltage_Cell050 0;
BA_ "GenSigTimeoutTime_AGSM" SG_ 1836 HVBatCellVoltage_Cell050 0;
BA_ "GenSigTimeoutTime_PBWM" SG_ 1836 HVBatCellVoltage_Cell051 0;
BA_ "GenSigTimeoutTime_IDCM" SG_ 1836 HVBatCellVoltage_Cell051 0;
BA_ "GenSigTimeoutTime_EVCU2" SG_ 1836 HVBatCellVoltage_Cell051 0;
BA_ "GenSigTimeoutTime_ECM" SG_ 1836 HVBatCellVoltage_Cell051 0;
BA_ "GenSigTimeoutTime_DMPI" SG_ 1836 HVBatCellVoltage_Cell051 0;
BA_ "GenSigTimeoutTime_BPCM" SG_ 1836 HVBatCellVoltage_Cell051 0;
BA_ "GenSigTimeoutTime_AGSM" SG_ 1836 HVBatCellVoltage_Cell051 0;
BA_ "GenSigTimeoutTime_PBWM" SG_ 1836 HVBatCellVoltage_Cell052 0;
BA_ "GenSigTimeoutTime_IDCM" SG_ 1836 HVBatCellVoltage_Cell052 0;
BA_ "GenSigTimeoutTime_EVCU2" SG_ 1836 HVBatCellVoltage_Cell052 0;
BA_ "GenSigTimeoutTime_ECM" SG_ 1836 HVBatCellVoltage_Cell052 0;
BA_ "GenSigTimeoutTime_DMPI" SG_ 1836 HVBatCellVoltage_Cell052 0;
BA_ "GenSigTimeoutTime_BPCM" SG_ 1836 HVBatCellVoltage_Cell052 0;
BA_ "GenSigTimeoutTime_AGSM" SG_ 1836 HVBatCellVoltage_Cell052 0;
BA_ "GenSigTimeoutTime_PBWM" SG_ 1836 HVBatCellVoltage_Cell053 0;
BA_ "GenSigTimeoutTime_IDCM" SG_ 1836 HVBatCellVoltage_Cell053 0;
BA_ "GenSigTimeoutTime_EVCU2" SG_ 1836 HVBatCellVoltage_Cell053 0;
BA_ "GenSigTimeoutTime_ECM" SG_ 1836 HVBatCellVoltage_Cell053 0;
BA_ "GenSigTimeoutTime_DMPI" SG_ 1836 HVBatCellVoltage_Cell053 0;
BA_ "GenSigTimeoutTime_BPCM" SG_ 1836 HVBatCellVoltage_Cell053 0;
BA_ "GenSigTimeoutTime_AGSM" SG_ 1836 HVBatCellVoltage_Cell053 0;
BA_ "GenSigTimeoutTime_PBWM" SG_ 1836 HVBatCellVoltage_Cell054 0;
BA_ "GenSigTimeoutTime_IDCM" SG_ 1836 HVBatCellVoltage_Cell054 0;
BA_ "GenSigTimeoutTime_EVCU2" SG_ 1836 HVBatCellVoltage_Cell054 0;
BA_ "GenSigTimeoutTime_ECM" SG_ 1836 HVBatCellVoltage_Cell054 0;
BA_ "GenSigTimeoutTime_DMPI" SG_ 1836 HVBatCellVoltage_Cell054 0;
BA_ "GenSigTimeoutTime_BPCM" SG_ 1836 HVBatCellVoltage_Cell054 0;
BA_ "GenSigTimeoutTime_AGSM" SG_ 1836 HVBatCellVoltage_Cell054 0;
BA_ "GenSigTimeoutTime_PBWM" SG_ 1837 HVBatCellVoltage_Cell055 0;
BA_ "GenSigTimeoutTime_IDCM" SG_ 1837 HVBatCellVoltage_Cell055 0;
BA_ "GenSigTimeoutTime_EVCU2" SG_ 1837 HVBatCellVoltage_Cell055 0;
BA_ "GenSigTimeoutTime_ECM" SG_ 1837 HVBatCellVoltage_Cell055 0;
BA_ "GenSigTimeoutTime_DMPI" SG_ 1837 HVBatCellVoltage_Cell055 0;
BA_ "GenSigTimeoutTime_BPCM" SG_ 1837 HVBatCellVoltage_Cell055 0;
BA_ "GenSigTimeoutTime_AGSM" SG_ 1837 HVBatCellVoltage_Cell055 0;
BA_ "GenSigTimeoutTime_PBWM" SG_ 1837 HVBatCellVoltage_Cell056 0;
BA_ "GenSigTimeoutTime_IDCM" SG_ 1837 HVBatCellVoltage_Cell056 0;
BA_ "GenSigTimeoutTime_EVCU2" SG_ 1837 HVBatCellVoltage_Cell056 0;
BA_ "GenSigTimeoutTime_ECM" SG_ 1837 HVBatCellVoltage_Cell056 0;
BA_ "GenSigTimeoutTime_DMPI" SG_ 1837 HVBatCellVoltage_Cell056 0;
BA_ "GenSigTimeoutTime_BPCM" SG_ 1837 HVBatCellVoltage_Cell056 0;
BA_ "GenSigTimeoutTime_AGSM" SG_ 1837 HVBatCellVoltage_Cell056 0;
BA_ "GenSigTimeoutTime_PBWM" SG_ 1837 HVBatCellVoltage_Cell057 0;
BA_ "GenSigTimeoutTime_IDCM" SG_ 1837 HVBatCellVoltage_Cell057 0;
BA_ "GenSigTimeoutTime_EVCU2" SG_ 1837 HVBatCellVoltage_Cell057 0;
BA_ "GenSigTimeoutTime_ECM" SG_ 1837 HVBatCellVoltage_Cell057 0;
BA_ "GenSigTimeoutTime_DMPI" SG_ 1837 HVBatCellVoltage_Cell057 0;
BA_ "GenSigTimeoutTime_BPCM" SG_ 1837 HVBatCellVoltage_Cell057 0;
BA_ "GenSigTimeoutTime_AGSM" SG_ 1837 HVBatCellVoltage_Cell057 0;
BA_ "GenSigTimeoutTime_PBWM" SG_ 1836 HVBatCellVoltage_Cell040 0;
BA_ "GenSigTimeoutTime_IDCM" SG_ 1836 HVBatCellVoltage_Cell040 0;
BA_ "GenSigTimeoutTime_EVCU2" SG_ 1836 HVBatCellVoltage_Cell040 0;
BA_ "GenSigTimeoutTime_ECM" SG_ 1836 HVBatCellVoltage_Cell040 0;
BA_ "GenSigTimeoutTime_DMPI" SG_ 1836 HVBatCellVoltage_Cell040 0;
BA_ "GenSigTimeoutTime_BPCM" SG_ 1836 HVBatCellVoltage_Cell040 0;
BA_ "GenSigTimeoutTime_AGSM" SG_ 1836 HVBatCellVoltage_Cell040 0;
BA_ "GenSigTimeoutTime_PBWM" SG_ 1836 HVBatCellVoltage_Cell038 0;
BA_ "GenSigTimeoutTime_IDCM" SG_ 1836 HVBatCellVoltage_Cell038 0;
BA_ "GenSigTimeoutTime_EVCU2" SG_ 1836 HVBatCellVoltage_Cell038 0;
BA_ "GenSigTimeoutTime_ECM" SG_ 1836 HVBatCellVoltage_Cell038 0;
BA_ "GenSigTimeoutTime_DMPI" SG_ 1836 HVBatCellVoltage_Cell038 0;
BA_ "GenSigTimeoutTime_BPCM" SG_ 1836 HVBatCellVoltage_Cell038 0;
BA_ "GenSigTimeoutTime_AGSM" SG_ 1836 HVBatCellVoltage_Cell038 0;
BA_ "GenSigTimeoutTime_PBWM" SG_ 1836 HVBatCellVoltage_Cell039 0;
BA_ "GenSigTimeoutTime_IDCM" SG_ 1836 HVBatCellVoltage_Cell039 0;
BA_ "GenSigTimeoutTime_EVCU2" SG_ 1836 HVBatCellVoltage_Cell039 0;
BA_ "GenSigTimeoutTime_ECM" SG_ 1836 HVBatCellVoltage_Cell039 0;
BA_ "GenSigTimeoutTime_DMPI" SG_ 1836 HVBatCellVoltage_Cell039 0;
BA_ "GenSigTimeoutTime_BPCM" SG_ 1836 HVBatCellVoltage_Cell039 0;
BA_ "GenSigTimeoutTime_AGSM" SG_ 1836 HVBatCellVoltage_Cell039 0;
BA_ "GenSigTimeoutTime_PBWM" SG_ 1836 HVBatCellVoltage_Cell034 0;
BA_ "GenSigTimeoutTime_IDCM" SG_ 1836 HVBatCellVoltage_Cell034 0;
BA_ "GenSigTimeoutTime_EVCU2" SG_ 1836 HVBatCellVoltage_Cell034 0;
BA_ "GenSigTimeoutTime_ECM" SG_ 1836 HVBatCellVoltage_Cell034 0;
BA_ "GenSigTimeoutTime_DMPI" SG_ 1836 HVBatCellVoltage_Cell034 0;
BA_ "GenSigTimeoutTime_BPCM" SG_ 1836 HVBatCellVoltage_Cell034 0;
BA_ "GenSigTimeoutTime_AGSM" SG_ 1836 HVBatCellVoltage_Cell034 0;
BA_ "GenSigTimeoutTime_PBWM" SG_ 1836 HVBatCellVoltage_Cell035 0;
BA_ "GenSigTimeoutTime_IDCM" SG_ 1836 HVBatCellVoltage_Cell035 0;
BA_ "GenSigTimeoutTime_EVCU2" SG_ 1836 HVBatCellVoltage_Cell035 0;
BA_ "GenSigTimeoutTime_ECM" SG_ 1836 HVBatCellVoltage_Cell035 0;
BA_ "GenSigTimeoutTime_DMPI" SG_ 1836 HVBatCellVoltage_Cell035 0;
BA_ "GenSigTimeoutTime_BPCM" SG_ 1836 HVBatCellVoltage_Cell035 0;
BA_ "GenSigTimeoutTime_AGSM" SG_ 1836 HVBatCellVoltage_Cell035 0;
BA_ "GenSigTimeoutTime_PBWM" SG_ 1836 HVBatCellVoltage_Cell036 0;
BA_ "GenSigTimeoutTime_IDCM" SG_ 1836 HVBatCellVoltage_Cell036 0;
BA_ "GenSigTimeoutTime_EVCU2" SG_ 1836 HVBatCellVoltage_Cell036 0;
BA_ "GenSigTimeoutTime_ECM" SG_ 1836 HVBatCellVoltage_Cell036 0;
BA_ "GenSigTimeoutTime_DMPI" SG_ 1836 HVBatCellVoltage_Cell036 0;
BA_ "GenSigTimeoutTime_BPCM" SG_ 1836 HVBatCellVoltage_Cell036 0;
BA_ "GenSigTimeoutTime_AGSM" SG_ 1836 HVBatCellVoltage_Cell036 0;
BA_ "GenSigTimeoutTime_PBWM" SG_ 1836 HVBatCellVoltage_Cell037 0;
BA_ "GenSigTimeoutTime_IDCM" SG_ 1836 HVBatCellVoltage_Cell037 0;
BA_ "GenSigTimeoutTime_EVCU2" SG_ 1836 HVBatCellVoltage_Cell037 0;
BA_ "GenSigTimeoutTime_ECM" SG_ 1836 HVBatCellVoltage_Cell037 0;
BA_ "GenSigTimeoutTime_DMPI" SG_ 1836 HVBatCellVoltage_Cell037 0;
BA_ "GenSigTimeoutTime_BPCM" SG_ 1836 HVBatCellVoltage_Cell037 0;
BA_ "GenSigTimeoutTime_AGSM" SG_ 1836 HVBatCellVoltage_Cell037 0;
BA_ "GenSigTimeoutTime_PBWM" SG_ 1836 HVBatCellVoltage_Cell028 0;
BA_ "GenSigTimeoutTime_IDCM" SG_ 1836 HVBatCellVoltage_Cell028 0;
BA_ "GenSigTimeoutTime_EVCU2" SG_ 1836 HVBatCellVoltage_Cell028 0;
BA_ "GenSigTimeoutTime_ECM" SG_ 1836 HVBatCellVoltage_Cell028 0;
BA_ "GenSigTimeoutTime_DMPI" SG_ 1836 HVBatCellVoltage_Cell028 0;
BA_ "GenSigTimeoutTime_BPCM" SG_ 1836 HVBatCellVoltage_Cell028 0;
BA_ "GenSigTimeoutTime_AGSM" SG_ 1836 HVBatCellVoltage_Cell028 0;
BA_ "GenSigTimeoutTime_PBWM" SG_ 1836 HVBatCellVoltage_Cell029 0;
BA_ "GenSigTimeoutTime_IDCM" SG_ 1836 HVBatCellVoltage_Cell029 0;
BA_ "GenSigTimeoutTime_EVCU2" SG_ 1836 HVBatCellVoltage_Cell029 0;
BA_ "GenSigTimeoutTime_ECM" SG_ 1836 HVBatCellVoltage_Cell029 0;
BA_ "GenSigTimeoutTime_DMPI" SG_ 1836 HVBatCellVoltage_Cell029 0;
BA_ "GenSigTimeoutTime_BPCM" SG_ 1836 HVBatCellVoltage_Cell029 0;
BA_ "GenSigTimeoutTime_AGSM" SG_ 1836 HVBatCellVoltage_Cell029 0;
BA_ "GenSigTimeoutTime_PBWM" SG_ 1836 HVBatCellVoltage_Cell030 0;
BA_ "GenSigTimeoutTime_IDCM" SG_ 1836 HVBatCellVoltage_Cell030 0;
BA_ "GenSigTimeoutTime_EVCU2" SG_ 1836 HVBatCellVoltage_Cell030 0;
BA_ "GenSigTimeoutTime_ECM" SG_ 1836 HVBatCellVoltage_Cell030 0;
BA_ "GenSigTimeoutTime_DMPI" SG_ 1836 HVBatCellVoltage_Cell030 0;
BA_ "GenSigTimeoutTime_BPCM" SG_ 1836 HVBatCellVoltage_Cell030 0;
BA_ "GenSigTimeoutTime_AGSM" SG_ 1836 HVBatCellVoltage_Cell030 0;
BA_ "GenSigTimeoutTime_PBWM" SG_ 1836 HVBatCellVoltage_Cell031 0;
BA_ "GenSigTimeoutTime_IDCM" SG_ 1836 HVBatCellVoltage_Cell031 0;
BA_ "GenSigTimeoutTime_EVCU2" SG_ 1836 HVBatCellVoltage_Cell031 0;
BA_ "GenSigTimeoutTime_ECM" SG_ 1836 HVBatCellVoltage_Cell031 0;
BA_ "GenSigTimeoutTime_DMPI" SG_ 1836 HVBatCellVoltage_Cell031 0;
BA_ "GenSigTimeoutTime_BPCM" SG_ 1836 HVBatCellVoltage_Cell031 0;
BA_ "GenSigTimeoutTime_AGSM" SG_ 1836 HVBatCellVoltage_Cell031 0;
BA_ "GenSigTimeoutTime_PBWM" SG_ 1836 HVBatCellVoltage_Cell032 0;
BA_ "GenSigTimeoutTime_IDCM" SG_ 1836 HVBatCellVoltage_Cell032 0;
BA_ "GenSigTimeoutTime_EVCU2" SG_ 1836 HVBatCellVoltage_Cell032 0;
BA_ "GenSigTimeoutTime_ECM" SG_ 1836 HVBatCellVoltage_Cell032 0;
BA_ "GenSigTimeoutTime_DMPI" SG_ 1836 HVBatCellVoltage_Cell032 0;
BA_ "GenSigTimeoutTime_BPCM" SG_ 1836 HVBatCellVoltage_Cell032 0;
BA_ "GenSigTimeoutTime_AGSM" SG_ 1836 HVBatCellVoltage_Cell032 0;
BA_ "GenSigTimeoutTime_PBWM" SG_ 1836 HVBatCellVoltage_Cell033 0;
BA_ "GenSigTimeoutTime_IDCM" SG_ 1836 HVBatCellVoltage_Cell033 0;
BA_ "GenSigTimeoutTime_EVCU2" SG_ 1836 HVBatCellVoltage_Cell033 0;
BA_ "GenSigTimeoutTime_ECM" SG_ 1836 HVBatCellVoltage_Cell033 0;
BA_ "GenSigTimeoutTime_DMPI" SG_ 1836 HVBatCellVoltage_Cell033 0;
BA_ "GenSigTimeoutTime_BPCM" SG_ 1836 HVBatCellVoltage_Cell033 0;
BA_ "GenSigTimeoutTime_AGSM" SG_ 1836 HVBatCellVoltage_Cell033 0;
BA_ "GenSigTimeoutTime_SGW" SG_ 1035 MaxEngSpdCap 0;
BA_ "GenSigTimeoutTime_PBWM" SG_ 1035 MaxEngSpdCap 0;
BA_ "GenSigTimeoutTime_IDCM" SG_ 1035 MaxEngSpdCap 0;
BA_ "GenSigTimeoutTime_ECM" SG_ 1035 MaxEngSpdCap 0;
BA_ "GenSigTimeoutTime_DMPI" SG_ 1035 MaxEngSpdCap 0;
BA_ "GenSigTimeoutTime_BPCM" SG_ 1035 MaxEngSpdCap 0;
BA_ "GenSigTimeoutTime_AGSM" SG_ 1035 MaxEngSpdCap 0;
BA_ "GenSigTimeoutTime_SGW" SG_ 1035 PECP_PumpFlowReq 0;
BA_ "GenSigTimeoutTime_PBWM" SG_ 1035 PECP_PumpFlowReq 0;
BA_ "GenSigTimeoutTime_IDCM" SG_ 1035 PECP_PumpFlowReq 0;
BA_ "GenSigTimeoutTime_ECM" SG_ 1035 PECP_PumpFlowReq 0;
BA_ "GenSigTimeoutTime_DMPI" SG_ 1035 PECP_PumpFlowReq 0;
BA_ "GenSigTimeoutTime_BPCM" SG_ 1035 PECP_PumpFlowReq 0;
BA_ "GenSigTimeoutTime_AGSM" SG_ 1035 PECP_PumpFlowReq 0;
BA_ "GenSigTimeoutTime_SGW" SG_ 1035 ServiceHybSys 0;
BA_ "GenSigTimeoutTime_PBWM" SG_ 1035 ServiceHybSys 0;
BA_ "GenSigTimeoutTime_IDCM" SG_ 1035 ServiceHybSys 0;
BA_ "GenSigTimeoutTime_ECM" SG_ 1035 ServiceHybSys 0;
BA_ "GenSigTimeoutTime_DMPI" SG_ 1035 ServiceHybSys 0;
BA_ "GenSigTimeoutTime_BPCM" SG_ 1035 ServiceHybSys 0;
BA_ "GenSigTimeoutTime_AGSM" SG_ 1035 ServiceHybSys 0;
BA_ "GenSigTimeoutTime_SGW" SG_ 1035 CRC_ENGINE_HYBD_FD_3 0;
BA_ "GenSigTimeoutTime_PBWM" SG_ 1035 CRC_ENGINE_HYBD_FD_3 0;
BA_ "GenSigTimeoutTime_IDCM" SG_ 1035 CRC_ENGINE_HYBD_FD_3 0;
BA_ "GenSigTimeoutTime_ECM" SG_ 1035 CRC_ENGINE_HYBD_FD_3 0;
BA_ "GenSigTimeoutTime_DMPI" SG_ 1035 CRC_ENGINE_HYBD_FD_3 0;
BA_ "GenSigTimeoutTime_BPCM" SG_ 1035 CRC_ENGINE_HYBD_FD_3 0;
BA_ "GenSigTimeoutTime_AGSM" SG_ 1035 CRC_ENGINE_HYBD_FD_3 0;
BA_ "GenSigTimeoutTime_SGW" SG_ 1035 MessageCounter_ENGINE_HYBD_FD_3 0;
BA_ "GenSigTimeoutTime_PBWM" SG_ 1035 MessageCounter_ENGINE_HYBD_FD_3 0;
BA_ "GenSigTimeoutTime_IDCM" SG_ 1035 MessageCounter_ENGINE_HYBD_FD_3 0;
BA_ "GenSigTimeoutTime_ECM" SG_ 1035 MessageCounter_ENGINE_HYBD_FD_3 0;
BA_ "GenSigTimeoutTime_DMPI" SG_ 1035 MessageCounter_ENGINE_HYBD_FD_3 0;
BA_ "GenSigTimeoutTime_BPCM" SG_ 1035 MessageCounter_ENGINE_HYBD_FD_3 0;
BA_ "GenSigTimeoutTime_AGSM" SG_ 1035 MessageCounter_ENGINE_HYBD_FD_3 0;
BA_ "GenSigTimeoutTime_SGW" SG_ 1035 EngCltTmp 0;
BA_ "GenSigTimeoutTime_PBWM" SG_ 1035 EngCltTmp 0;
BA_ "GenSigTimeoutTime_IDCM" SG_ 1035 EngCltTmp 0;
BA_ "GenSigTimeoutTime_ECM" SG_ 1035 EngCltTmp 0;
BA_ "GenSigTimeoutTime_AGSM" SG_ 1035 EngCltTmp 0;
BA_ "GenSigStartValue" SG_ 1035 EngCltTmp 255;
BA_ "GenSigTimeoutTime_SGW" SG_ 1035 EngCltTmpV 0;
BA_ "GenSigTimeoutTime_PBWM" SG_ 1035 EngCltTmpV 0;
BA_ "GenSigTimeoutTime_IDCM" SG_ 1035 EngCltTmpV 0;
BA_ "GenSigTimeoutTime_ECM" SG_ 1035 EngCltTmpV 0;
BA_ "GenSigTimeoutTime_AGSM" SG_ 1035 EngCltTmpV 0;
BA_ "GenSigTimeoutTime_SGW" SG_ 1035 EngOutofFuel 0;
BA_ "GenSigTimeoutTime_PBWM" SG_ 1035 EngOutofFuel 0;
BA_ "GenSigTimeoutTime_IDCM" SG_ 1035 EngOutofFuel 0;
BA_ "GenSigTimeoutTime_ECM" SG_ 1035 EngOutofFuel 0;
BA_ "GenSigTimeoutTime_DMPI" SG_ 1035 EngOutofFuel 0;
BA_ "GenSigTimeoutTime_BPCM" SG_ 1035 EngOutofFuel 0;
BA_ "GenSigTimeoutTime_AGSM" SG_ 1035 EngOutofFuel 0;
BA_ "GenSigTimeoutTime_SGW" SG_ 1035 EngSpd 0;
BA_ "GenSigTimeoutTime_PBWM" SG_ 1035 EngSpd 0;
BA_ "GenSigTimeoutTime_IDCM" SG_ 1035 EngSpd 0;
BA_ "GenSigTimeoutTime_ECM" SG_ 1035 EngSpd 0;
BA_ "GenSigTimeoutTime_DMPI" SG_ 1035 EngSpd 0;
BA_ "GenSigTimeoutTime_BPCM" SG_ 1035 EngSpd 0;
BA_ "GenSigTimeoutTime_AGSM" SG_ 1035 EngSpd 0;
BA_ "GenSigTimeoutTime_SGW" SG_ 1035 EngSpdStat 0;
BA_ "GenSigTimeoutTime_PBWM" SG_ 1035 EngSpdStat 0;
BA_ "GenSigTimeoutTime_IDCM" SG_ 1035 EngSpdStat 0;
BA_ "GenSigTimeoutTime_ECM" SG_ 1035 EngSpdStat 0;
BA_ "GenSigTimeoutTime_DMPI" SG_ 1035 EngSpdStat 0;
BA_ "GenSigTimeoutTime_BPCM" SG_ 1035 EngSpdStat 0;
BA_ "GenSigTimeoutTime_AGSM" SG_ 1035 EngSpdStat 0;
BA_ "GenSigTimeoutTime_SGW" SG_ 1035 MinEngSpdCap 0;
BA_ "GenSigTimeoutTime_PBWM" SG_ 1035 MinEngSpdCap 0;
BA_ "GenSigTimeoutTime_IDCM" SG_ 1035 MinEngSpdCap 0;
BA_ "GenSigTimeoutTime_ECM" SG_ 1035 MinEngSpdCap 0;
BA_ "GenSigTimeoutTime_DMPI" SG_ 1035 MinEngSpdCap 0;
BA_ "GenSigTimeoutTime_BPCM" SG_ 1035 MinEngSpdCap 0;
BA_ "GenSigTimeoutTime_AGSM" SG_ 1035 MinEngSpdCap 0;
BA_ "GenSigTimeoutTime_SGW" SG_ 1035 ECM_AirflowRequest 0;
BA_ "GenSigTimeoutTime_PBWM" SG_ 1035 ECM_AirflowRequest 0;
BA_ "GenSigTimeoutTime_IDCM" SG_ 1035 ECM_AirflowRequest 0;
BA_ "GenSigTimeoutTime_ECM" SG_ 1035 ECM_AirflowRequest 0;
BA_ "GenSigTimeoutTime_DMPI" SG_ 1035 ECM_AirflowRequest 0;
BA_ "GenSigTimeoutTime_BPCM" SG_ 1035 ECM_AirflowRequest 0;
BA_ "GenSigTimeoutTime_AGSM" SG_ 1035 ECM_AirflowRequest 0;
BA_ "GenSigTimeoutTime_SGW" SG_ 2564554482 N_PDU 0;
BA_ "GenSigTimeoutTime_PBWM" SG_ 2564554482 N_PDU 0;
BA_ "GenSigTimeoutTime_IDCM" SG_ 2564554482 N_PDU 0;
BA_ "GenSigTimeoutTime_EVCU2" SG_ 2564554482 N_PDU 0;
BA_ "GenSigTimeoutTime_ECM" SG_ 2564554482 N_PDU 0;
BA_ "GenSigTimeoutTime_DMPI" SG_ 2564554482 N_PDU 0;
BA_ "GenSigTimeoutTime_BPCM" SG_ 2564554482 N_PDU 0;
BA_ "GenSigTimeoutTime_AGSM" SG_ 2564554482 N_PDU 0;
BA_ "GenSigTimeoutTime_DMPI" SG_ 2564441329 N_PDU 0;
BA_ "GenSigTimeoutTime_BPCM" SG_ 2564441329 N_PDU 0;
BA_ "GenSigTimeoutTime_AGSM" SG_ 2564441329 N_PDU 0;
BA_ "GenSigTimeoutTime_SGW" SG_ 2564441329 N_PDU 0;
BA_ "GenSigTimeoutTime_PBWM" SG_ 2564441329 N_PDU 0;
BA_ "GenSigTimeoutTime_IDCM" SG_ 2564441329 N_PDU 0;
BA_ "GenSigTimeoutTime_EVCU2" SG_ 2564441329 N_PDU 0;
BA_ "GenSigTimeoutTime_ECM" SG_ 2564441329 N_PDU 0;
BA_ "GenSigTimeoutTime_SGW" SG_ 2564428018 N_PDU 0;
BA_ "GenSigTimeoutTime_PBWM" SG_ 2564428018 N_PDU 0;
BA_ "GenSigTimeoutTime_IDCM" SG_ 2564428018 N_PDU 0;
BA_ "GenSigTimeoutTime_EVCU2" SG_ 2564428018 N_PDU 0;
BA_ "GenSigTimeoutTime_ECM" SG_ 2564428018 N_PDU 0;
BA_ "GenSigTimeoutTime_DMPI" SG_ 2564428018 N_PDU 0;
BA_ "GenSigTimeoutTime_BPCM" SG_ 2564428018 N_PDU 0;
BA_ "GenSigTimeoutTime_AGSM" SG_ 2564428018 N_PDU 0;
BA_ "GenSigTimeoutTime_SGW" SG_ 2564485648 N_PDU 0;
BA_ "GenSigTimeoutTime_PBWM" SG_ 2564485648 N_PDU 0;
BA_ "GenSigTimeoutTime_IDCM" SG_ 2564485648 N_PDU 0;
BA_ "GenSigTimeoutTime_EVCU2" SG_ 2564485648 N_PDU 0;
BA_ "GenSigTimeoutTime_ECM" SG_ 2564485648 N_PDU 0;
BA_ "GenSigTimeoutTime_DMPI" SG_ 2564485648 N_PDU 0;
BA_ "GenSigTimeoutTime_BPCM" SG_ 2564485648 N_PDU 0;
BA_ "GenSigTimeoutTime_AGSM" SG_ 2564485648 N_PDU 0;
BA_ "GenSigTimeoutTime_SGW" SG_ 2564502513 N_PDU 0;
BA_ "GenSigTimeoutTime_PBWM" SG_ 2564502513 N_PDU 0;
BA_ "GenSigTimeoutTime_IDCM" SG_ 2564502513 N_PDU 0;
BA_ "GenSigTimeoutTime_EVCU2" SG_ 2564502513 N_PDU 0;
BA_ "GenSigTimeoutTime_ECM" SG_ 2564502513 N_PDU 0;
BA_ "GenSigTimeoutTime_DMPI" SG_ 2564502513 N_PDU 0;
BA_ "GenSigTimeoutTime_BPCM" SG_ 2564502513 N_PDU 0;
BA_ "GenSigTimeoutTime_AGSM" SG_ 2564502513 N_PDU 0;
BA_ "GenSigTimeoutTime_SGW" SG_ 2564554481 N_PDU 0;
BA_ "GenSigTimeoutTime_PBWM" SG_ 2564554481 N_PDU 0;
BA_ "GenSigTimeoutTime_IDCM" SG_ 2564554481 N_PDU 0;
BA_ "GenSigTimeoutTime_EVCU2" SG_ 2564554481 N_PDU 0;
BA_ "GenSigTimeoutTime_ECM" SG_ 2564554481 N_PDU 0;
BA_ "GenSigTimeoutTime_DMPI" SG_ 2564554481 N_PDU 0;
BA_ "GenSigTimeoutTime_BPCM" SG_ 2564554481 N_PDU 0;
BA_ "GenSigTimeoutTime_AGSM" SG_ 2564554481 N_PDU 0;
BA_ "GenSigTimeoutTime_SGW" SG_ 2564444401 N_PDU 0;
BA_ "GenSigTimeoutTime_PBWM" SG_ 2564444401 N_PDU 0;
BA_ "GenSigTimeoutTime_IDCM" SG_ 2564444401 N_PDU 0;
BA_ "GenSigTimeoutTime_EVCU2" SG_ 2564444401 N_PDU 0;
BA_ "GenSigTimeoutTime_ECM" SG_ 2564444401 N_PDU 0;
BA_ "GenSigTimeoutTime_DMPI" SG_ 2564444401 N_PDU 0;
BA_ "GenSigTimeoutTime_BPCM" SG_ 2564444401 N_PDU 0;
BA_ "GenSigTimeoutTime_AGSM" SG_ 2564444401 N_PDU 0;
BA_ "GenSigTimeoutTime_SGW" SG_ 2564485444 N_PDU 0;
BA_ "GenSigTimeoutTime_PBWM" SG_ 2564485444 N_PDU 0;
BA_ "GenSigTimeoutTime_IDCM" SG_ 2564485444 N_PDU 0;
BA_ "GenSigTimeoutTime_EVCU2" SG_ 2564485444 N_PDU 0;
BA_ "GenSigTimeoutTime_ECM" SG_ 2564485444 N_PDU 0;
BA_ "GenSigTimeoutTime_DMPI" SG_ 2564485444 N_PDU 0;
BA_ "GenSigTimeoutTime_BPCM" SG_ 2564485444 N_PDU 0;
BA_ "GenSigTimeoutTime_AGSM" SG_ 2564485444 N_PDU 0;
BA_ "GenSigTimeoutTime_SGW" SG_ 2651930624 Digit_11 0;
BA_ "GenSigTimeoutTime_IDCM" SG_ 2651930624 Digit_11 0;
BA_ "GenSigTimeoutTime_EVCU2" SG_ 2651930624 Digit_11 0;
BA_ "GenSigTimeoutTime_ECM" SG_ 2651930624 Digit_11 0;
BA_ "GenSigTimeoutTime_BPCM" SG_ 2651930624 Digit_11 0;
BA_ "GenSigTimeoutTime_AGSM" SG_ 2651930624 Digit_11 0;
BA_ "GenSigTimeoutTime_SGW" SG_ 2651930624 Digit_07 0;
BA_ "GenSigTimeoutTime_IDCM" SG_ 2651930624 Digit_07 0;
BA_ "GenSigTimeoutTime_EVCU2" SG_ 2651930624 Digit_07 0;
BA_ "GenSigTimeoutTime_ECM" SG_ 2651930624 Digit_07 0;
BA_ "GenSigTimeoutTime_BPCM" SG_ 2651930624 Digit_07 0;
BA_ "GenSigTimeoutTime_AGSM" SG_ 2651930624 Digit_07 0;
BA_ "GenSigTimeoutTime_SGW" SG_ 2651930624 Digit_08 0;
BA_ "GenSigTimeoutTime_IDCM" SG_ 2651930624 Digit_08 0;
BA_ "GenSigTimeoutTime_EVCU2" SG_ 2651930624 Digit_08 0;
BA_ "GenSigTimeoutTime_ECM" SG_ 2651930624 Digit_08 0;
BA_ "GenSigTimeoutTime_BPCM" SG_ 2651930624 Digit_08 0;
BA_ "GenSigTimeoutTime_AGSM" SG_ 2651930624 Digit_08 0;
BA_ "GenSigTimeoutTime_SGW" SG_ 2651930624 Digit_09 0;
BA_ "GenSigTimeoutTime_IDCM" SG_ 2651930624 Digit_09 0;
BA_ "GenSigTimeoutTime_EVCU2" SG_ 2651930624 Digit_09 0;
BA_ "GenSigTimeoutTime_ECM" SG_ 2651930624 Digit_09 0;
BA_ "GenSigTimeoutTime_BPCM" SG_ 2651930624 Digit_09 0;
BA_ "GenSigTimeoutTime_AGSM" SG_ 2651930624 Digit_09 0;
BA_ "GenSigTimeoutTime_SGW" SG_ 2651930624 Digit_10 0;
BA_ "GenSigTimeoutTime_IDCM" SG_ 2651930624 Digit_10 0;
BA_ "GenSigTimeoutTime_EVCU2" SG_ 2651930624 Digit_10 0;
BA_ "GenSigTimeoutTime_ECM" SG_ 2651930624 Digit_10 0;
BA_ "GenSigTimeoutTime_BPCM" SG_ 2651930624 Digit_10 0;
BA_ "GenSigTimeoutTime_AGSM" SG_ 2651930624 Digit_10 0;
BA_ "GenSigTimeoutTime_SGW" SG_ 2651930624 Digit_01 0;
BA_ "GenSigTimeoutTime_IDCM" SG_ 2651930624 Digit_01 0;
BA_ "GenSigTimeoutTime_EVCU2" SG_ 2651930624 Digit_01 0;
BA_ "GenSigTimeoutTime_ECM" SG_ 2651930624 Digit_01 0;
BA_ "GenSigTimeoutTime_BPCM" SG_ 2651930624 Digit_01 0;
BA_ "GenSigTimeoutTime_AGSM" SG_ 2651930624 Digit_01 0;
BA_ "GenSigTimeoutTime_SGW" SG_ 2651930624 Digit_02 0;
BA_ "GenSigTimeoutTime_IDCM" SG_ 2651930624 Digit_02 0;
BA_ "GenSigTimeoutTime_EVCU2" SG_ 2651930624 Digit_02 0;
BA_ "GenSigTimeoutTime_ECM" SG_ 2651930624 Digit_02 0;
BA_ "GenSigTimeoutTime_BPCM" SG_ 2651930624 Digit_02 0;
BA_ "GenSigTimeoutTime_AGSM" SG_ 2651930624 Digit_02 0;
BA_ "GenSigTimeoutTime_SGW" SG_ 2651930624 Digit_03 0;
BA_ "GenSigTimeoutTime_IDCM" SG_ 2651930624 Digit_03 0;
BA_ "GenSigTimeoutTime_EVCU2" SG_ 2651930624 Digit_03 0;
BA_ "GenSigTimeoutTime_ECM" SG_ 2651930624 Digit_03 0;
BA_ "GenSigTimeoutTime_BPCM" SG_ 2651930624 Digit_03 0;
BA_ "GenSigTimeoutTime_AGSM" SG_ 2651930624 Digit_03 0;
BA_ "GenSigTimeoutTime_SGW" SG_ 2651930624 Digit_04 0;
BA_ "GenSigTimeoutTime_IDCM" SG_ 2651930624 Digit_04 0;
BA_ "GenSigTimeoutTime_EVCU2" SG_ 2651930624 Digit_04 0;
BA_ "GenSigTimeoutTime_ECM" SG_ 2651930624 Digit_04 0;
BA_ "GenSigTimeoutTime_BPCM" SG_ 2651930624 Digit_04 0;
BA_ "GenSigTimeoutTime_AGSM" SG_ 2651930624 Digit_04 0;
BA_ "GenSigTimeoutTime_SGW" SG_ 2651930624 Digit_05 0;
BA_ "GenSigTimeoutTime_IDCM" SG_ 2651930624 Digit_05 0;
BA_ "GenSigTimeoutTime_EVCU2" SG_ 2651930624 Digit_05 0;
BA_ "GenSigTimeoutTime_ECM" SG_ 2651930624 Digit_05 0;
BA_ "GenSigTimeoutTime_BPCM" SG_ 2651930624 Digit_05 0;
BA_ "GenSigTimeoutTime_AGSM" SG_ 2651930624 Digit_05 0;
BA_ "GenSigTimeoutTime_SGW" SG_ 2651930624 Digit_06 0;
BA_ "GenSigTimeoutTime_IDCM" SG_ 2651930624 Digit_06 0;
BA_ "GenSigTimeoutTime_EVCU2" SG_ 2651930624 Digit_06 0;
BA_ "GenSigTimeoutTime_ECM" SG_ 2651930624 Digit_06 0;
BA_ "GenSigTimeoutTime_BPCM" SG_ 2651930624 Digit_06 0;
BA_ "GenSigTimeoutTime_AGSM" SG_ 2651930624 Digit_06 0;
BA_ "GenSigTimeoutTime_SGW" SG_ 1066 ExternalTemperature 0;
BA_ "GenSigTimeoutTime_PBWM" SG_ 1066 ExternalTemperature 0;
BA_ "GenSigTimeoutTime_SGW" SG_ 1153 CmdIgnSts 0;
BA_ "GenSigTimeoutTime_PBWM" SG_ 1153 CmdIgnSts 0;
BA_ "GenSigTimeoutTime_EVCU2" SG_ 1153 CmdIgnSts 0;
BA_ "GenSigTimeoutTime_ECM" SG_ 1153 CmdIgnSts 0;
BA_ "GenSigTimeoutTime_DMPI" SG_ 1153 CmdIgnSts 0;
BA_ "GenSigTimeoutTime_AGSM" SG_ 1153 CmdIgnSts 0;
BA_ "GenSigSendType" SG_ 1153 CmdIgnSts 3;
BA_ "GenSigTimeoutTime_SGW" SG_ 1153 ExternalTemperatureC 0;
BA_ "GenSigTimeoutTime_PBWM" SG_ 1153 ExternalTemperatureC 0;
BA_ "GenSigTimeoutTime_EVCU2" SG_ 1153 ExternalTemperatureC 0;
BA_ "GenSigTimeoutTime_ECM" SG_ 1153 ExternalTemperatureC 0;
BA_ "GenSigTimeoutTime_DMPI" SG_ 1153 ExternalTemperatureC 0;
BA_ "GenSigTimeoutTime_AGSM" SG_ 1153 ExternalTemperatureC 0;
BA_ "GenSigStartValue" SG_ 1153 ExternalTemperatureC 511;
BA_ "GenSigTimeoutTime_SGW" SG_ 1827 IgnitionOnCounter 0;
BA_ "GenSigTimeoutTime_PBWM" SG_ 1827 IgnitionOnCounter 0;
BA_ "GenSigTimeoutTime_EVCU2" SG_ 1827 IgnitionOnCounter 0;
BA_ "GenSigTimeoutTime_ECM" SG_ 1827 IgnitionOnCounter 0;
BA_ "GenSigTimeoutTime_DMPI" SG_ 1827 IgnitionOnCounter 0;
BA_ "GenSigTimeoutTime_AGSM" SG_ 1827 IgnitionOnCounter 0;
BA_ "GenSigTimeoutTime_SGW" SG_ 750 Battery_Volt_1 0;
BA_ "GenSigTimeoutTime_PBWM" SG_ 750 Battery_Volt_1 0;
BA_ "GenSigTimeoutTime_EVCU2" SG_ 750 Battery_Volt_1 0;
BA_ "GenSigTimeoutTime_ECM" SG_ 750 Battery_Volt_1 0;
BA_ "GenSigTimeoutTime_DMPI" SG_ 750 Battery_Volt_1 0;
BA_ "GenSigTimeoutTime_AGSM" SG_ 750 Battery_Volt_1 0;
BA_ "GenSigTimeoutTime_EVCU2" SG_ 1066 ExternalTemperature 0;
BA_ "GenSigTimeoutTime_ECM" SG_ 1066 ExternalTemperature 0;
BA_ "GenSigTimeoutTime_DMPI" SG_ 1066 ExternalTemperature 0;
BA_ "GenSigTimeoutTime_AGSM" SG_ 1066 ExternalTemperature 0;
BA_ "GenSigTimeoutTime_DMPI" SG_ 1839 HVBatModuleTemp_04 0;
BA_ "GenSigTimeoutTime_BPCM" SG_ 1839 HVBatModuleTemp_04 0;
BA_ "GenSigTimeoutTime_AGSM" SG_ 1839 HVBatModuleTemp_04 0;
BA_ "GenSigTimeoutTime_PBWM" SG_ 1839 HVBatModuleTemp_05 0;
BA_ "GenSigTimeoutTime_IDCM" SG_ 1839 HVBatModuleTemp_05 0;
BA_ "GenSigTimeoutTime_EVCU2" SG_ 1839 HVBatModuleTemp_05 0;
BA_ "GenSigTimeoutTime_ECM" SG_ 1839 HVBatModuleTemp_05 0;
BA_ "GenSigTimeoutTime_DMPI" SG_ 1839 HVBatModuleTemp_05 0;
BA_ "GenSigTimeoutTime_BPCM" SG_ 1839 HVBatModuleTemp_05 0;
BA_ "GenSigTimeoutTime_AGSM" SG_ 1839 HVBatModuleTemp_05 0;
BA_ "GenSigTimeoutTime_PBWM" SG_ 1839 HVBatModuleTemp_06 0;
BA_ "GenSigTimeoutTime_IDCM" SG_ 1839 HVBatModuleTemp_06 0;
BA_ "GenSigTimeoutTime_EVCU2" SG_ 1839 HVBatModuleTemp_06 0;
BA_ "GenSigTimeoutTime_ECM" SG_ 1839 HVBatModuleTemp_06 0;
BA_ "GenSigTimeoutTime_DMPI" SG_ 1839 HVBatModuleTemp_06 0;
BA_ "GenSigTimeoutTime_BPCM" SG_ 1839 HVBatModuleTemp_06 0;
BA_ "GenSigTimeoutTime_AGSM" SG_ 1839 HVBatModuleTemp_06 0;
BA_ "GenSigTimeoutTime_PBWM" SG_ 1839 HVBatModuleTemp_07 0;
BA_ "GenSigTimeoutTime_IDCM" SG_ 1839 HVBatModuleTemp_07 0;
BA_ "GenSigTimeoutTime_EVCU2" SG_ 1839 HVBatModuleTemp_07 0;
BA_ "GenSigTimeoutTime_ECM" SG_ 1839 HVBatModuleTemp_07 0;
BA_ "GenSigTimeoutTime_DMPI" SG_ 1839 HVBatModuleTemp_07 0;
BA_ "GenSigTimeoutTime_BPCM" SG_ 1839 HVBatModuleTemp_07 0;
BA_ "GenSigTimeoutTime_AGSM" SG_ 1839 HVBatModuleTemp_07 0;
BA_ "GenSigTimeoutTime_PBWM" SG_ 1839 HVBatModuleTemp_08 0;
BA_ "GenSigTimeoutTime_IDCM" SG_ 1839 HVBatModuleTemp_08 0;
BA_ "GenSigTimeoutTime_EVCU2" SG_ 1839 HVBatModuleTemp_08 0;
BA_ "GenSigTimeoutTime_ECM" SG_ 1839 HVBatModuleTemp_08 0;
BA_ "GenSigTimeoutTime_DMPI" SG_ 1839 HVBatModuleTemp_08 0;
BA_ "GenSigTimeoutTime_BPCM" SG_ 1839 HVBatModuleTemp_08 0;
BA_ "GenSigTimeoutTime_AGSM" SG_ 1839 HVBatModuleTemp_08 0;
BA_ "GenSigTimeoutTime_PBWM" SG_ 1839 HVBatModuleTemp_09 0;
BA_ "GenSigTimeoutTime_IDCM" SG_ 1839 HVBatModuleTemp_09 0;
BA_ "GenSigTimeoutTime_EVCU2" SG_ 1839 HVBatModuleTemp_09 0;
BA_ "GenSigTimeoutTime_ECM" SG_ 1839 HVBatModuleTemp_09 0;
BA_ "GenSigTimeoutTime_DMPI" SG_ 1839 HVBatModuleTemp_09 0;
BA_ "GenSigTimeoutTime_BPCM" SG_ 1839 HVBatModuleTemp_09 0;
BA_ "GenSigTimeoutTime_AGSM" SG_ 1839 HVBatModuleTemp_09 0;
BA_ "GenSigTimeoutTime_PBWM" SG_ 1839 HVBatModuleTemp_10 0;
BA_ "GenSigTimeoutTime_IDCM" SG_ 1839 HVBatModuleTemp_10 0;
BA_ "GenSigTimeoutTime_EVCU2" SG_ 1839 HVBatModuleTemp_10 0;
BA_ "GenSigTimeoutTime_ECM" SG_ 1839 HVBatModuleTemp_10 0;
BA_ "GenSigTimeoutTime_DMPI" SG_ 1839 HVBatModuleTemp_10 0;
BA_ "GenSigTimeoutTime_BPCM" SG_ 1839 HVBatModuleTemp_10 0;
BA_ "GenSigTimeoutTime_AGSM" SG_ 1839 HVBatModuleTemp_10 0;
BA_ "GenSigTimeoutTime_PBWM" SG_ 1839 HVBatModuleTemp_11 0;
BA_ "GenSigTimeoutTime_IDCM" SG_ 1839 HVBatModuleTemp_11 0;
BA_ "GenSigTimeoutTime_EVCU2" SG_ 1839 HVBatModuleTemp_11 0;
BA_ "GenSigTimeoutTime_ECM" SG_ 1839 HVBatModuleTemp_11 0;
BA_ "GenSigTimeoutTime_DMPI" SG_ 1839 HVBatModuleTemp_11 0;
BA_ "GenSigTimeoutTime_BPCM" SG_ 1839 HVBatModuleTemp_11 0;
BA_ "GenSigTimeoutTime_AGSM" SG_ 1839 HVBatModuleTemp_11 0;
BA_ "GenSigTimeoutTime_PBWM" SG_ 1839 HVBatModuleTemp_12 0;
BA_ "GenSigTimeoutTime_IDCM" SG_ 1839 HVBatModuleTemp_12 0;
BA_ "GenSigTimeoutTime_EVCU2" SG_ 1839 HVBatModuleTemp_12 0;
BA_ "GenSigTimeoutTime_ECM" SG_ 1839 HVBatModuleTemp_12 0;
BA_ "GenSigTimeoutTime_DMPI" SG_ 1839 HVBatModuleTemp_12 0;
BA_ "GenSigTimeoutTime_BPCM" SG_ 1839 HVBatModuleTemp_12 0;
BA_ "GenSigTimeoutTime_AGSM" SG_ 1839 HVBatModuleTemp_12 0;
BA_ "GenSigTimeoutTime_PBWM" SG_ 1839 HVBatModuleTemp_13 0;
BA_ "GenSigTimeoutTime_IDCM" SG_ 1839 HVBatModuleTemp_13 0;
BA_ "GenSigTimeoutTime_EVCU2" SG_ 1839 HVBatModuleTemp_13 0;
BA_ "GenSigTimeoutTime_ECM" SG_ 1839 HVBatModuleTemp_13 0;
BA_ "GenSigTimeoutTime_DMPI" SG_ 1839 HVBatModuleTemp_13 0;
BA_ "GenSigTimeoutTime_BPCM" SG_ 1839 HVBatModuleTemp_13 0;
BA_ "GenSigTimeoutTime_AGSM" SG_ 1839 HVBatModuleTemp_13 0;
BA_ "GenSigTimeoutTime_PBWM" SG_ 1839 HVBatModuleTemp_14 0;
BA_ "GenSigTimeoutTime_IDCM" SG_ 1839 HVBatModuleTemp_14 0;
BA_ "GenSigTimeoutTime_EVCU2" SG_ 1839 HVBatModuleTemp_14 0;
BA_ "GenSigTimeoutTime_ECM" SG_ 1839 HVBatModuleTemp_14 0;
BA_ "GenSigTimeoutTime_DMPI" SG_ 1839 HVBatModuleTemp_14 0;
BA_ "GenSigTimeoutTime_BPCM" SG_ 1839 HVBatModuleTemp_14 0;
BA_ "GenSigTimeoutTime_AGSM" SG_ 1839 HVBatModuleTemp_14 0;
BA_ "GenSigTimeoutTime_PBWM" SG_ 1839 HVBatModuleTemp_15 0;
BA_ "GenSigTimeoutTime_IDCM" SG_ 1839 HVBatModuleTemp_15 0;
BA_ "GenSigTimeoutTime_EVCU2" SG_ 1839 HVBatModuleTemp_15 0;
BA_ "GenSigTimeoutTime_ECM" SG_ 1839 HVBatModuleTemp_15 0;
BA_ "GenSigTimeoutTime_DMPI" SG_ 1839 HVBatModuleTemp_15 0;
BA_ "GenSigTimeoutTime_BPCM" SG_ 1839 HVBatModuleTemp_15 0;
BA_ "GenSigTimeoutTime_AGSM" SG_ 1839 HVBatModuleTemp_15 0;
BA_ "GenSigTimeoutTime_PBWM" SG_ 1839 HVBatModuleTemp_16 0;
BA_ "GenSigTimeoutTime_IDCM" SG_ 1839 HVBatModuleTemp_16 0;
BA_ "GenSigTimeoutTime_EVCU2" SG_ 1839 HVBatModuleTemp_16 0;
BA_ "GenSigTimeoutTime_ECM" SG_ 1839 HVBatModuleTemp_16 0;
BA_ "GenSigTimeoutTime_DMPI" SG_ 1839 HVBatModuleTemp_16 0;
BA_ "GenSigTimeoutTime_BPCM" SG_ 1839 HVBatModuleTemp_16 0;
BA_ "GenSigTimeoutTime_AGSM" SG_ 1839 HVBatModuleTemp_16 0;
BA_ "GenSigTimeoutTime_PBWM" SG_ 1840 Warning_PackUnmatched 0;
BA_ "GenSigTimeoutTime_IDCM" SG_ 1840 Warning_PackUnmatched 0;
BA_ "GenSigTimeoutTime_EVCU2" SG_ 1840 Warning_PackUnmatched 0;
BA_ "GenSigTimeoutTime_ECM" SG_ 1840 Warning_PackUnmatched 0;
BA_ "GenSigTimeoutTime_DMPI" SG_ 1840 Warning_PackUnmatched 0;
BA_ "GenSigTimeoutTime_BPCM" SG_ 1840 Warning_PackUnmatched 0;
BA_ "GenSigTimeoutTime_AGSM" SG_ 1840 Warning_PackUnmatched 0;
BA_ "GenSigTimeoutTime_PBWM" SG_ 1840 Warning_SOCJump 0;
BA_ "GenSigTimeoutTime_IDCM" SG_ 1840 Warning_SOCJump 0;
BA_ "GenSigTimeoutTime_EVCU2" SG_ 1840 Warning_SOCJump 0;
BA_ "GenSigTimeoutTime_ECM" SG_ 1840 Warning_SOCJump 0;
BA_ "GenSigTimeoutTime_DMPI" SG_ 1840 Warning_SOCJump 0;
BA_ "GenSigTimeoutTime_BPCM" SG_ 1840 Warning_SOCJump 0;
BA_ "GenSigTimeoutTime_AGSM" SG_ 1840 Warning_SOCJump 0;
BA_ "GenSigTimeoutTime_SGW" SG_ 1839 HVBatModuleTemp_17 0;
BA_ "GenSigTimeoutTime_PBWM" SG_ 1839 HVBatModuleTemp_17 0;
BA_ "GenSigTimeoutTime_IDCM" SG_ 1839 HVBatModuleTemp_17 0;
BA_ "GenSigTimeoutTime_EVCU2" SG_ 1839 HVBatModuleTemp_17 0;
BA_ "GenSigTimeoutTime_ECM" SG_ 1839 HVBatModuleTemp_17 0;
BA_ "GenSigTimeoutTime_DMPI" SG_ 1839 HVBatModuleTemp_17 0;
BA_ "GenSigTimeoutTime_BPCM" SG_ 1839 HVBatModuleTemp_17 0;
BA_ "GenSigTimeoutTime_AGSM" SG_ 1839 HVBatModuleTemp_17 0;
BA_ "GenSigTimeoutTime_SGW" SG_ 1839 HVBatModuleTemp_18 0;
BA_ "GenSigTimeoutTime_PBWM" SG_ 1839 HVBatModuleTemp_18 0;
BA_ "GenSigTimeoutTime_IDCM" SG_ 1839 HVBatModuleTemp_18 0;
BA_ "GenSigTimeoutTime_EVCU2" SG_ 1839 HVBatModuleTemp_18 0;
BA_ "GenSigTimeoutTime_ECM" SG_ 1839 HVBatModuleTemp_18 0;
BA_ "GenSigTimeoutTime_DMPI" SG_ 1839 HVBatModuleTemp_18 0;
BA_ "GenSigTimeoutTime_BPCM" SG_ 1839 HVBatModuleTemp_18 0;
BA_ "GenSigTimeoutTime_AGSM" SG_ 1839 HVBatModuleTemp_18 0;
BA_ "GenSigTimeoutTime_SGW" SG_ 1839 HVBatModuleTemp_19 0;
BA_ "GenSigTimeoutTime_PBWM" SG_ 1839 HVBatModuleTemp_19 0;
BA_ "GenSigTimeoutTime_IDCM" SG_ 1839 HVBatModuleTemp_19 0;
BA_ "GenSigTimeoutTime_EVCU2" SG_ 1839 HVBatModuleTemp_19 0;
BA_ "GenSigTimeoutTime_ECM" SG_ 1839 HVBatModuleTemp_19 0;
BA_ "GenSigTimeoutTime_DMPI" SG_ 1839 HVBatModuleTemp_19 0;
BA_ "GenSigTimeoutTime_BPCM" SG_ 1839 HVBatModuleTemp_19 0;
BA_ "GenSigTimeoutTime_AGSM" SG_ 1839 HVBatModuleTemp_19 0;
BA_ "GenSigTimeoutTime_SGW" SG_ 1839 HVBatModuleTemp_20 0;
BA_ "GenSigTimeoutTime_PBWM" SG_ 1839 HVBatModuleTemp_20 0;
BA_ "GenSigTimeoutTime_IDCM" SG_ 1839 HVBatModuleTemp_20 0;
BA_ "GenSigTimeoutTime_EVCU2" SG_ 1839 HVBatModuleTemp_20 0;
BA_ "GenSigTimeoutTime_ECM" SG_ 1839 HVBatModuleTemp_20 0;
BA_ "GenSigTimeoutTime_DMPI" SG_ 1839 HVBatModuleTemp_20 0;
BA_ "GenSigTimeoutTime_BPCM" SG_ 1839 HVBatModuleTemp_20 0;
BA_ "GenSigTimeoutTime_AGSM" SG_ 1839 HVBatModuleTemp_20 0;
BA_ "GenSigTimeoutTime_SGW" SG_ 1839 HVBatModuleTemp_21 0;
BA_ "GenSigTimeoutTime_PBWM" SG_ 1839 HVBatModuleTemp_21 0;
BA_ "GenSigTimeoutTime_IDCM" SG_ 1839 HVBatModuleTemp_21 0;
BA_ "GenSigTimeoutTime_EVCU2" SG_ 1839 HVBatModuleTemp_21 0;
BA_ "GenSigTimeoutTime_ECM" SG_ 1839 HVBatModuleTemp_21 0;
BA_ "GenSigTimeoutTime_DMPI" SG_ 1839 HVBatModuleTemp_21 0;
BA_ "GenSigTimeoutTime_BPCM" SG_ 1839 HVBatModuleTemp_21 0;
BA_ "GenSigTimeoutTime_AGSM" SG_ 1839 HVBatModuleTemp_21 0;
BA_ "GenSigTimeoutTime_SGW" SG_ 1839 HVBatModuleTemp_22 0;
BA_ "GenSigTimeoutTime_PBWM" SG_ 1839 HVBatModuleTemp_22 0;
BA_ "GenSigTimeoutTime_IDCM" SG_ 1839 HVBatModuleTemp_22 0;
BA_ "GenSigTimeoutTime_EVCU2" SG_ 1839 HVBatModuleTemp_22 0;
BA_ "GenSigTimeoutTime_ECM" SG_ 1839 HVBatModuleTemp_22 0;
BA_ "GenSigTimeoutTime_DMPI" SG_ 1839 HVBatModuleTemp_22 0;
BA_ "GenSigTimeoutTime_BPCM" SG_ 1839 HVBatModuleTemp_22 0;
BA_ "GenSigTimeoutTime_AGSM" SG_ 1839 HVBatModuleTemp_22 0;
BA_ "GenSigTimeoutTime_SGW" SG_ 1839 HVBatModuleTemp_23 0;
BA_ "GenSigTimeoutTime_PBWM" SG_ 1839 HVBatModuleTemp_23 0;
BA_ "GenSigTimeoutTime_IDCM" SG_ 1839 HVBatModuleTemp_23 0;
BA_ "GenSigTimeoutTime_EVCU2" SG_ 1839 HVBatModuleTemp_23 0;
BA_ "GenSigTimeoutTime_ECM" SG_ 1839 HVBatModuleTemp_23 0;
BA_ "GenSigTimeoutTime_DMPI" SG_ 1839 HVBatModuleTemp_23 0;
BA_ "GenSigTimeoutTime_BPCM" SG_ 1839 HVBatModuleTemp_23 0;
BA_ "GenSigTimeoutTime_AGSM" SG_ 1839 HVBatModuleTemp_23 0;
BA_ "GenSigTimeoutTime_SGW" SG_ 1839 HVBatModuleTemp_24 0;
BA_ "GenSigTimeoutTime_PBWM" SG_ 1839 HVBatModuleTemp_24 0;
BA_ "GenSigTimeoutTime_IDCM" SG_ 1839 HVBatModuleTemp_24 0;
BA_ "GenSigTimeoutTime_EVCU2" SG_ 1839 HVBatModuleTemp_24 0;
BA_ "GenSigTimeoutTime_ECM" SG_ 1839 HVBatModuleTemp_24 0;
BA_ "GenSigTimeoutTime_DMPI" SG_ 1839 HVBatModuleTemp_24 0;
BA_ "GenSigTimeoutTime_BPCM" SG_ 1839 HVBatModuleTemp_24 0;
BA_ "GenSigTimeoutTime_AGSM" SG_ 1839 HVBatModuleTemp_24 0;
BA_ "GenSigTimeoutTime_SGW" SG_ 1839 HVBatModuleTemp_25 0;
BA_ "GenSigTimeoutTime_PBWM" SG_ 1839 HVBatModuleTemp_25 0;
BA_ "GenSigTimeoutTime_IDCM" SG_ 1839 HVBatModuleTemp_25 0;
BA_ "GenSigTimeoutTime_EVCU2" SG_ 1839 HVBatModuleTemp_25 0;
BA_ "GenSigTimeoutTime_ECM" SG_ 1839 HVBatModuleTemp_25 0;
BA_ "GenSigTimeoutTime_DMPI" SG_ 1839 HVBatModuleTemp_25 0;
BA_ "GenSigTimeoutTime_BPCM" SG_ 1839 HVBatModuleTemp_25 0;
BA_ "GenSigTimeoutTime_AGSM" SG_ 1839 HVBatModuleTemp_25 0;
BA_ "GenSigTimeoutTime_SGW" SG_ 1839 HVBatModuleTemp_26 0;
BA_ "GenSigTimeoutTime_PBWM" SG_ 1839 HVBatModuleTemp_26 0;
BA_ "GenSigTimeoutTime_IDCM" SG_ 1839 HVBatModuleTemp_26 0;
BA_ "GenSigTimeoutTime_EVCU2" SG_ 1839 HVBatModuleTemp_26 0;
BA_ "GenSigTimeoutTime_ECM" SG_ 1839 HVBatModuleTemp_26 0;
BA_ "GenSigTimeoutTime_DMPI" SG_ 1839 HVBatModuleTemp_26 0;
BA_ "GenSigTimeoutTime_BPCM" SG_ 1839 HVBatModuleTemp_26 0;
BA_ "GenSigTimeoutTime_AGSM" SG_ 1839 HVBatModuleTemp_26 0;
BA_ "GenSigTimeoutTime_PBWM" SG_ 1840 Warning_PackUndervoltage 0;
BA_ "GenSigTimeoutTime_IDCM" SG_ 1840 Warning_PackUndervoltage 0;
BA_ "GenSigTimeoutTime_EVCU2" SG_ 1840 Warning_PackUndervoltage 0;
BA_ "GenSigTimeoutTime_ECM" SG_ 1840 Warning_PackUndervoltage 0;
BA_ "GenSigTimeoutTime_DMPI" SG_ 1840 Warning_PackUndervoltage 0;
BA_ "GenSigTimeoutTime_SGW" SG_ 1036 EngineOilTemperature 0;
BA_ "GenSigTimeoutTime_PBWM" SG_ 1036 EngineOilTemperature 0;
BA_ "GenSigTimeoutTime_IDCM" SG_ 1036 EngineOilTemperature 0;
BA_ "GenSigTimeoutTime_EVCU2" SG_ 1036 EngineOilTemperature 0;
BA_ "GenSigTimeoutTime_ECM" SG_ 1036 EngineOilTemperature 0;
BA_ "GenSigTimeoutTime_DMPI" SG_ 1036 EngineOilTemperature 0;
BA_ "GenSigTimeoutTime_BPCM" SG_ 1036 EngineOilTemperature 0;
BA_ "GenSigTimeoutTime_AGSM" SG_ 1036 EngineOilTemperature 0;
BA_ "GenSigStartValue" SG_ 1036 EngineOilTemperature 255;
BA_ "GenSigTimeoutTime_SGW" SG_ 2564485456 N_PDU 0;
BA_ "GenSigTimeoutTime_PBWM" SG_ 2564485456 N_PDU 0;
BA_ "GenSigTimeoutTime_IDCM" SG_ 2564485456 N_PDU 0;
BA_ "GenSigTimeoutTime_EVCU2" SG_ 2564485456 N_PDU 0;
BA_ "GenSigTimeoutTime_ECM" SG_ 2564485456 N_PDU 0;
BA_ "GenSigTimeoutTime_DMPI" SG_ 2564485456 N_PDU 0;
BA_ "GenSigTimeoutTime_BPCM" SG_ 2564485456 N_PDU 0;
BA_ "GenSigTimeoutTime_AGSM" SG_ 2564485456 N_PDU 0;
BA_ "GenSigTimeoutTime_SGW" SG_ 751 EngineWaterTemp 0;
BA_ "GenSigTimeoutTime_PBWM" SG_ 751 EngineWaterTemp 0;
BA_ "GenSigTimeoutTime_IDCM" SG_ 751 EngineWaterTemp 0;
BA_ "GenSigTimeoutTime_EVCU2" SG_ 751 EngineWaterTemp 0;
BA_ "GenSigTimeoutTime_ECM" SG_ 751 EngineWaterTemp 0;
BA_ "GenSigTimeoutTime_DMPI" SG_ 751 EngineWaterTemp 0;
BA_ "GenSigTimeoutTime_BPCM" SG_ 751 EngineWaterTemp 0;
BA_ "GenSigTimeoutTime_AGSM" SG_ 751 EngineWaterTemp 0;
BA_ "GenSigTimeoutTime_SGW" SG_ 518 MessageCounter_ENGINE5 0;
BA_ "GenSigTimeoutTime_PBWM" SG_ 518 MessageCounter_ENGINE5 0;
BA_ "GenSigTimeoutTime_IDCM" SG_ 518 MessageCounter_ENGINE5 0;
BA_ "GenSigTimeoutTime_ECM" SG_ 518 MessageCounter_ENGINE5 0;
BA_ "GenSigTimeoutTime_DMPI" SG_ 518 MessageCounter_ENGINE5 0;
BA_ "GenSigTimeoutTime_BPCM" SG_ 518 MessageCounter_ENGINE5 0;
BA_ "GenSigTimeoutTime_AGSM" SG_ 518 MessageCounter_ENGINE5 0;
BA_ "GenSigTimeoutTime_SGW" SG_ 518 RPMOverRev_W 0;
BA_ "GenSigTimeoutTime_PBWM" SG_ 518 RPMOverRev_W 0;
BA_ "GenSigTimeoutTime_IDCM" SG_ 518 RPMOverRev_W 0;
BA_ "GenSigTimeoutTime_ECM" SG_ 518 RPMOverRev_W 0;
BA_ "GenSigTimeoutTime_DMPI" SG_ 518 RPMOverRev_W 0;
BA_ "GenSigTimeoutTime_BPCM" SG_ 518 RPMOverRev_W 0;
BA_ "GenSigTimeoutTime_AGSM" SG_ 518 RPMOverRev_W 0;
BA_ "GenSigTimeoutTime_SGW" SG_ 518 CRC_ENGINE5 0;
BA_ "GenSigTimeoutTime_PBWM" SG_ 518 CRC_ENGINE5 0;
BA_ "GenSigTimeoutTime_IDCM" SG_ 518 CRC_ENGINE5 0;
BA_ "GenSigTimeoutTime_ECM" SG_ 518 CRC_ENGINE5 0;
BA_ "GenSigTimeoutTime_DMPI" SG_ 518 CRC_ENGINE5 0;
BA_ "GenSigTimeoutTime_BPCM" SG_ 518 CRC_ENGINE5 0;
BA_ "GenSigTimeoutTime_AGSM" SG_ 518 CRC_ENGINE5 0;
BA_ "GenSigTimeoutTime_SGW" SG_ 518 ECM_CODE_CLR_W 0;
BA_ "GenSigTimeoutTime_PBWM" SG_ 518 ECM_CODE_CLR_W 0;
BA_ "GenSigTimeoutTime_IDCM" SG_ 518 ECM_CODE_CLR_W 0;
BA_ "GenSigTimeoutTime_EVCU2" SG_ 518 ECM_CODE_CLR_W 0;
BA_ "GenSigTimeoutTime_ECM" SG_ 518 ECM_CODE_CLR_W 0;
BA_ "GenSigTimeoutTime_AGSM" SG_ 518 ECM_CODE_CLR_W 0;
BA_ "GenSigTimeoutTime_SGW" SG_ 518 ECM_READINESS_RESET_W 0;
BA_ "GenSigTimeoutTime_PBWM" SG_ 518 ECM_READINESS_RESET_W 0;
BA_ "GenSigTimeoutTime_IDCM" SG_ 518 ECM_READINESS_RESET_W 0;
BA_ "GenSigTimeoutTime_EVCU2" SG_ 518 ECM_READINESS_RESET_W 0;
BA_ "GenSigTimeoutTime_ECM" SG_ 518 ECM_READINESS_RESET_W 0;
BA_ "GenSigTimeoutTime_AGSM" SG_ 518 ECM_READINESS_RESET_W 0;
BA_ "GenSigTimeoutTime_SGW" SG_ 1058 LoadOBD 0;
BA_ "GenSigTimeoutTime_PBWM" SG_ 1058 LoadOBD 0;
BA_ "GenSigTimeoutTime_IDCM" SG_ 1058 LoadOBD 0;
BA_ "GenSigTimeoutTime_EVCU2" SG_ 1058 LoadOBD 0;
BA_ "GenSigTimeoutTime_ECM" SG_ 1058 LoadOBD 0;
BA_ "GenSigTimeoutTime_BPCM" SG_ 1058 LoadOBD 0;
BA_ "GenSigTimeoutTime_AGSM" SG_ 1058 LoadOBD 0;
BA_ "GenSigTimeoutTime_SGW" SG_ 1058 OAT_PT_Est 0;
BA_ "GenSigTimeoutTime_PBWM" SG_ 1058 OAT_PT_Est 0;
BA_ "GenSigTimeoutTime_IDCM" SG_ 1058 OAT_PT_Est 0;
BA_ "GenSigTimeoutTime_ECM" SG_ 1058 OAT_PT_Est 0;
BA_ "GenSigTimeoutTime_DMPI" SG_ 1058 OAT_PT_Est 0;
BA_ "GenSigTimeoutTime_BPCM" SG_ 1058 OAT_PT_Est 0;
BA_ "GenSigTimeoutTime_AGSM" SG_ 1058 OAT_PT_Est 0;
BA_ "GenSigTimeoutTime_SGW" SG_ 1058 OAT_PT_EstV 0;
BA_ "GenSigTimeoutTime_PBWM" SG_ 1058 OAT_PT_EstV 0;
BA_ "GenSigTimeoutTime_IDCM" SG_ 1058 OAT_PT_EstV 0;
BA_ "GenSigTimeoutTime_ECM" SG_ 1058 OAT_PT_EstV 0;
BA_ "GenSigTimeoutTime_DMPI" SG_ 1058 OAT_PT_EstV 0;
BA_ "GenSigTimeoutTime_BPCM" SG_ 1058 OAT_PT_EstV 0;
BA_ "GenSigTimeoutTime_AGSM" SG_ 1058 OAT_PT_EstV 0;
BA_ "GenSigTimeoutTime_SGW" SG_ 1058 CarbWarmUp 0;
BA_ "GenSigTimeoutTime_PBWM" SG_ 1058 CarbWarmUp 0;
BA_ "GenSigTimeoutTime_IDCM" SG_ 1058 CarbWarmUp 0;
BA_ "GenSigTimeoutTime_EVCU2" SG_ 1058 CarbWarmUp 0;
BA_ "GenSigTimeoutTime_ECM" SG_ 1058 CarbWarmUp 0;
BA_ "GenSigTimeoutTime_BPCM" SG_ 1058 CarbWarmUp 0;
BA_ "GenSigTimeoutTime_AGSM" SG_ 1058 CarbWarmUp 0;
BA_ "GenSigTimeoutTime_SGW" SG_ 1058 EngOffTmPT 0;
BA_ "GenSigTimeoutTime_PBWM" SG_ 1058 EngOffTmPT 0;
BA_ "GenSigTimeoutTime_IDCM" SG_ 1058 EngOffTmPT 0;
BA_ "GenSigTimeoutTime_ECM" SG_ 1058 EngOffTmPT 0;
BA_ "GenSigTimeoutTime_DMPI" SG_ 1058 EngOffTmPT 0;
BA_ "GenSigTimeoutTime_BPCM" SG_ 1058 EngOffTmPT 0;
BA_ "GenSigTimeoutTime_AGSM" SG_ 1058 EngOffTmPT 0;
BA_ "GenSigTimeoutTime_SGW" SG_ 1058 EngOffTmPTV 0;
BA_ "GenSigTimeoutTime_PBWM" SG_ 1058 EngOffTmPTV 0;
BA_ "GenSigTimeoutTime_IDCM" SG_ 1058 EngOffTmPTV 0;
BA_ "GenSigTimeoutTime_ECM" SG_ 1058 EngOffTmPTV 0;
BA_ "GenSigTimeoutTime_DMPI" SG_ 1058 EngOffTmPTV 0;
BA_ "GenSigTimeoutTime_BPCM" SG_ 1058 EngOffTmPTV 0;
BA_ "GenSigTimeoutTime_AGSM" SG_ 1058 EngOffTmPTV 0;
BA_ "GenSigStartValue" SG_ 1058 EngOffTmPTV 1;
BA_ "GenSigTimeoutTime_SGW" SG_ 1058 MessageCounter_OBDCONTENTFRAME 0;
BA_ "GenSigTimeoutTime_PBWM" SG_ 1058 MessageCounter_OBDCONTENTFRAME 0;
BA_ "GenSigTimeoutTime_IDCM" SG_ 1058 MessageCounter_OBDCONTENTFRAME 0;
BA_ "GenSigTimeoutTime_ECM" SG_ 1058 MessageCounter_OBDCONTENTFRAME 0;
BA_ "GenSigTimeoutTime_DMPI" SG_ 1058 MessageCounter_OBDCONTENTFRAME 0;
BA_ "GenSigTimeoutTime_AGSM" SG_ 1058 MessageCounter_OBDCONTENTFRAME 0;
BA_ "GenSigTimeoutTime_SGW" SG_ 1058 CRC_OBDCONTENTFRAME 0;
BA_ "GenSigTimeoutTime_PBWM" SG_ 1058 CRC_OBDCONTENTFRAME 0;
BA_ "GenSigTimeoutTime_IDCM" SG_ 1058 CRC_OBDCONTENTFRAME 0;
BA_ "GenSigTimeoutTime_ECM" SG_ 1058 CRC_OBDCONTENTFRAME 0;
BA_ "GenSigTimeoutTime_DMPI" SG_ 1058 CRC_OBDCONTENTFRAME 0;
BA_ "GenSigTimeoutTime_AGSM" SG_ 1058 CRC_OBDCONTENTFRAME 0;
BA_ "GenSigTimeoutTime_SGW" SG_ 2654486640 CBV_bit0_RepeatMessageRequestBit 0;
BA_ "GenSigTimeoutTime_PBWM" SG_ 2654486640 CBV_bit0_RepeatMessageRequestBit 0;
BA_ "GenSigTimeoutTime_IDCM" SG_ 2654486640 CBV_bit0_RepeatMessageRequestBit 0;
BA_ "GenSigTimeoutTime_EVCU2" SG_ 2654486640 CBV_bit0_RepeatMessageRequestBit 0;
BA_ "GenSigTimeoutTime_ECM" SG_ 2654486640 CBV_bit0_RepeatMessageRequestBit 0;
BA_ "GenSigTimeoutTime_DMPI" SG_ 2654486640 CBV_bit0_RepeatMessageRequestBit 0;
BA_ "GenSigTimeoutTime_BPCM" SG_ 2654486640 CBV_bit0_RepeatMessageRequestBit 0;
BA_ "GenSigTimeoutTime_AGSM" SG_ 2654486640 CBV_bit0_RepeatMessageRequestBit 0;
BA_ "GenSigTimeoutTime_SGW" SG_ 2654486640 CBV_bit1 0;
BA_ "GenSigTimeoutTime_PBWM" SG_ 2654486640 CBV_bit1 0;
BA_ "GenSigTimeoutTime_IDCM" SG_ 2654486640 CBV_bit1 0;
BA_ "GenSigTimeoutTime_EVCU2" SG_ 2654486640 CBV_bit1 0;
BA_ "GenSigTimeoutTime_ECM" SG_ 2654486640 CBV_bit1 0;
BA_ "GenSigTimeoutTime_DMPI" SG_ 2654486640 CBV_bit1 0;
BA_ "GenSigTimeoutTime_BPCM" SG_ 2654486640 CBV_bit1 0;
BA_ "GenSigTimeoutTime_AGSM" SG_ 2654486640 CBV_bit1 0;
BA_ "GenSigTimeoutTime_SGW" SG_ 2654486640 CBV_bit4_ActiveWakeupBit 0;
BA_ "GenSigTimeoutTime_PBWM" SG_ 2654486640 CBV_bit4_ActiveWakeupBit 0;
BA_ "GenSigTimeoutTime_IDCM" SG_ 2654486640 CBV_bit4_ActiveWakeupBit 0;
BA_ "GenSigTimeoutTime_EVCU2" SG_ 2654486640 CBV_bit4_ActiveWakeupBit 0;
BA_ "GenSigTimeoutTime_ECM" SG_ 2654486640 CBV_bit4_ActiveWakeupBit 0;
BA_ "GenSigTimeoutTime_DMPI" SG_ 2654486640 CBV_bit4_ActiveWakeupBit 0;
BA_ "GenSigTimeoutTime_BPCM" SG_ 2654486640 CBV_bit4_ActiveWakeupBit 0;
BA_ "GenSigTimeoutTime_AGSM" SG_ 2654486640 CBV_bit4_ActiveWakeupBit 0;
BA_ "GenSigTimeoutTime_SGW" SG_ 2654486640 CBV_bit3_NMCoordinatorBit 0;
BA_ "GenSigTimeoutTime_PBWM" SG_ 2654486640 CBV_bit3_NMCoordinatorBit 0;
BA_ "GenSigTimeoutTime_IDCM" SG_ 2654486640 CBV_bit3_NMCoordinatorBit 0;
BA_ "GenSigTimeoutTime_EVCU2" SG_ 2654486640 CBV_bit3_NMCoordinatorBit 0;
BA_ "GenSigTimeoutTime_ECM" SG_ 2654486640 CBV_bit3_NMCoordinatorBit 0;
BA_ "GenSigTimeoutTime_DMPI" SG_ 2654486640 CBV_bit3_NMCoordinatorBit 0;
BA_ "GenSigTimeoutTime_BPCM" SG_ 2654486640 CBV_bit3_NMCoordinatorBit 0;
BA_ "GenSigTimeoutTime_AGSM" SG_ 2654486640 CBV_bit3_NMCoordinatorBit 0;
BA_ "GenSigTimeoutTime_SGW" SG_ 2654486640 CBV_bit2 0;
BA_ "GenSigTimeoutTime_PBWM" SG_ 2654486640 CBV_bit2 0;
BA_ "GenSigTimeoutTime_IDCM" SG_ 2654486640 CBV_bit2 0;
BA_ "GenSigTimeoutTime_EVCU2" SG_ 2654486640 CBV_bit2 0;
BA_ "GenSigTimeoutTime_ECM" SG_ 2654486640 CBV_bit2 0;
BA_ "GenSigTimeoutTime_DMPI" SG_ 2654486640 CBV_bit2 0;
BA_ "GenSigTimeoutTime_BPCM" SG_ 2654486640 CBV_bit2 0;
BA_ "GenSigTimeoutTime_AGSM" SG_ 2654486640 CBV_bit2 0;
BA_ "GenSigTimeoutTime_SGW" SG_ 2654486640 SourceNodeIdentifier 0;
BA_ "GenSigTimeoutTime_PBWM" SG_ 2654486640 SourceNodeIdentifier 0;
BA_ "GenSigTimeoutTime_IDCM" SG_ 2654486640 SourceNodeIdentifier 0;
BA_ "GenSigTimeoutTime_EVCU2" SG_ 2654486640 SourceNodeIdentifier 0;
BA_ "GenSigTimeoutTime_ECM" SG_ 2654486640 SourceNodeIdentifier 0;
BA_ "GenSigTimeoutTime_DMPI" SG_ 2654486640 SourceNodeIdentifier 0;
BA_ "GenSigTimeoutTime_BPCM" SG_ 2654486640 SourceNodeIdentifier 0;
BA_ "GenSigTimeoutTime_AGSM" SG_ 2654486640 SourceNodeIdentifier 0;
BA_ "GenSigTimeoutTime_SGW" SG_ 2654486640 CBV_bit7 0;
BA_ "GenSigTimeoutTime_PBWM" SG_ 2654486640 CBV_bit7 0;
BA_ "GenSigTimeoutTime_IDCM" SG_ 2654486640 CBV_bit7 0;
BA_ "GenSigTimeoutTime_EVCU2" SG_ 2654486640 CBV_bit7 0;
BA_ "GenSigTimeoutTime_ECM" SG_ 2654486640 CBV_bit7 0;
BA_ "GenSigTimeoutTime_DMPI" SG_ 2654486640 CBV_bit7 0;
BA_ "GenSigTimeoutTime_BPCM" SG_ 2654486640 CBV_bit7 0;
BA_ "GenSigTimeoutTime_AGSM" SG_ 2654486640 CBV_bit7 0;
BA_ "GenSigTimeoutTime_SGW" SG_ 2654486640 CBV_bit6_PartialNtwInfBit 0;
BA_ "GenSigTimeoutTime_PBWM" SG_ 2654486640 CBV_bit6_PartialNtwInfBit 0;
BA_ "GenSigTimeoutTime_IDCM" SG_ 2654486640 CBV_bit6_PartialNtwInfBit 0;
BA_ "GenSigTimeoutTime_EVCU2" SG_ 2654486640 CBV_bit6_PartialNtwInfBit 0;
BA_ "GenSigTimeoutTime_ECM" SG_ 2654486640 CBV_bit6_PartialNtwInfBit 0;
BA_ "GenSigTimeoutTime_DMPI" SG_ 2654486640 CBV_bit6_PartialNtwInfBit 0;
BA_ "GenSigTimeoutTime_BPCM" SG_ 2654486640 CBV_bit6_PartialNtwInfBit 0;
BA_ "GenSigTimeoutTime_AGSM" SG_ 2654486640 CBV_bit6_PartialNtwInfBit 0;
BA_ "GenSigTimeoutTime_SGW" SG_ 2654486640 CBV_bit5 0;
BA_ "GenSigTimeoutTime_PBWM" SG_ 2654486640 CBV_bit5 0;
BA_ "GenSigTimeoutTime_IDCM" SG_ 2654486640 CBV_bit5 0;
BA_ "GenSigTimeoutTime_EVCU2" SG_ 2654486640 CBV_bit5 0;
BA_ "GenSigTimeoutTime_ECM" SG_ 2654486640 CBV_bit5 0;
BA_ "GenSigTimeoutTime_DMPI" SG_ 2654486640 CBV_bit5 0;
BA_ "GenSigTimeoutTime_BPCM" SG_ 2654486640 CBV_bit5 0;
BA_ "GenSigTimeoutTime_AGSM" SG_ 2654486640 CBV_bit5 0;
BA_ "GenSigTimeoutTime_SGW" SG_ 2654486529 CBV_bit4_ActiveWakeupBit 0;
BA_ "GenSigTimeoutTime_PBWM" SG_ 2654486529 CBV_bit4_ActiveWakeupBit 0;
BA_ "GenSigTimeoutTime_IDCM" SG_ 2654486529 CBV_bit4_ActiveWakeupBit 0;
BA_ "GenSigTimeoutTime_EVCU2" SG_ 2654486529 CBV_bit4_ActiveWakeupBit 0;
BA_ "GenSigTimeoutTime_ECM" SG_ 2654486529 CBV_bit4_ActiveWakeupBit 0;
BA_ "GenSigTimeoutTime_DMPI" SG_ 2654486529 CBV_bit4_ActiveWakeupBit 0;
BA_ "GenSigTimeoutTime_BPCM" SG_ 2654486529 CBV_bit4_ActiveWakeupBit 0;
BA_ "GenSigTimeoutTime_AGSM" SG_ 2654486529 CBV_bit4_ActiveWakeupBit 0;
BA_ "GenSigTimeoutTime_SGW" SG_ 2654486529 CBV_bit5 0;
BA_ "GenSigTimeoutTime_PBWM" SG_ 2654486529 CBV_bit5 0;
BA_ "GenSigTimeoutTime_IDCM" SG_ 2654486529 CBV_bit5 0;
BA_ "GenSigTimeoutTime_EVCU2" SG_ 2654486529 CBV_bit5 0;
BA_ "GenSigTimeoutTime_ECM" SG_ 2654486529 CBV_bit5 0;
BA_ "GenSigTimeoutTime_DMPI" SG_ 2654486529 CBV_bit5 0;
BA_ "GenSigTimeoutTime_BPCM" SG_ 2654486529 CBV_bit5 0;
BA_ "GenSigTimeoutTime_AGSM" SG_ 2654486529 CBV_bit5 0;
BA_ "GenSigTimeoutTime_SGW" SG_ 2654486529 CBV_bit7 0;
BA_ "GenSigTimeoutTime_PBWM" SG_ 2654486529 CBV_bit7 0;
BA_ "GenSigTimeoutTime_IDCM" SG_ 2654486529 CBV_bit7 0;
BA_ "GenSigTimeoutTime_EVCU2" SG_ 2654486529 CBV_bit7 0;
BA_ "GenSigTimeoutTime_ECM" SG_ 2654486529 CBV_bit7 0;
BA_ "GenSigTimeoutTime_DMPI" SG_ 2654486529 CBV_bit7 0;
BA_ "GenSigTimeoutTime_BPCM" SG_ 2654486529 CBV_bit7 0;
BA_ "GenSigTimeoutTime_AGSM" SG_ 2654486529 CBV_bit7 0;
BA_ "GenSigTimeoutTime_SGW" SG_ 2654486529 CBV_bit6_PartialNtwInfBit 0;
BA_ "GenSigTimeoutTime_PBWM" SG_ 2654486529 CBV_bit6_PartialNtwInfBit 0;
BA_ "GenSigTimeoutTime_IDCM" SG_ 2654486529 CBV_bit6_PartialNtwInfBit 0;
BA_ "GenSigTimeoutTime_EVCU2" SG_ 2654486529 CBV_bit6_PartialNtwInfBit 0;
BA_ "GenSigTimeoutTime_ECM" SG_ 2654486529 CBV_bit6_PartialNtwInfBit 0;
BA_ "GenSigTimeoutTime_DMPI" SG_ 2654486529 CBV_bit6_PartialNtwInfBit 0;
BA_ "GenSigTimeoutTime_BPCM" SG_ 2654486529 CBV_bit6_PartialNtwInfBit 0;
BA_ "GenSigTimeoutTime_AGSM" SG_ 2654486529 CBV_bit6_PartialNtwInfBit 0;
BA_ "GenSigTimeoutTime_SGW" SG_ 2654486529 SourceNodeIdentifier 0;
BA_ "GenSigTimeoutTime_PBWM" SG_ 2654486529 SourceNodeIdentifier 0;
BA_ "GenSigTimeoutTime_IDCM" SG_ 2654486529 SourceNodeIdentifier 0;
BA_ "GenSigTimeoutTime_EVCU2" SG_ 2654486529 SourceNodeIdentifier 0;
BA_ "GenSigTimeoutTime_ECM" SG_ 2654486529 SourceNodeIdentifier 0;
BA_ "GenSigTimeoutTime_DMPI" SG_ 2654486529 SourceNodeIdentifier 0;
BA_ "GenSigTimeoutTime_BPCM" SG_ 2654486529 SourceNodeIdentifier 0;
BA_ "GenSigTimeoutTime_AGSM" SG_ 2654486529 SourceNodeIdentifier 0;
BA_ "GenSigTimeoutTime_SGW" SG_ 2654486529 CBV_bit2 0;
BA_ "GenSigTimeoutTime_PBWM" SG_ 2654486529 CBV_bit2 0;
BA_ "GenSigTimeoutTime_IDCM" SG_ 2654486529 CBV_bit2 0;
BA_ "GenSigTimeoutTime_EVCU2" SG_ 2654486529 CBV_bit2 0;
BA_ "GenSigTimeoutTime_ECM" SG_ 2654486529 CBV_bit2 0;
BA_ "GenSigTimeoutTime_DMPI" SG_ 2654486529 CBV_bit2 0;
BA_ "GenSigTimeoutTime_BPCM" SG_ 2654486529 CBV_bit2 0;
BA_ "GenSigTimeoutTime_AGSM" SG_ 2654486529 CBV_bit2 0;
BA_ "GenSigTimeoutTime_SGW" SG_ 2654486529 CBV_bit3_NMCoordinatorBit 0;
BA_ "GenSigTimeoutTime_PBWM" SG_ 2654486529 CBV_bit3_NMCoordinatorBit 0;
BA_ "GenSigTimeoutTime_IDCM" SG_ 2654486529 CBV_bit3_NMCoordinatorBit 0;
BA_ "GenSigTimeoutTime_EVCU2" SG_ 2654486529 CBV_bit3_NMCoordinatorBit 0;
BA_ "GenSigTimeoutTime_ECM" SG_ 2654486529 CBV_bit3_NMCoordinatorBit 0;
BA_ "GenSigTimeoutTime_DMPI" SG_ 2654486529 CBV_bit3_NMCoordinatorBit 0;
BA_ "GenSigTimeoutTime_BPCM" SG_ 2654486529 CBV_bit3_NMCoordinatorBit 0;
BA_ "GenSigTimeoutTime_AGSM" SG_ 2654486529 CBV_bit3_NMCoordinatorBit 0;
BA_ "GenSigTimeoutTime_SGW" SG_ 2654486529 CBV_bit1 0;
BA_ "GenSigTimeoutTime_PBWM" SG_ 2654486529 CBV_bit1 0;
BA_ "GenSigTimeoutTime_IDCM" SG_ 2654486529 CBV_bit1 0;
BA_ "GenSigTimeoutTime_EVCU2" SG_ 2654486529 CBV_bit1 0;
BA_ "GenSigTimeoutTime_ECM" SG_ 2654486529 CBV_bit1 0;
BA_ "GenSigTimeoutTime_DMPI" SG_ 2654486529 CBV_bit1 0;
BA_ "GenSigTimeoutTime_BPCM" SG_ 2654486529 CBV_bit1 0;
BA_ "GenSigTimeoutTime_AGSM" SG_ 2654486529 CBV_bit1 0;
BA_ "GenSigTimeoutTime_SGW" SG_ 2654486529 CBV_bit0_RepeatMessageRequestBit 0;
BA_ "GenSigTimeoutTime_PBWM" SG_ 2654486529 CBV_bit0_RepeatMessageRequestBit 0;
BA_ "GenSigTimeoutTime_IDCM" SG_ 2654486529 CBV_bit0_RepeatMessageRequestBit 0;
BA_ "GenSigTimeoutTime_EVCU2" SG_ 2654486529 CBV_bit0_RepeatMessageRequestBit 0;
BA_ "GenSigTimeoutTime_ECM" SG_ 2654486529 CBV_bit0_RepeatMessageRequestBit 0;
BA_ "GenSigTimeoutTime_DMPI" SG_ 2654486529 CBV_bit0_RepeatMessageRequestBit 0;
BA_ "GenSigTimeoutTime_BPCM" SG_ 2654486529 CBV_bit0_RepeatMessageRequestBit 0;
BA_ "GenSigTimeoutTime_AGSM" SG_ 2654486529 CBV_bit0_RepeatMessageRequestBit 0;
BA_ "GenSigTimeoutTime_PBWM" SG_ 1835 HVBatCellVoltage_Cell026 0;
BA_ "GenSigTimeoutTime_IDCM" SG_ 1835 HVBatCellVoltage_Cell026 0;
BA_ "GenSigTimeoutTime_EVCU2" SG_ 1835 HVBatCellVoltage_Cell026 0;
BA_ "GenSigTimeoutTime_ECM" SG_ 1835 HVBatCellVoltage_Cell026 0;
BA_ "GenSigTimeoutTime_DMPI" SG_ 1835 HVBatCellVoltage_Cell026 0;
BA_ "GenSigTimeoutTime_BPCM" SG_ 1835 HVBatCellVoltage_Cell026 0;
BA_ "GenSigTimeoutTime_AGSM" SG_ 1835 HVBatCellVoltage_Cell026 0;
BA_ "GenSigTimeoutTime_PBWM" SG_ 1835 HVBatCellVoltage_Cell027 0;
BA_ "GenSigTimeoutTime_IDCM" SG_ 1835 HVBatCellVoltage_Cell027 0;
BA_ "GenSigTimeoutTime_EVCU2" SG_ 1835 HVBatCellVoltage_Cell027 0;
BA_ "GenSigTimeoutTime_ECM" SG_ 1835 HVBatCellVoltage_Cell027 0;
BA_ "GenSigTimeoutTime_DMPI" SG_ 1835 HVBatCellVoltage_Cell027 0;
BA_ "GenSigTimeoutTime_BPCM" SG_ 1835 HVBatCellVoltage_Cell027 0;
BA_ "GenSigTimeoutTime_AGSM" SG_ 1835 HVBatCellVoltage_Cell027 0;
BA_ "GenSigTimeoutTime_PBWM" SG_ 1835 HVBatCellVoltage_Cell002 0;
BA_ "GenSigTimeoutTime_IDCM" SG_ 1835 HVBatCellVoltage_Cell002 0;
BA_ "GenSigTimeoutTime_EVCU2" SG_ 1835 HVBatCellVoltage_Cell002 0;
BA_ "GenSigTimeoutTime_ECM" SG_ 1835 HVBatCellVoltage_Cell002 0;
BA_ "GenSigTimeoutTime_DMPI" SG_ 1835 HVBatCellVoltage_Cell002 0;
BA_ "GenSigTimeoutTime_BPCM" SG_ 1835 HVBatCellVoltage_Cell002 0;
BA_ "GenSigTimeoutTime_AGSM" SG_ 1835 HVBatCellVoltage_Cell002 0;
BA_ "GenSigTimeoutTime_PBWM" SG_ 1835 HVBatCellVoltage_Cell003 0;
BA_ "GenSigTimeoutTime_IDCM" SG_ 1835 HVBatCellVoltage_Cell003 0;
BA_ "GenSigTimeoutTime_EVCU2" SG_ 1835 HVBatCellVoltage_Cell003 0;
BA_ "GenSigTimeoutTime_ECM" SG_ 1835 HVBatCellVoltage_Cell003 0;
BA_ "GenSigTimeoutTime_DMPI" SG_ 1835 HVBatCellVoltage_Cell003 0;
BA_ "GenSigTimeoutTime_BPCM" SG_ 1835 HVBatCellVoltage_Cell003 0;
BA_ "GenSigTimeoutTime_AGSM" SG_ 1835 HVBatCellVoltage_Cell003 0;
BA_ "GenSigTimeoutTime_PBWM" SG_ 1835 HVBatCellVoltage_Cell004 0;
BA_ "GenSigTimeoutTime_IDCM" SG_ 1835 HVBatCellVoltage_Cell004 0;
BA_ "GenSigTimeoutTime_EVCU2" SG_ 1835 HVBatCellVoltage_Cell004 0;
BA_ "GenSigTimeoutTime_ECM" SG_ 1835 HVBatCellVoltage_Cell004 0;
BA_ "GenSigTimeoutTime_DMPI" SG_ 1835 HVBatCellVoltage_Cell004 0;
BA_ "GenSigTimeoutTime_BPCM" SG_ 1835 HVBatCellVoltage_Cell004 0;
BA_ "GenSigTimeoutTime_AGSM" SG_ 1835 HVBatCellVoltage_Cell004 0;
BA_ "GenSigTimeoutTime_PBWM" SG_ 1835 HVBatCellVoltage_Cell005 0;
BA_ "GenSigTimeoutTime_IDCM" SG_ 1835 HVBatCellVoltage_Cell005 0;
BA_ "GenSigTimeoutTime_EVCU2" SG_ 1835 HVBatCellVoltage_Cell005 0;
BA_ "GenSigTimeoutTime_ECM" SG_ 1835 HVBatCellVoltage_Cell005 0;
BA_ "GenSigTimeoutTime_DMPI" SG_ 1835 HVBatCellVoltage_Cell005 0;
BA_ "GenSigTimeoutTime_BPCM" SG_ 1835 HVBatCellVoltage_Cell005 0;
BA_ "GenSigTimeoutTime_AGSM" SG_ 1835 HVBatCellVoltage_Cell005 0;
BA_ "GenSigTimeoutTime_PBWM" SG_ 1835 HVBatCellVoltage_Cell006 0;
BA_ "GenSigTimeoutTime_IDCM" SG_ 1835 HVBatCellVoltage_Cell006 0;
BA_ "GenSigTimeoutTime_EVCU2" SG_ 1835 HVBatCellVoltage_Cell006 0;
BA_ "GenSigTimeoutTime_ECM" SG_ 1835 HVBatCellVoltage_Cell006 0;
BA_ "GenSigTimeoutTime_DMPI" SG_ 1835 HVBatCellVoltage_Cell006 0;
BA_ "GenSigTimeoutTime_BPCM" SG_ 1835 HVBatCellVoltage_Cell006 0;
BA_ "GenSigTimeoutTime_AGSM" SG_ 1835 HVBatCellVoltage_Cell006 0;
BA_ "GenSigTimeoutTime_PBWM" SG_ 1835 HVBatCellVoltage_Cell007 0;
BA_ "GenSigTimeoutTime_IDCM" SG_ 1835 HVBatCellVoltage_Cell007 0;
BA_ "GenSigTimeoutTime_EVCU2" SG_ 1835 HVBatCellVoltage_Cell007 0;
BA_ "GenSigTimeoutTime_ECM" SG_ 1835 HVBatCellVoltage_Cell007 0;
BA_ "GenSigTimeoutTime_DMPI" SG_ 1835 HVBatCellVoltage_Cell007 0;
BA_ "GenSigTimeoutTime_BPCM" SG_ 1835 HVBatCellVoltage_Cell007 0;
BA_ "GenSigTimeoutTime_AGSM" SG_ 1835 HVBatCellVoltage_Cell007 0;
BA_ "GenSigTimeoutTime_PBWM" SG_ 1835 HVBatCellVoltage_Cell008 0;
BA_ "GenSigTimeoutTime_IDCM" SG_ 1835 HVBatCellVoltage_Cell008 0;
BA_ "GenSigTimeoutTime_EVCU2" SG_ 1835 HVBatCellVoltage_Cell008 0;
BA_ "GenSigTimeoutTime_ECM" SG_ 1835 HVBatCellVoltage_Cell008 0;
BA_ "GenSigTimeoutTime_DMPI" SG_ 1835 HVBatCellVoltage_Cell008 0;
BA_ "GenSigTimeoutTime_BPCM" SG_ 1835 HVBatCellVoltage_Cell008 0;
BA_ "GenSigTimeoutTime_AGSM" SG_ 1835 HVBatCellVoltage_Cell008 0;
BA_ "GenSigTimeoutTime_PBWM" SG_ 1835 HVBatCellVoltage_Cell009 0;
BA_ "GenSigTimeoutTime_IDCM" SG_ 1835 HVBatCellVoltage_Cell009 0;
BA_ "GenSigTimeoutTime_EVCU2" SG_ 1835 HVBatCellVoltage_Cell009 0;
BA_ "GenSigTimeoutTime_ECM" SG_ 1835 HVBatCellVoltage_Cell009 0;
BA_ "GenSigTimeoutTime_DMPI" SG_ 1835 HVBatCellVoltage_Cell009 0;
BA_ "GenSigTimeoutTime_BPCM" SG_ 1835 HVBatCellVoltage_Cell009 0;
BA_ "GenSigTimeoutTime_AGSM" SG_ 1835 HVBatCellVoltage_Cell009 0;
BA_ "GenSigTimeoutTime_PBWM" SG_ 1835 HVBatCellVoltage_Cell010 0;
BA_ "GenSigTimeoutTime_IDCM" SG_ 1835 HVBatCellVoltage_Cell010 0;
BA_ "GenSigTimeoutTime_EVCU2" SG_ 1835 HVBatCellVoltage_Cell010 0;
BA_ "GenSigTimeoutTime_ECM" SG_ 1835 HVBatCellVoltage_Cell010 0;
BA_ "GenSigTimeoutTime_DMPI" SG_ 1835 HVBatCellVoltage_Cell010 0;
BA_ "GenSigTimeoutTime_BPCM" SG_ 1835 HVBatCellVoltage_Cell010 0;
BA_ "GenSigTimeoutTime_AGSM" SG_ 1835 HVBatCellVoltage_Cell010 0;
BA_ "GenSigTimeoutTime_PBWM" SG_ 1835 HVBatCellVoltage_Cell011 0;
BA_ "GenSigTimeoutTime_IDCM" SG_ 1835 HVBatCellVoltage_Cell011 0;
BA_ "GenSigTimeoutTime_EVCU2" SG_ 1835 HVBatCellVoltage_Cell011 0;
BA_ "GenSigTimeoutTime_ECM" SG_ 1835 HVBatCellVoltage_Cell011 0;
BA_ "GenSigTimeoutTime_DMPI" SG_ 1835 HVBatCellVoltage_Cell011 0;
BA_ "GenSigTimeoutTime_BPCM" SG_ 1835 HVBatCellVoltage_Cell011 0;
BA_ "GenSigTimeoutTime_AGSM" SG_ 1835 HVBatCellVoltage_Cell011 0;
BA_ "GenSigTimeoutTime_PBWM" SG_ 1835 HVBatCellVoltage_Cell012 0;
BA_ "GenSigTimeoutTime_IDCM" SG_ 1835 HVBatCellVoltage_Cell012 0;
BA_ "GenSigTimeoutTime_EVCU2" SG_ 1835 HVBatCellVoltage_Cell012 0;
BA_ "GenSigTimeoutTime_ECM" SG_ 1835 HVBatCellVoltage_Cell012 0;
BA_ "GenSigTimeoutTime_DMPI" SG_ 1835 HVBatCellVoltage_Cell012 0;
BA_ "GenSigTimeoutTime_BPCM" SG_ 1835 HVBatCellVoltage_Cell012 0;
BA_ "GenSigTimeoutTime_AGSM" SG_ 1835 HVBatCellVoltage_Cell012 0;
BA_ "GenSigTimeoutTime_PBWM" SG_ 1835 HVBatCellVoltage_Cell013 0;
BA_ "GenSigTimeoutTime_IDCM" SG_ 1835 HVBatCellVoltage_Cell013 0;
BA_ "GenSigTimeoutTime_EVCU2" SG_ 1835 HVBatCellVoltage_Cell013 0;
BA_ "GenSigTimeoutTime_ECM" SG_ 1835 HVBatCellVoltage_Cell013 0;
BA_ "GenSigTimeoutTime_DMPI" SG_ 1835 HVBatCellVoltage_Cell013 0;
BA_ "GenSigTimeoutTime_BPCM" SG_ 1835 HVBatCellVoltage_Cell013 0;
BA_ "GenSigTimeoutTime_AGSM" SG_ 1835 HVBatCellVoltage_Cell013 0;
BA_ "GenSigTimeoutTime_PBWM" SG_ 1835 HVBatCellVoltage_Cell014 0;
BA_ "GenSigTimeoutTime_IDCM" SG_ 1835 HVBatCellVoltage_Cell014 0;
BA_ "GenSigTimeoutTime_EVCU2" SG_ 1835 HVBatCellVoltage_Cell014 0;
BA_ "GenSigTimeoutTime_ECM" SG_ 1835 HVBatCellVoltage_Cell014 0;
BA_ "GenSigTimeoutTime_DMPI" SG_ 1835 HVBatCellVoltage_Cell014 0;
BA_ "GenSigTimeoutTime_BPCM" SG_ 1835 HVBatCellVoltage_Cell014 0;
BA_ "GenSigTimeoutTime_AGSM" SG_ 1835 HVBatCellVoltage_Cell014 0;
BA_ "GenSigTimeoutTime_PBWM" SG_ 1835 HVBatCellVoltage_Cell015 0;
BA_ "GenSigTimeoutTime_IDCM" SG_ 1835 HVBatCellVoltage_Cell015 0;
BA_ "GenSigTimeoutTime_EVCU2" SG_ 1835 HVBatCellVoltage_Cell015 0;
BA_ "GenSigTimeoutTime_ECM" SG_ 1835 HVBatCellVoltage_Cell015 0;
BA_ "GenSigTimeoutTime_DMPI" SG_ 1835 HVBatCellVoltage_Cell015 0;
BA_ "GenSigTimeoutTime_BPCM" SG_ 1835 HVBatCellVoltage_Cell015 0;
BA_ "GenSigTimeoutTime_AGSM" SG_ 1835 HVBatCellVoltage_Cell015 0;
BA_ "GenSigTimeoutTime_PBWM" SG_ 1835 HVBatCellVoltage_Cell016 0;
BA_ "GenSigTimeoutTime_IDCM" SG_ 1835 HVBatCellVoltage_Cell016 0;
BA_ "GenSigTimeoutTime_EVCU2" SG_ 1835 HVBatCellVoltage_Cell016 0;
BA_ "GenSigTimeoutTime_ECM" SG_ 1835 HVBatCellVoltage_Cell016 0;
BA_ "GenSigTimeoutTime_DMPI" SG_ 1835 HVBatCellVoltage_Cell016 0;
BA_ "GenSigTimeoutTime_BPCM" SG_ 1835 HVBatCellVoltage_Cell016 0;
BA_ "GenSigTimeoutTime_AGSM" SG_ 1835 HVBatCellVoltage_Cell016 0;
BA_ "GenSigTimeoutTime_PBWM" SG_ 1835 HVBatCellVoltage_Cell017 0;
BA_ "GenSigTimeoutTime_IDCM" SG_ 1835 HVBatCellVoltage_Cell017 0;
BA_ "GenSigTimeoutTime_EVCU2" SG_ 1835 HVBatCellVoltage_Cell017 0;
BA_ "GenSigTimeoutTime_ECM" SG_ 1835 HVBatCellVoltage_Cell017 0;
BA_ "GenSigTimeoutTime_DMPI" SG_ 1835 HVBatCellVoltage_Cell017 0;
BA_ "GenSigTimeoutTime_BPCM" SG_ 1835 HVBatCellVoltage_Cell017 0;
BA_ "GenSigTimeoutTime_AGSM" SG_ 1835 HVBatCellVoltage_Cell017 0;
BA_ "GenSigTimeoutTime_PBWM" SG_ 1835 HVBatCellVoltage_Cell018 0;
BA_ "GenSigTimeoutTime_IDCM" SG_ 1835 HVBatCellVoltage_Cell018 0;
BA_ "GenSigTimeoutTime_EVCU2" SG_ 1835 HVBatCellVoltage_Cell018 0;
BA_ "GenSigTimeoutTime_ECM" SG_ 1835 HVBatCellVoltage_Cell018 0;
BA_ "GenSigTimeoutTime_DMPI" SG_ 1835 HVBatCellVoltage_Cell018 0;
BA_ "GenSigTimeoutTime_BPCM" SG_ 1835 HVBatCellVoltage_Cell018 0;
BA_ "GenSigTimeoutTime_AGSM" SG_ 1835 HVBatCellVoltage_Cell018 0;
BA_ "GenSigTimeoutTime_PBWM" SG_ 1835 HVBatCellVoltage_Cell019 0;
BA_ "GenSigTimeoutTime_IDCM" SG_ 1835 HVBatCellVoltage_Cell019 0;
BA_ "GenSigTimeoutTime_EVCU2" SG_ 1835 HVBatCellVoltage_Cell019 0;
BA_ "GenSigTimeoutTime_ECM" SG_ 1835 HVBatCellVoltage_Cell019 0;
BA_ "GenSigTimeoutTime_DMPI" SG_ 1835 HVBatCellVoltage_Cell019 0;
BA_ "GenSigTimeoutTime_BPCM" SG_ 1835 HVBatCellVoltage_Cell019 0;
BA_ "GenSigTimeoutTime_AGSM" SG_ 1835 HVBatCellVoltage_Cell019 0;
BA_ "GenSigTimeoutTime_PBWM" SG_ 1835 HVBatCellVoltage_Cell020 0;
BA_ "GenSigTimeoutTime_IDCM" SG_ 1835 HVBatCellVoltage_Cell020 0;
BA_ "GenSigTimeoutTime_EVCU2" SG_ 1835 HVBatCellVoltage_Cell020 0;
BA_ "GenSigTimeoutTime_ECM" SG_ 1835 HVBatCellVoltage_Cell020 0;
BA_ "GenSigTimeoutTime_DMPI" SG_ 1835 HVBatCellVoltage_Cell020 0;
BA_ "GenSigTimeoutTime_BPCM" SG_ 1835 HVBatCellVoltage_Cell020 0;
BA_ "GenSigTimeoutTime_AGSM" SG_ 1835 HVBatCellVoltage_Cell020 0;
BA_ "GenSigTimeoutTime_PBWM" SG_ 1835 HVBatCellVoltage_Cell021 0;
BA_ "GenSigTimeoutTime_IDCM" SG_ 1835 HVBatCellVoltage_Cell021 0;
BA_ "GenSigTimeoutTime_EVCU2" SG_ 1835 HVBatCellVoltage_Cell021 0;
BA_ "GenSigTimeoutTime_ECM" SG_ 1835 HVBatCellVoltage_Cell021 0;
BA_ "GenSigTimeoutTime_DMPI" SG_ 1835 HVBatCellVoltage_Cell021 0;
BA_ "GenSigTimeoutTime_BPCM" SG_ 1835 HVBatCellVoltage_Cell021 0;
BA_ "GenSigTimeoutTime_AGSM" SG_ 1835 HVBatCellVoltage_Cell021 0;
BA_ "GenSigTimeoutTime_PBWM" SG_ 1835 HVBatCellVoltage_Cell022 0;
BA_ "GenSigTimeoutTime_IDCM" SG_ 1835 HVBatCellVoltage_Cell022 0;
BA_ "GenSigTimeoutTime_EVCU2" SG_ 1835 HVBatCellVoltage_Cell022 0;
BA_ "GenSigTimeoutTime_ECM" SG_ 1835 HVBatCellVoltage_Cell022 0;
BA_ "GenSigTimeoutTime_DMPI" SG_ 1835 HVBatCellVoltage_Cell022 0;
BA_ "GenSigTimeoutTime_BPCM" SG_ 1835 HVBatCellVoltage_Cell022 0;
BA_ "GenSigTimeoutTime_AGSM" SG_ 1835 HVBatCellVoltage_Cell022 0;
BA_ "GenSigTimeoutTime_PBWM" SG_ 1835 HVBatCellVoltage_Cell023 0;
BA_ "GenSigTimeoutTime_IDCM" SG_ 1835 HVBatCellVoltage_Cell023 0;
BA_ "GenSigTimeoutTime_EVCU2" SG_ 1835 HVBatCellVoltage_Cell023 0;
BA_ "GenSigTimeoutTime_ECM" SG_ 1835 HVBatCellVoltage_Cell023 0;
BA_ "GenSigTimeoutTime_DMPI" SG_ 1835 HVBatCellVoltage_Cell023 0;
BA_ "GenSigTimeoutTime_BPCM" SG_ 1835 HVBatCellVoltage_Cell023 0;
BA_ "GenSigTimeoutTime_AGSM" SG_ 1835 HVBatCellVoltage_Cell023 0;
BA_ "GenSigTimeoutTime_PBWM" SG_ 1835 HVBatCellVoltage_Cell024 0;
BA_ "GenSigTimeoutTime_IDCM" SG_ 1835 HVBatCellVoltage_Cell024 0;
BA_ "GenSigTimeoutTime_EVCU2" SG_ 1835 HVBatCellVoltage_Cell024 0;
BA_ "GenSigTimeoutTime_ECM" SG_ 1835 HVBatCellVoltage_Cell024 0;
BA_ "GenSigTimeoutTime_DMPI" SG_ 1835 HVBatCellVoltage_Cell024 0;
BA_ "GenSigTimeoutTime_BPCM" SG_ 1835 HVBatCellVoltage_Cell024 0;
BA_ "GenSigTimeoutTime_AGSM" SG_ 1835 HVBatCellVoltage_Cell024 0;
BA_ "GenSigTimeoutTime_PBWM" SG_ 1835 HVBatCellVoltage_Cell025 0;
BA_ "GenSigTimeoutTime_IDCM" SG_ 1835 HVBatCellVoltage_Cell025 0;
BA_ "GenSigTimeoutTime_EVCU2" SG_ 1835 HVBatCellVoltage_Cell025 0;
BA_ "GenSigTimeoutTime_ECM" SG_ 1835 HVBatCellVoltage_Cell025 0;
BA_ "GenSigTimeoutTime_DMPI" SG_ 1835 HVBatCellVoltage_Cell025 0;
BA_ "GenSigTimeoutTime_BPCM" SG_ 1835 HVBatCellVoltage_Cell025 0;
BA_ "GenSigTimeoutTime_AGSM" SG_ 1835 HVBatCellVoltage_Cell025 0;
VAL_ 1328 EngTorqCapbltyMinTorq 4095 "SNA";
VAL_ 1328 EngTorqCapbltyMaxTorq 4095 "SNA";
VAL_ 1328 EngTorqCapbltyMaxOffTorq 4095 "SNA";
VAL_ 1053 VIN_MSG 0 "VIN_LO" 1 "VIN_MID" 2 "VIN_HI" 3 "SNA";
VAL_ 1058 CarbWarmUp 0 "False" 1 "True";
VAL_ 1626 IMPACTConfirm 0 "Actuate" 1 "Do_Not_Actuate";
VAL_ 1626 IMPACTCommand 0 "Do_Not_Actuate" 1 "Actuate";
VAL_ 751 EngineWaterTemp 255 "SNA";
VAL_ 1153 ExternalTemperatureC 511 "SNA";
VAL_ 1153 CmdIgnSts 0 "Initialization" 1 "IGN_LK" 3 "ACC" 4 "RUN" 5 "START" 7 "SNA";
VAL_ 1058 OAT_PT_EstV 0 "Valid" 1 "Not_Valid";
VAL_ 1058 EngOffTmPTV 1 "SNA";
VAL_ 1058 EngOffTmPT 0 "SNA";
VAL_ 1032 RadiatorFanSts 127 "SNA";
VAL_ 1033 IdleCLoopTrq 1023 "SNA";
VAL_ 1033 HCPMaxEngRPM 255 "SNA";
VAL_ 1840 IsolationResistance 65535 "SNA";
VAL_ 1838 HVBatCellVoltage_Cell096 8191 "SNA";
VAL_ 1838 HVBatCellVoltage_Cell095 8191 "SNA";
VAL_ 1838 HVBatCellVoltage_Cell094 8191 "SNA";
VAL_ 1838 HVBatCellVoltage_Cell093 8191 "SNA";
VAL_ 1838 HVBatCellVoltage_Cell092 8191 "SNA";
VAL_ 1838 HVBatCellVoltage_Cell091 8191 "SNA";
VAL_ 1838 HVBatCellVoltage_Cell090 8191 "SNA";
VAL_ 1838 HVBatCellVoltage_Cell089 8191 "SNA";
VAL_ 1838 HVBatCellVoltage_Cell088 8191 "SNA";
VAL_ 1838 HVBatCellVoltage_Cell087 8191 "SNA";
VAL_ 1838 HVBatCellVoltage_Cell086 8191 "SNA";
VAL_ 1838 HVBatCellVoltage_Cell085 8191 "SNA";
VAL_ 1838 HVBatCellVoltage_Cell084 8191 "SNA";
VAL_ 1838 HVBatCellVoltage_Cell083 8191 "SNA";
VAL_ 1838 HVBatCellVoltage_Cell082 8191 "SNA";
VAL_ 1837 HVBatCellVoltage_Cell081 8191 "SNA";
VAL_ 1837 HVBatCellVoltage_Cell080 8191 "SNA";
VAL_ 1837 HVBatCellVoltage_Cell079 8191 "SNA";
VAL_ 1837 HVBatCellVoltage_Cell078 8191 "SNA";
VAL_ 1837 HVBatCellVoltage_Cell077 8191 "SNA";
VAL_ 1837 HVBatCellVoltage_Cell076 8191 "SNA";
VAL_ 1837 HVBatCellVoltage_Cell075 8191 "SNA";
VAL_ 1837 HVBatCellVoltage_Cell074 8191 "SNA";
VAL_ 1837 HVBatCellVoltage_Cell073 8191 "SNA";
VAL_ 1837 HVBatCellVoltage_Cell072 8191 "SNA";
VAL_ 1837 HVBatCellVoltage_Cell071 8191 "SNA";
VAL_ 1837 HVBatCellVoltage_Cell070 8191 "SNA";
VAL_ 1837 HVBatCellVoltage_Cell069 8191 "SNA";
VAL_ 1837 HVBatCellVoltage_Cell068 8191 "SNA";
VAL_ 1837 HVBatCellVoltage_Cell067 8191 "SNA";
VAL_ 1837 HVBatCellVoltage_Cell066 8191 "SNA";
VAL_ 1837 HVBatCellVoltage_Cell065 8191 "SNA";
VAL_ 1837 HVBatCellVoltage_Cell064 8191 "SNA";
VAL_ 1837 HVBatCellVoltage_Cell063 8191 "SNA";
VAL_ 1837 HVBatCellVoltage_Cell062 8191 "SNA";
VAL_ 1837 HVBatCellVoltage_Cell061 8191 "SNA";
VAL_ 1837 HVBatCellVoltage_Cell060 8191 "SNA";
VAL_ 1837 HVBatCellVoltage_Cell059 8191 "SNA";
VAL_ 1837 HVBatCellVoltage_Cell058 8191 "SNA";
VAL_ 1837 HVBatCellVoltage_Cell057 8191 "SNA";
VAL_ 1837 HVBatCellVoltage_Cell056 8191 "SNA";
VAL_ 1837 HVBatCellVoltage_Cell055 8191 "SNA";
VAL_ 1836 HVBatCellVoltage_Cell054 8191 "SNA";
VAL_ 1836 HVBatCellVoltage_Cell053 8191 "SNA";
VAL_ 1836 HVBatCellVoltage_Cell052 8191 "SNA";
VAL_ 1836 HVBatCellVoltage_Cell051 8191 "SNA";
VAL_ 1836 HVBatCellVoltage_Cell050 8191 "SNA";
VAL_ 1836 HVBatCellVoltage_Cell049 8191 "SNA";
VAL_ 1836 HVBatCellVoltage_Cell048 8191 "SNA";
VAL_ 1836 HVBatCellVoltage_Cell047 8191 "SNA";
VAL_ 1836 HVBatCellVoltage_Cell046 8191 "SNA";
VAL_ 1836 HVBatCellVoltage_Cell045 8191 "SNA";
VAL_ 1836 HVBatCellVoltage_Cell044 8191 "SNA";
VAL_ 1836 HVBatCellVoltage_Cell043 8191 "SNA";
VAL_ 1836 HVBatCellVoltage_Cell042 8191 "SNA";
VAL_ 1836 HVBatCellVoltage_Cell041 8191 "SNA";
VAL_ 1836 HVBatCellVoltage_Cell040 8191 "SNA";
VAL_ 1836 HVBatCellVoltage_Cell039 8191 "SNA";
VAL_ 1836 HVBatCellVoltage_Cell038 8191 "SNA";
VAL_ 1836 HVBatCellVoltage_Cell037 8191 "SNA";
VAL_ 1836 HVBatCellVoltage_Cell036 8191 "SNA";
VAL_ 1836 HVBatCellVoltage_Cell035 8191 "SNA";
VAL_ 1836 HVBatCellVoltage_Cell034 8191 "SNA";
VAL_ 1836 HVBatCellVoltage_Cell033 8191 "SNA";
VAL_ 1836 HVBatCellVoltage_Cell032 8191 "SNA";
VAL_ 1836 HVBatCellVoltage_Cell031 8191 "SNA";
VAL_ 1836 HVBatCellVoltage_Cell030 8191 "SNA";
VAL_ 1836 HVBatCellVoltage_Cell029 8191 "SNA";
VAL_ 1836 HVBatCellVoltage_Cell028 8191 "SNA";
VAL_ 1835 HVBatCellVoltage_Cell027 8191 "SNA";
VAL_ 1835 HVBatCellVoltage_Cell026 8191 "SNA";
VAL_ 1835 HVBatCellVoltage_Cell025 8191 "SNA";
VAL_ 1835 HVBatCellVoltage_Cell024 8191 "SNA";
VAL_ 1835 HVBatCellVoltage_Cell023 8191 "SNA";
VAL_ 1835 HVBatCellVoltage_Cell022 8191 "SNA";
VAL_ 1835 HVBatCellVoltage_Cell021 8191 "SNA";
VAL_ 1835 HVBatCellVoltage_Cell020 8191 "SNA";
VAL_ 1835 HVBatCellVoltage_Cell019 8191 "SNA";
VAL_ 1835 HVBatCellVoltage_Cell018 8191 "SNA";
VAL_ 1835 HVBatCellVoltage_Cell017 8191 "SNA";
VAL_ 1835 HVBatCellVoltage_Cell016 8191 "SNA";
VAL_ 1835 HVBatCellVoltage_Cell015 8191 "SNA";
VAL_ 1835 HVBatCellVoltage_Cell014 8191 "SNA";
VAL_ 1835 HVBatCellVoltage_Cell013 8191 "SNA";
VAL_ 1835 HVBatCellVoltage_Cell012 8191 "SNA";
VAL_ 1835 HVBatCellVoltage_Cell011 8191 "SNA";
VAL_ 1835 HVBatCellVoltage_Cell010 8191 "SNA";
VAL_ 1835 HVBatCellVoltage_Cell009 8191 "SNA";
VAL_ 1835 HVBatCellVoltage_Cell008 8191 "SNA";
VAL_ 1835 HVBatCellVoltage_Cell007 8191 "SNA";
VAL_ 1835 HVBatCellVoltage_Cell006 8191 "SNA";
VAL_ 1835 HVBatCellVoltage_Cell005 8191 "SNA";
VAL_ 1835 HVBatCellVoltage_Cell004 8191 "SNA";
VAL_ 1835 HVBatCellVoltage_Cell003 8191 "SNA";
VAL_ 1835 HVBatCellVoltage_Cell002 8191 "SNA";
VAL_ 1835 HVBatCellVoltage_Cell001 8191 "SNA";
VAL_ 1328 EngTorqCapbltyMinRunTorq 4095 "SNA";
VAL_ 1328 EngTorqACCCapability 255 "SNA";
VAL_ 1035 PECP_PumpFlowReq 127 "SNA";
VAL_ 1035 EngSpdStat 0 "NOR_OPR" 1 "DEG_OPR" 3 "SNA";
VAL_ 1035 EngCltTmpV 0 "False" 1 "True";
VAL_ 1035 EngCltTmp 255 "SNA";
VAL_ 518 RPMOverRev_W 0 "FALSE" 1 "TRUE";
VAL_ 518 ECM_READINESS_RESET_W 0 "Not Set" 1 "Set";
VAL_ 518 ECM_CODE_CLR_W 0 "Not Cleared" 1 "Cleared";
VAL_ 1066 ExternalTemperature 511 "SNA";
VAL_ 750 Battery_Volt_1 511 "SNA";
VAL_ 267 HCP_ShutdownCommand 0 "default" 1 "Initiate_Powerdown" 2 "Shutdown" 3 "Cancel_Powerdown" 7 "SNA";
VAL_ 156 GPS_UTC_Second 65535 "SNA";
VAL_ 156 GPS_UTC_Minute 255 "SNA";
VAL_ 156 GPS_UTC_Hour 255 "SNA";
VAL_ 156 GPS_Date_Year 65535 "SNA";
VAL_ 156 GPS_Date_Month 255 "SNA";
VAL_ 156 GPS_Date_Day 255 "SNA";
VAL_ 269 PropulsionMode 0 "Hybrid_Parallel" 1 "EV_Only" 2 "Hybrid_Series" 7 "SNA";
VAL_ 1036 EngineOilTemperature 255 "SNA";
VAL_ 269 HybridEngineMaxTorqAllowed 4095 "SNA";
VAL_ 2654486529 CBV_bit6_PartialNtwInfBit 0 "NM_PDU_contains_no_Partial_Network_request_information" 1 "NM_PDU_contains_Partial_Network_request_information";
VAL_ 2654486640 CBV_bit6_PartialNtwInfBit 0 "NM_PDU_contains_no_Partial_Network_request_information" 1 "NM_PDU_contains_Partial_Network_request_information";
VAL_ 2654486640 CBV_bit4_ActiveWakeupBit 0 "PassiveWakeup" 1 "ActiveWakeup";
VAL_ 2654486529 CBV_bit4_ActiveWakeupBit 0 "PassiveWakeup" 1 "ActiveWakeup";
VAL_ 2654486529 CBV_bit3_NMCoordinatorBit 0 "Start_of_synchronized_shutdown_is_not_requested_by_main_coordinator" 1 "Start_of_synchronized_shutdown_is_requested_by_main_coordinator";
VAL_ 2654486640 CBV_bit3_NMCoordinatorBit 0 "Start_of_synchronized_shutdown_is_not_requested_by_main_coordinator" 1 "Start_of_synchronized_shutdown_is_requested_by_main_coordinator";
VAL_ 2654486640 CBV_bit0_RepeatMessageRequestBit 0 "Repeat_Message_State_not_requested" 1 "Repeat_Message_State_requested";
VAL_ 2654486529 CBV_bit0_RepeatMessageRequestBit 0 "Repeat_Message_State_not_requested" 1 "Repeat_Message_State_requested";
VAL_ 1033 Hybrid_EVT_ModeSts 0 "Hybrid Mode" 1 "EVT Mode";
VAL_ 269 REPRGD_PFC_CLR_HCP 0 "Do Nothing" 1 "Set Incomplete";
VAL_ 269 CODE_CLR_HCP 0 "Not Clear" 1 "Clear";
VAL_ 1838 HVBatCellVoltage_Cell108 8191 "SNA";
VAL_ 1838 HVBatCellVoltage_Cell107 8191 "SNA";
VAL_ 1838 HVBatCellVoltage_Cell106 8191 "SNA";
VAL_ 1838 HVBatCellVoltage_Cell105 8191 "SNA";
VAL_ 1838 HVBatCellVoltage_Cell104 8191 "SNA";
VAL_ 1838 HVBatCellVoltage_Cell103 8191 "SNA";
VAL_ 1838 HVBatCellVoltage_Cell102 8191 "SNA";
VAL_ 1838 HVBatCellVoltage_Cell101 8191 "SNA";
VAL_ 1838 HVBatCellVoltage_Cell100 8191 "SNA";
VAL_ 1838 HVBatCellVoltage_Cell099 8191 "SNA";
VAL_ 1838 HVBatCellVoltage_Cell098 8191 "SNA";
VAL_ 1838 HVBatCellVoltage_Cell097 8191 "SNA";
VAL_ 1840 Warning_SOCJump 0 "Normal" 1 "Warning";
VAL_ 1840 Warning_PackUnmatched 0 "Normal" 1 "Warning";
VAL_ 1840 Warning_PackUndervoltage 0 "Normal" 1 "Warning";
VAL_ 1840 Warning_PackTempHigh 0 "Normal" 1 "Warning";
VAL_ 1840 Warning_PackTempDiff 0 "Normal" 1 "Warning";
VAL_ 1840 Warning_PackOvervoltage 0 "Normal" 1 "Warning";
VAL_ 1840 Warning_Overcharging 0 "Normal" 1 "Warning";
VAL_ 1840 Warning_LowSOC 0 "Normal" 1 "Warning";
VAL_ 1840 Warning_Insulation 0 "Normal" 1 "Warning";
VAL_ 1840 Warning_HVIL 0 "Normal" 1 "Warning";
VAL_ 1840 Warning_HighSOC 0 "Normal" 1 "Warning";
VAL_ 1840 Warning_CellUndervoltage 0 "Normal" 1 "Warning";
VAL_ 1840 Warning_CellOvervoltage 0 "Normal" 1 "Warning";
VAL_ 1840 Warning_CellBalance 0 "Normal" 1 "Warning";
VAL_ 1840 HighestWarningLevel 0 "No_Faults" 1 "Level_1" 2 "Level_2" 3 "Level_3";
VAL_ 1328 CatTempMaint 0 "Not_Active" 1 "Active";
VAL_ 753 IDCM_Wakeup_HCP 0 "No_Event" 1 "WakeUp_Event";
VAL_ 1839 HVBatModuleTemp_16 255 "SNA";
VAL_ 1839 HVBatModuleTemp_15 255 "SNA";
VAL_ 1839 HVBatModuleTemp_14 255 "SNA";
VAL_ 1839 HVBatModuleTemp_13 255 "SNA";
VAL_ 1839 HVBatModuleTemp_12 255 "SNA";
VAL_ 1839 HVBatModuleTemp_11 255 "SNA";
VAL_ 1839 HVBatModuleTemp_10 255 "SNA";
VAL_ 1839 HVBatModuleTemp_09 255 "SNA";
VAL_ 1839 HVBatModuleTemp_08 255 "SNA";
VAL_ 1839 HVBatModuleTemp_07 255 "SNA";
VAL_ 1839 HVBatModuleTemp_06 255 "SNA";
VAL_ 1839 HVBatModuleTemp_05 255 "SNA";
VAL_ 1839 HVBatModuleTemp_04 255 "SNA";
VAL_ 1839 HVBatModuleTemp_03 255 "SNA";
VAL_ 1839 HVBatModuleTemp_02 255 "SNA";
VAL_ 1839 HVBatModuleTemp_01 255 "SNA";
VAL_ 1839 HVBatModuleTemp_38 255 "SNA";
VAL_ 1839 HVBatModuleTemp_37 255 "SNA";
VAL_ 1839 HVBatModuleTemp_36 255 "SNA";
VAL_ 1839 HVBatModuleTemp_35 255 "SNA";
VAL_ 1839 HVBatModuleTemp_34 255 "SNA";
VAL_ 1839 HVBatModuleTemp_33 255 "SNA";
VAL_ 1839 HVBatModuleTemp_32 255 "SNA";
VAL_ 1839 HVBatModuleTemp_31 255 "SNA";
VAL_ 1839 HVBatModuleTemp_30 255 "SNA";
VAL_ 1839 HVBatModuleTemp_29 255 "SNA";
VAL_ 1839 HVBatModuleTemp_28 255 "SNA";
VAL_ 1839 HVBatModuleTemp_27 255 "SNA";
VAL_ 1839 HVBatModuleTemp_26 255 "SNA";
VAL_ 1839 HVBatModuleTemp_25 255 "SNA";
VAL_ 1839 HVBatModuleTemp_24 255 "SNA";
VAL_ 1839 HVBatModuleTemp_23 255 "SNA";
VAL_ 1839 HVBatModuleTemp_22 255 "SNA";
VAL_ 1839 HVBatModuleTemp_21 255 "SNA";
VAL_ 1839 HVBatModuleTemp_20 255 "SNA";
VAL_ 1839 HVBatModuleTemp_19 255 "SNA";
VAL_ 1839 HVBatModuleTemp_18 255 "SNA";
VAL_ 1839 HVBatModuleTemp_17 255 "SNA";
VAL_ 1035 ECM_AirflowRequest 127 "SNA";
VAL_ 1033 HCP_HoodAjar 0 "Closed" 1 "Ajar" 2 "Faulted" 3 "SNA";
SIG_GROUP_ 1033 HYBRID_POWERTRAIN5_Pkt 1 : IdleCLoopTrq HEV_HybPwrtrnRdcdPerfCmnd HCPMaxEngRPM MessageCounter_HYBRID_POWERTRAI CRC_HYBRID_POWERTRAIN5 Hybrid_EVT_ModeSts HCP_HoodAjar;
SIG_GROUP_ 269 HYBRID_POWERTRAIN2_Pkt 1 : MessageCounter_HYBRID_POWERTRAI IdleSpeedActiveSts CRC_HYBRID_POWERTRAIN2 PropulsionMode HybridEngineMaxTorqAllowed REPRGD_PFC_CLR_HCP CODE_CLR_HCP;
SIG_GROUP_ 1058 OBD_CONTENT_FRAME_Pkt 1 : EngLoad_OBD_ePT LoadOBD CarbWarmUp OAT_PT_EstV OAT_PT_Est EngOffTmPTV EngOffTmPT MessageCounter_OBDCONTENTFRAME CRC_OBDCONTENTFRAME;
SIG_GROUP_ 1626 IMPACT_INFO_Pkt 1 : CRC_IMPACTINFO MessageCounter_IMPACTINFO IMPACTConfirm IMPACTCommand;
SIG_GROUP_ 751 ENGINE_FD_6_Pkt 1 : EngineWaterTemp;
SIG_GROUP_ 518 ENGINE_FD_5_Pkt 1 : RPMOverRev_W MessageCounter_ENGINE5 ECM_READINESS_RESET_W ECM_CODE_CLR_W CRC_ENGINE5;
SIG_GROUP_ 266 HVBATTERY1_Pkt 1 : REPRGD_PFC_CLR_BPCM CODE_CLR_BPCM;
SIG_GROUP_ 1328 ENGINE_HYBD_FD_4_Pkt 1 : EngTorqCapbltyMinTorq EngTorqCapbltyMaxTorq EngTorqCapbltyMaxOffTorq EngTorqCapbltyRefEngSpd EngTorqCapbltyMinRunTorq EngTorqCapbltyFrmCntr EngTorqACCCapability CatHtgStateActive MessageCounter_ENGINE_HYBD_FD_4 CRC_ENGINE_HYBD_FD_4 CatTempMaint;
SIG_GROUP_ 1035 ENGINE_HYBD_FD_3_Pkt 1 : MaxEngSpdCap ServiceHybSys PECP_PumpFlowReq MinEngSpdCap EngSpdStat EngSpd EngOutofFuel EngCltTmpV EngCltTmp MessageCounter_ENGINE_HYBD_FD_3 CRC_ENGINE_HYBD_FD_3 ECM_AirflowRequest;
SIG_GROUP_ 1036 ENGINE_FD_3_Pkt 1 : EngineOilTemperature;
